VERSION "PrivateInfoCAN"

NS_ :

BS_ :

BU_ :  AUD ETC IHU PDCM

BO_ 896 AUDInfoCanFr01 : 8 AUD
 SG_ AcoustModSts : 7|2@0+ (1,0) [0|3] "" IHU
 SG_ AcoustModSts_UB : 38|1@0+ (1,0) [0|1] "" IHU
 SG_ AudioMuteSts : 15|1@0+ (1,0) [0|1] "" IHU
 SG_ AudioMuteSts_UB : 63|1@0+ (1,0) [0|1] "" IHU
 SG_ BalLvlSts : 4|5@0+ (1.0,0.0) [0.0|31.0] "Unitless" IHU
 SG_ BalLvlSts_UB : 5|1@0+ (1,0) [0|1] "" IHU
 SG_ FaderLvlSts : 12|5@0+ (1.0,0.0) [0.0|31.0] "Unitless" IHU
 SG_ FaderLvlSts_UB : 13|1@0+ (1,0) [0|1] "" IHU
 SG_ Fgrnd1stForActvtSts : 23|1@0+ (1,0) [0|1] "" IHU
 SG_ Fgrnd1stForActvtSts_UB : 62|1@0+ (1,0) [0|1] "" IHU
 SG_ Fgrnd2ndForActvtSts : 31|1@0+ (1,0) [0|1] "" IHU
 SG_ Fgrnd2ndForActvtSts_UB : 61|1@0+ (1,0) [0|1] "" IHU
 SG_ LvlOfBassSts : 20|5@0+ (1.0,0.0) [0.0|31.0] "Unitless" IHU
 SG_ LvlOfBassSts_UB : 21|1@0+ (1,0) [0|1] "" IHU
 SG_ LvlOfMidSts : 28|5@0+ (1.0,0.0) [0.0|31.0] "Unitless" IHU
 SG_ LvlOfMidSts_UB : 29|1@0+ (1,0) [0|1] "" IHU
 SG_ LvlOfTrebleSts : 36|5@0+ (1.0,0.0) [0.0|31.0] "Unitless" IHU
 SG_ LvlOfTrebleSts_UB : 37|1@0+ (1,0) [0|1] "" IHU
 SG_ RoomModeSts : 47|4@0+ (1,0) [0|15] "" IHU
 SG_ RoomModeSts_UB : 39|1@0+ (1,0) [0|1] "" IHU
 SG_ SeatSoundPosnSts : 55|3@0+ (1.0,0.0) [0.0|7.0] "Unitless" IHU
 SG_ SeatSoundPosnSts_UB : 52|1@0+ (1,0) [0|1] "" IHU
 SG_ VehSpdLvlSts : 51|3@0+ (1.0,0.0) [0.0|7.0] "Unitless" IHU
 SG_ VehSpdLvlSts_UB : 48|1@0+ (1,0) [0|1] "" IHU

BO_ 897 AUDInfoCanFr02 : 8 AUD
 SG_ BgrndForAudOutChSts_UB : 57|1@0+ (1,0) [0|1] "" IHU
 SG_ BgrndForAudOutChStsAudOutpCh1 : 32|1@0+ (1,0) [0|1] "" IHU
 SG_ BgrndForAudOutChStsAudOutpCh10 : 36|1@0+ (1,0) [0|1] "" IHU
 SG_ BgrndForAudOutChStsAudOutpCh11 : 34|1@0+ (1,0) [0|1] "" IHU
 SG_ BgrndForAudOutChStsAudOutpCh12 : 33|1@0+ (1,0) [0|1] "" IHU
 SG_ BgrndForAudOutChStsAudOutpCh2 : 39|1@0+ (1,0) [0|1] "" IHU
 SG_ BgrndForAudOutChStsAudOutpCh3 : 46|1@0+ (1,0) [0|1] "" IHU
 SG_ BgrndForAudOutChStsAudOutpCh4 : 38|1@0+ (1,0) [0|1] "" IHU
 SG_ BgrndForAudOutChStsAudOutpCh5 : 44|1@0+ (1,0) [0|1] "" IHU
 SG_ BgrndForAudOutChStsAudOutpCh6 : 45|1@0+ (1,0) [0|1] "" IHU
 SG_ BgrndForAudOutChStsAudOutpCh7 : 47|1@0+ (1,0) [0|1] "" IHU
 SG_ BgrndForAudOutChStsAudOutpCh8 : 37|1@0+ (1,0) [0|1] "" IHU
 SG_ BgrndForAudOutChStsAudOutpCh9 : 35|1@0+ (1,0) [0|1] "" IHU
 SG_ Fgrnd1stForAudOutpChSts_UB : 56|1@0+ (1,0) [0|1] "" IHU
 SG_ Fgrnd1stForAudOutpChStsAudOutpCh1 : 54|1@0+ (1,0) [0|1] "" IHU
 SG_ Fgrnd1stForAudOutpChStsAudOutpCh10 : 49|1@0+ (1,0) [0|1] "" IHU
 SG_ Fgrnd1stForAudOutpChStsAudOutpCh11 : 55|1@0+ (1,0) [0|1] "" IHU
 SG_ Fgrnd1stForAudOutpChStsAudOutpCh12 : 48|1@0+ (1,0) [0|1] "" IHU
 SG_ Fgrnd1stForAudOutpChStsAudOutpCh2 : 42|1@0+ (1,0) [0|1] "" IHU
 SG_ Fgrnd1stForAudOutpChStsAudOutpCh3 : 53|1@0+ (1,0) [0|1] "" IHU
 SG_ Fgrnd1stForAudOutpChStsAudOutpCh4 : 43|1@0+ (1,0) [0|1] "" IHU
 SG_ Fgrnd1stForAudOutpChStsAudOutpCh5 : 52|1@0+ (1,0) [0|1] "" IHU
 SG_ Fgrnd1stForAudOutpChStsAudOutpCh6 : 51|1@0+ (1,0) [0|1] "" IHU
 SG_ Fgrnd1stForAudOutpChStsAudOutpCh7 : 50|1@0+ (1,0) [0|1] "" IHU
 SG_ Fgrnd1stForAudOutpChStsAudOutpCh8 : 41|1@0+ (1,0) [0|1] "" IHU
 SG_ Fgrnd1stForAudOutpChStsAudOutpCh9 : 40|1@0+ (1,0) [0|1] "" IHU
 SG_ Fgrnd1stForVolLvlSts : 7|8@0+ (1.0,0.0) [0.0|255.0] "Unitless" IHU
 SG_ Fgrnd1stForVolLvlSts_UB : 22|1@0+ (1,0) [0|1] "" IHU
 SG_ Fgrnd2ndForAudOutpChSts_UB : 20|1@0+ (1,0) [0|1] "" IHU
 SG_ Fgrnd2ndForAudOutpChStsAudOutpCh1 : 19|1@0+ (1,0) [0|1] "" IHU
 SG_ Fgrnd2ndForAudOutpChStsAudOutpCh10 : 26|1@0+ (1,0) [0|1] "" IHU
 SG_ Fgrnd2ndForAudOutpChStsAudOutpCh11 : 25|1@0+ (1,0) [0|1] "" IHU
 SG_ Fgrnd2ndForAudOutpChStsAudOutpCh12 : 24|1@0+ (1,0) [0|1] "" IHU
 SG_ Fgrnd2ndForAudOutpChStsAudOutpCh2 : 18|1@0+ (1,0) [0|1] "" IHU
 SG_ Fgrnd2ndForAudOutpChStsAudOutpCh3 : 17|1@0+ (1,0) [0|1] "" IHU
 SG_ Fgrnd2ndForAudOutpChStsAudOutpCh4 : 16|1@0+ (1,0) [0|1] "" IHU
 SG_ Fgrnd2ndForAudOutpChStsAudOutpCh5 : 31|1@0+ (1,0) [0|1] "" IHU
 SG_ Fgrnd2ndForAudOutpChStsAudOutpCh6 : 30|1@0+ (1,0) [0|1] "" IHU
 SG_ Fgrnd2ndForAudOutpChStsAudOutpCh7 : 29|1@0+ (1,0) [0|1] "" IHU
 SG_ Fgrnd2ndForAudOutpChStsAudOutpCh8 : 28|1@0+ (1,0) [0|1] "" IHU
 SG_ Fgrnd2ndForAudOutpChStsAudOutpCh9 : 27|1@0+ (1,0) [0|1] "" IHU
 SG_ Fgrnd2ndForVolLvlSts : 15|8@0+ (1.0,0.0) [0.0|255.0] "Unitless" IHU
 SG_ Fgrnd2ndForVolLvlSts_UB : 23|1@0+ (1,0) [0|1] "" IHU

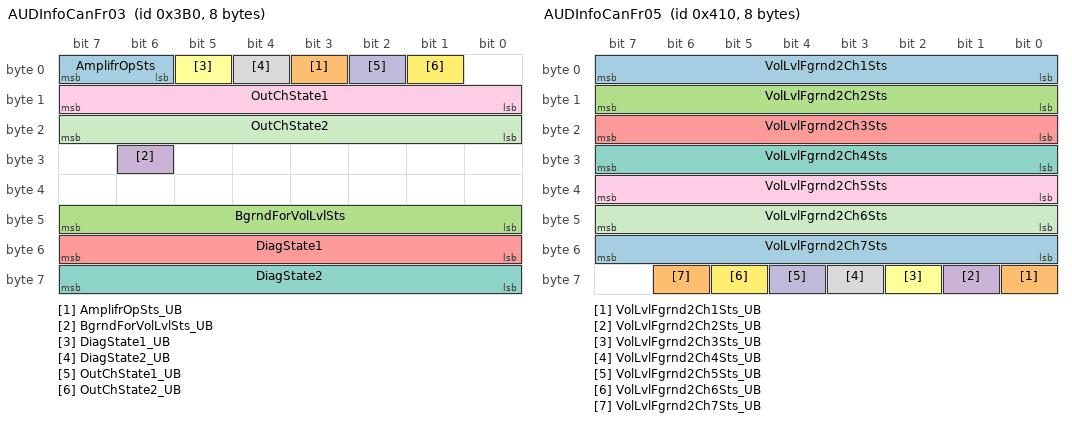
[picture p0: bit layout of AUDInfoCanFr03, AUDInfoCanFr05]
BO_ 944 AUDInfoCanFr03 : 8 AUD
 SG_ AmplifrOpSts : 7|2@0+ (1,0) [0|3] "" IHU
 SG_ AmplifrOpSts_UB : 3|1@0+ (1,0) [0|1] "" IHU
 SG_ BgrndForVolLvlSts : 47|8@0+ (1.0,0.0) [0.0|255.0] "Unitless" IHU
 SG_ BgrndForVolLvlSts_UB : 30|1@0+ (1,0) [0|1] "" IHU
 SG_ DiagState1 : 55|8@0+ (1.0,0.0) [0.0|255.0] "Unitless" IHU
 SG_ DiagState1_UB : 5|1@0+ (1,0) [0|1] "" IHU
 SG_ DiagState2 : 63|8@0+ (1.0,0.0) [0.0|255.0] "Unitless" IHU
 SG_ DiagState2_UB : 4|1@0+ (1,0) [0|1] "" IHU
 SG_ OutChState1 : 15|8@0+ (1.0,0.0) [0.0|255.0] "Unitless" IHU
 SG_ OutChState1_UB : 2|1@0+ (1,0) [0|1] "" IHU
 SG_ OutChState2 : 23|8@0+ (1.0,0.0) [0.0|255.0] "Unitless" IHU
 SG_ OutChState2_UB : 1|1@0+ (1,0) [0|1] "" IHU

BO_ 912 AUDInfoCanFr04 : 8 AUD
 SG_ ArtificialSoundPreviewSts : 53|2@0+ (1,0) [0|3] "" IHU
 SG_ ArtificialSoundPreviewSts_UB : 54|1@0+ (1,0) [0|1] "" IHU
 SG_ Chiming1MuteSts : 35|1@0+ (1,0) [0|1] "" IHU
 SG_ Chiming1MuteSts_UB : 47|1@0+ (1,0) [0|1] "" IHU
 SG_ Chiming2MuteSts : 34|1@0+ (1,0) [0|1] "" IHU
 SG_ Chiming2MuteSts_UB : 46|1@0+ (1,0) [0|1] "" IHU
 SG_ Chiming3MuteSts : 33|1@0+ (1,0) [0|1] "" IHU
 SG_ Chiming3MuteSts_UB : 45|1@0+ (1,0) [0|1] "" IHU
 SG_ Chiming4MuteSts : 32|1@0+ (1,0) [0|1] "" IHU
 SG_ Chiming4MuteSts_UB : 44|1@0+ (1,0) [0|1] "" IHU
 SG_ GearBoxTypToAmplfrSts : 63|8@0+ (1.0,0.0) [0.0|255.0] "Unitless" IHU
 SG_ GearBoxTypToAmplfrSts_UB : 51|1@0+ (1,0) [0|1] "" IHU
 SG_ SeatMtrlToAmplfrSts : 7|8@0+ (1.0,0.0) [0.0|255.0] "Unitless" IHU
 SG_ SeatMtrlToAmplfrSts_UB : 39|1@0+ (1,0) [0|1] "" IHU
 SG_ SeatNrToAmplfrSts : 15|8@0+ (1.0,0.0) [0.0|255.0] "Unitless" IHU
 SG_ SeatNrToAmplfrSts_UB : 38|1@0+ (1,0) [0|1] "" IHU
 SG_ SpkrandAmplifrVariantTypeSts : 23|8@0+ (1.0,0.0) [0.0|255.0] "Unitless" IHU
 SG_ SpkrandAmplifrVariantTypeSts_UB : 37|1@0+ (1,0) [0|1] "" IHU
 SG_ TrdRowSeatMtrlToAmplfrSts : 31|8@0+ (1.0,0.0) [0.0|255.0] "Unitless" IHU
 SG_ TrdRowSeatMtrlToAmplfrSts_UB : 36|1@0+ (1,0) [0|1] "" IHU
 SG_ WarnIntrptLoglDHUSts : 43|4@0+ (1.0,0.0) [0.0|15.0] "Unitless" IHU
 SG_ WarnIntrptLoglDHUSts_UB : 55|1@0+ (1,0) [0|1] "" IHU

BO_ 1040 AUDInfoCanFr05 : 8 AUD
 SG_ VolLvlFgrnd2Ch1Sts : 7|8@0+ (1.0,0.0) [0.0|255.0] "Unitless" IHU
 SG_ VolLvlFgrnd2Ch1Sts_UB : 56|1@0+ (1,0) [0|1] "" IHU
 SG_ VolLvlFgrnd2Ch2Sts : 15|8@0+ (1.0,0.0) [0.0|255.0] "Unitless" IHU
 SG_ VolLvlFgrnd2Ch2Sts_UB : 57|1@0+ (1,0) [0|1] "" IHU
 SG_ VolLvlFgrnd2Ch3Sts : 23|8@0+ (1.0,0.0) [0.0|255.0] "Unitless" IHU
 SG_ VolLvlFgrnd2Ch3Sts_UB : 58|1@0+ (1,0) [0|1] "" IHU
 SG_ VolLvlFgrnd2Ch4Sts : 31|8@0+ (1.0,0.0) [0.0|255.0] "Unitless" IHU
 SG_ VolLvlFgrnd2Ch4Sts_UB : 59|1@0+ (1,0) [0|1] "" IHU
 SG_ VolLvlFgrnd2Ch5Sts : 39|8@0+ (1.0,0.0) [0.0|255.0] "Unitless" IHU
 SG_ VolLvlFgrnd2Ch5Sts_UB : 60|1@0+ (1,0) [0|1] "" IHU
 SG_ VolLvlFgrnd2Ch6Sts : 47|8@0+ (1.0,0.0) [0.0|255.0] "Unitless" IHU
 SG_ VolLvlFgrnd2Ch6Sts_UB : 61|1@0+ (1,0) [0|1] "" IHU
 SG_ VolLvlFgrnd2Ch7Sts : 55|8@0+ (1.0,0.0) [0.0|255.0] "Unitless" IHU
 SG_ VolLvlFgrnd2Ch7Sts_UB : 62|1@0+ (1,0) [0|1] "" IHU

BO_ 80 AUDInfoCanFr06 : 8 AUD
 SG_ AcoustEfectPrvtCinePsnSts : 55|2@0+ (1,0) [0|3] "" IHU
 SG_ AcoustEfectPrvtCinePsnSts_UB : 53|1@0+ (1,0) [0|1] "" IHU
 SG_ BgrndForActvtSts : 51|1@0+ (1,0) [0|1] "" IHU
 SG_ BgrndForActvtSts_UB : 57|1@0+ (1,0) [0|1] "" IHU
 SG_ CptAdvExtSwtSts : 63|2@0+ (1,0) [0|3] "" IHU
 SG_ CptAdvExtSwtSts_UB : 56|1@0+ (1,0) [0|1] "" IHU
 SG_ Feedback1SelectSts : 47|4@0+ (1,0) [0|15] "" IHU
 SG_ Feedback1SelectSts_UB : 58|1@0+ (1,0) [0|1] "" IHU
 SG_ Feedback2SelectSts : 43|4@0+ (1,0) [0|15] "" IHU
 SG_ Feedback2SelectSts_UB : 59|1@0+ (1,0) [0|1] "" IHU
 SG_ VolLvlFgrnd2Ch10Sts : 7|8@0+ (1.0,0.0) [0.0|255.0] "Unitless" IHU
 SG_ VolLvlFgrnd2Ch10Sts_UB : 48|1@0+ (1,0) [0|1] "" IHU
 SG_ VolLvlFgrnd2Ch11Sts : 15|8@0+ (1.0,0.0) [0.0|255.0] "Unitless" IHU
 SG_ VolLvlFgrnd2Ch11Sts_UB : 49|1@0+ (1,0) [0|1] "" IHU
 SG_ VolLvlFgrnd2Ch12Sts : 23|8@0+ (1.0,0.0) [0.0|255.0] "Unitless" IHU
 SG_ VolLvlFgrnd2Ch12Sts_UB : 50|1@0+ (1,0) [0|1] "" IHU
 SG_ VolLvlFgrnd2Ch8Sts : 31|8@0+ (1.0,0.0) [0.0|255.0] "Unitless" IHU
 SG_ VolLvlFgrnd2Ch8Sts_UB : 60|1@0+ (1,0) [0|1] "" IHU
 SG_ VolLvlFgrnd2Ch9Sts : 39|8@0+ (1.0,0.0) [0.0|255.0] "Unitless" IHU
 SG_ VolLvlFgrnd2Ch9Sts_UB : 61|1@0+ (1,0) [0|1] "" IHU

BO_ 33 AUDInfoCanFr07 : 8 AUD
 SG_ AllmuteSts : 54|1@0+ (1,0) [0|1] "" IHU
 SG_ AllmuteSts_UB : 53|1@0+ (1,0) [0|1] "" IHU
 SG_ AmplifrErrSts : 19|4@0+ (1.0,0.0) [0.0|15.0] "Unitless" IHU
 SG_ AmplifrErrSts_UB : 48|1@0+ (1,0) [0|1] "" IHU
 SG_ ArtificialSoundOpenReqSts : 20|1@0+ (1,0) [0|1] "" IHU
 SG_ ArtificialSoundOpenReqSts_UB : 58|1@0+ (1,0) [0|1] "" IHU
 SG_ ArtificialSoundSelectReqSts : 23|3@0+ (1,0) [0|7] "" IHU
 SG_ ArtificialSoundSelectReqSts_UB : 57|1@0+ (1,0) [0|1] "" IHU
 SG_ BdyTypToAmplfrSts : 39|8@0+ (1.0,0.0) [0.0|255.0] "Unitless" IHU
 SG_ BdyTypToAmplfrSts_UB : 56|1@0+ (1,0) [0|1] "" IHU
 SG_ EngTypToAmplfrSts : 47|8@0+ (1.0,0.0) [0.0|255.0] "Unitless" IHU
 SG_ EngTypToAmplfrSts_UB : 55|1@0+ (1,0) [0|1] "" IHU
 SG_ NaviMuteSts : 52|1@0+ (1,0) [0|1] "" IHU
 SG_ NaviMuteSts_UB : 51|1@0+ (1,0) [0|1] "" IHU
 SG_ PrpsnTypToAmplfrSts : 31|4@0+ (1.0,0.0) [0.0|15.0] "Unitless" IHU
 SG_ PrpsnTypToAmplfrSts_UB : 11|1@0+ (1,0) [0|1] "" IHU
 SG_ SteerWhlPosnToAmplfrSts : 7|8@0+ (1.0,0.0) [0.0|255.0] "Unitless" IHU
 SG_ SteerWhlPosnToAmplfrSts_UB : 60|1@0+ (1,0) [0|1] "" IHU
 SG_ TeleMuteSts : 50|1@0+ (1,0) [0|1] "" IHU
 SG_ TeleMuteSts_UB : 49|1@0+ (1,0) [0|1] "" IHU

BO_ 949 AUDInfoCanFr08 : 8 AUD
 SG_ OutChState3 : 7|8@0+ (1.0,0.0) [0.0|255.0] "Unitless" IHU
 SG_ OutChState3_UB : 23|1@0+ (1,0) [0|1] "" IHU
 SG_ OutChState4 : 15|8@0+ (1.0,0.0) [0.0|255.0] "Unitless" IHU
 SG_ OutChState4_UB : 22|1@0+ (1,0) [0|1] "" IHU
 SG_ VolLvlFgrnd0Sts : 31|8@0+ (1.0,0.0) [0.0|255.0] "Unitless" IHU
 SG_ VolLvlFgrnd0Sts_UB : 21|1@0+ (1,0) [0|1] "" IHU

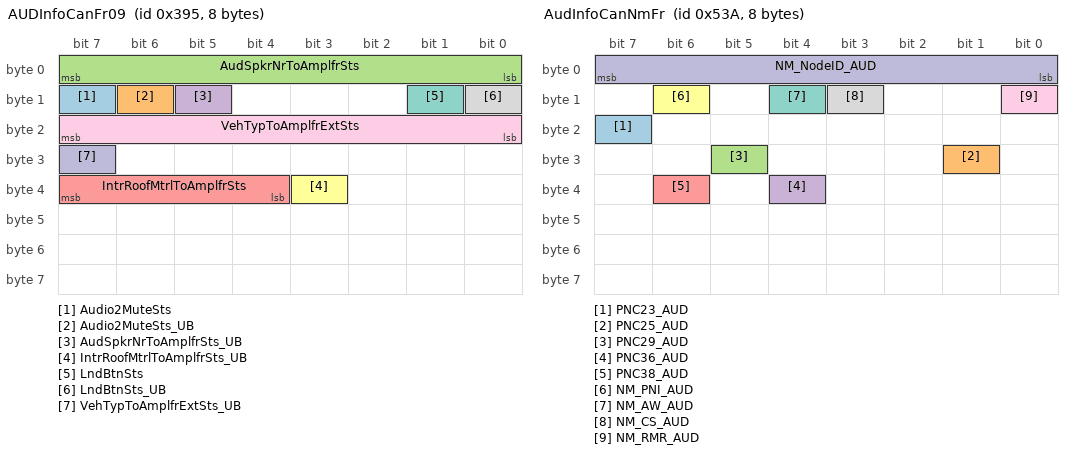
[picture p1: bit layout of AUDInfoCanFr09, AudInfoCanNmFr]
BO_ 917 AUDInfoCanFr09 : 8 AUD
 SG_ Audio2MuteSts : 15|1@0+ (1,0) [0|1] "" IHU
 SG_ Audio2MuteSts_UB : 14|1@0+ (1,0) [0|1] "" IHU
 SG_ AudSpkrNrToAmplfrSts : 7|8@0+ (1.0,0.0) [0.0|255.0] "Unitless" IHU
 SG_ AudSpkrNrToAmplfrSts_UB : 13|1@0+ (1,0) [0|1] "" IHU
 SG_ IntrRoofMtrlToAmplfrSts : 39|4@0+ (1.0,0.0) [0.0|15.0] "Unitless" IHU
 SG_ IntrRoofMtrlToAmplfrSts_UB : 35|1@0+ (1,0) [0|1] "" IHU
 SG_ LndBtnSts : 9|1@0+ (1,0) [0|1] "" IHU
 SG_ LndBtnSts_UB : 8|1@0+ (1,0) [0|1] "" IHU
 SG_ VehTypToAmplfrExtSts : 23|8@0+ (1.0,0.0) [0.0|255.0] "Unitless" IHU
 SG_ VehTypToAmplfrExtSts_UB : 31|1@0+ (1,0) [0|1] "" IHU

BO_ 293 AUDInfoCanFr11 : 8 AUD
 SG_ VolLvlA7Sts : 7|8@0+ (1.0,0.0) [0.0|255.0] "Unitless" IHU
 SG_ VolLvlA7Sts_UB : 23|1@0+ (1,0) [0|1] "" IHU
 SG_ VolLvlA8Sts : 15|8@0+ (1.0,0.0) [0.0|255.0] "Unitless" IHU
 SG_ VolLvlA8Sts_UB : 22|1@0+ (1,0) [0|1] "" IHU

BO_ 1338 AudInfoCanNmFr : 8 AUD
 SG_ PNC23_AUD : 23|1@0+ (1,0) [0|0] "" Vector__XXX
 SG_ PNC25_AUD : 25|1@0+ (1,0) [0|0] "" Vector__XXX
 SG_ PNC29_AUD : 29|1@0+ (1,0) [0|0] "" Vector__XXX
 SG_ PNC36_AUD : 36|1@0+ (1,0) [0|0] "" Vector__XXX
 SG_ PNC38_AUD : 38|1@0+ (1,0) [0|0] "" Vector__XXX
 SG_ NM_PNI_AUD : 14|1@0+ (1,0) [0|0] "" Vector__XXX
 SG_ NM_AW_AUD : 12|1@0+ (1,0) [0|0] "" Vector__XXX
 SG_ NM_CS_AUD : 11|1@0+ (1,0) [0|0] "" Vector__XXX
 SG_ NM_RMR_AUD : 8|1@0+ (1,0) [0|0] "" Vector__XXX
 SG_ NM_NodeID_AUD : 7|8@0+ (1,0) [0|0] "" Vector__XXX

BO_ 1554 AudToDhuInfoCanDiagResFrame : 8 AUD

BO_ 820 CemBodyFr93 : 8 IHU
 SG_ ExtrLtgSts_UB : 4|1@0+ (1,0) [0|1] "" Vector__XXX
 SG_ ExtrLtgStsAFS : 23|2@0+ (1,0) [0|3] "" Vector__XXX
 SG_ ExtrLtgStsAHBC : 21|2@0+ (1,0) [0|3] "" Vector__XXX
 SG_ ExtrLtgStsAHL : 19|2@0+ (1,0) [0|3] "" Vector__XXX
 SG_ ExtrLtgStsAllWL : 17|2@0+ (1,0) [0|3] "" Vector__XXX
 SG_ ExtrLtgStsApproach : 31|2@0+ (1,0) [0|3] "" Vector__XXX
 SG_ ExtrLtgStsChks : 15|8@0+ (1.0,0.0) [0.0|255.0] "Unitless" Vector__XXX
 SG_ ExtrLtgStsCntr : 3|4@0+ (1.0,0.0) [0.0|15.0] "Unitless" Vector__XXX
 SG_ ExtrLtgStsCornrgLi : 29|2@0+ (1,0) [0|3] "" Vector__XXX
 SG_ ExtrLtgStsDBL : 27|2@0+ (1,0) [0|3] "" Vector__XXX
 SG_ ExtrLtgStsDRL : 25|2@0+ (1,0) [0|3] "" Vector__XXX
 SG_ ExtrLtgStsFlash : 39|2@0+ (1,0) [0|3] "" Vector__XXX
 SG_ ExtrLtgStsFrntFog : 37|2@0+ (1,0) [0|3] "" Vector__XXX
 SG_ ExtrLtgStsGoodbye : 35|2@0+ (1,0) [0|3] "" Vector__XXX
 SG_ ExtrLtgStsHiBeam : 33|2@0+ (1,0) [0|3] "" Vector__XXX
 SG_ ExtrLtgStsHomeSafe : 47|2@0+ (1,0) [0|3] "" Vector__XXX
 SG_ ExtrLtgStsHWL : 45|2@0+ (1,0) [0|3] "" Vector__XXX
 SG_ ExtrLtgStsLoBeam : 43|2@0+ (1,0) [0|3] "" Vector__XXX
 SG_ ExtrLtgStsLtgShow : 41|2@0+ (1,0) [0|3] "" Vector__XXX
 SG_ ExtrLtgStsPosLiFrnt : 55|2@0+ (1,0) [0|3] "" Vector__XXX
 SG_ ExtrLtgStsPosLiRe : 53|2@0+ (1,0) [0|3] "" Vector__XXX
 SG_ ExtrLtgStsReFog : 51|2@0+ (1,0) [0|3] "" Vector__XXX
 SG_ ExtrLtgStsReverseLi : 49|2@0+ (1,0) [0|3] "" Vector__XXX
 SG_ ExtrLtgStsStopLi : 63|2@0+ (1,0) [0|3] "" Vector__XXX
 SG_ ExtrLtgStsTurnIndrLe : 61|2@0+ (1,0) [0|3] "" Vector__XXX
 SG_ ExtrLtgStsTurnIndrRi : 59|2@0+ (1,0) [0|3] "" Vector__XXX
 SG_ ExtrLtgStsWelcome : 57|2@0+ (1,0) [0|3] "" Vector__XXX

BO_ 398 DhuInfoCanFr05 : 8 IHU
 SG_ BrkPedlrRat_UB : 45|1@0+ (1,0) [0|1] "" AUD
 SG_ BrkPedlrRatPerc : 30|15@0+ (0.00390625,0.0) [0.0|100.0] "%" AUD
 SG_ BrkPedlrRatQf : 47|2@0+ (1,0) [0|3] "" AUD

BO_ 368 DhuInfoCanFr06 : 8 IHU
 SG_ CptAdvExtSwt : 32|1@0+ (1,0) [0|1] "" AUD
 SG_ CptAdvExtSwt_UB : 33|1@0+ (1,0) [0|1] "" AUD

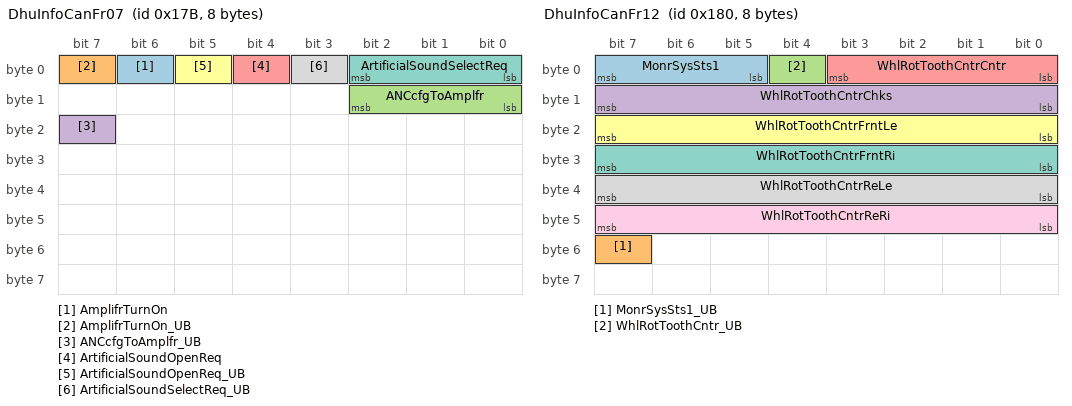
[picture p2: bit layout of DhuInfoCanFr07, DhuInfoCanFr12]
BO_ 379 DhuInfoCanFr07 : 8 IHU
 SG_ AmplifrTurnOn : 6|1@0+ (1,0) [0|1] "" AUD
 SG_ AmplifrTurnOn_UB : 7|1@0+ (1,0) [0|1] "" AUD
 SG_ ANCcfgToAmplfr : 10|3@0+ (1,0) [0|7] "" AUD
 SG_ ANCcfgToAmplfr_UB : 23|1@0+ (1,0) [0|1] "" AUD
 SG_ ArtificialSoundOpenReq : 4|1@0+ (1,0) [0|1] "" AUD
 SG_ ArtificialSoundOpenReq_UB : 5|1@0+ (1,0) [0|1] "" AUD
 SG_ ArtificialSoundSelectReq : 2|3@0+ (1,0) [0|7] "" AUD
 SG_ ArtificialSoundSelectReq_UB : 3|1@0+ (1,0) [0|1] "" AUD

BO_ 399 DhuInfoCanFr08 : 8 IHU
 SG_ Allmute : 47|1@0+ (1,0) [0|1] "" AUD
 SG_ Allmute_UB : 46|1@0+ (1,0) [0|1] "" AUD
 SG_ Chiming1Mute : 45|1@0+ (1,0) [0|1] "" AUD
 SG_ Chiming1Mute_UB : 44|1@0+ (1,0) [0|1] "" AUD
 SG_ Chiming2Mute : 33|1@0+ (1,0) [0|1] "" AUD
 SG_ Chiming2Mute_UB : 32|1@0+ (1,0) [0|1] "" AUD
 SG_ Chiming3Mute : 35|1@0+ (1,0) [0|1] "" AUD
 SG_ Chiming3Mute_UB : 34|1@0+ (1,0) [0|1] "" AUD
 SG_ Chiming4Mute : 37|1@0+ (1,0) [0|1] "" AUD
 SG_ Chiming4Mute_UB : 36|1@0+ (1,0) [0|1] "" AUD
 SG_ NaviMute : 39|1@0+ (1,0) [0|1] "" AUD
 SG_ NaviMute_UB : 38|1@0+ (1,0) [0|1] "" AUD
 SG_ TeleMute : 28|1@0+ (1,0) [0|1] "" AUD
 SG_ TeleMute_UB : 29|1@0+ (1,0) [0|1] "" AUD
 SG_ VolLvlFgrnd0 : 23|8@0+ (1.0,0.0) [0.0|255.0] "Unitless" AUD
 SG_ VolLvlFgrnd0_UB : 30|1@0+ (1,0) [0|1] "" AUD
 SG_ WarnIntrptLoglDHU : 27|4@0+ (1.0,0.0) [0.0|15.0] "Unitless" AUD
 SG_ WarnIntrptLoglDHU_UB : 31|1@0+ (1,0) [0|1] "" AUD

BO_ 384 DhuInfoCanFr12 : 8 IHU
 SG_ MonrSysSts1 : 7|3@0+ (1,0) [0|7] "" PDCM
 SG_ MonrSysSts1_UB : 55|1@0+ (1,0) [0|1] "" PDCM
 SG_ WhlRotToothCntr_UB : 4|1@0+ (1,0) [0|1] "" PDCM
 SG_ WhlRotToothCntrChks : 15|8@0+ (1.0,0.0) [0.0|255.0] "Unitless" PDCM
 SG_ WhlRotToothCntrCntr : 3|4@0+ (1.0,0.0) [0.0|15.0] "Unitless" PDCM
 SG_ WhlRotToothCntrFrntLe : 23|8@0+ (1.0,0.0) [0.0|255.0] "Unitless" PDCM
 SG_ WhlRotToothCntrFrntRi : 31|8@0+ (1.0,0.0) [0.0|255.0] "Unitless" PDCM
 SG_ WhlRotToothCntrReLe : 39|8@0+ (1.0,0.0) [0.0|255.0] "Unitless" PDCM
 SG_ WhlRotToothCntrReRi : 47|8@0+ (1.0,0.0) [0.0|255.0] "Unitless" PDCM

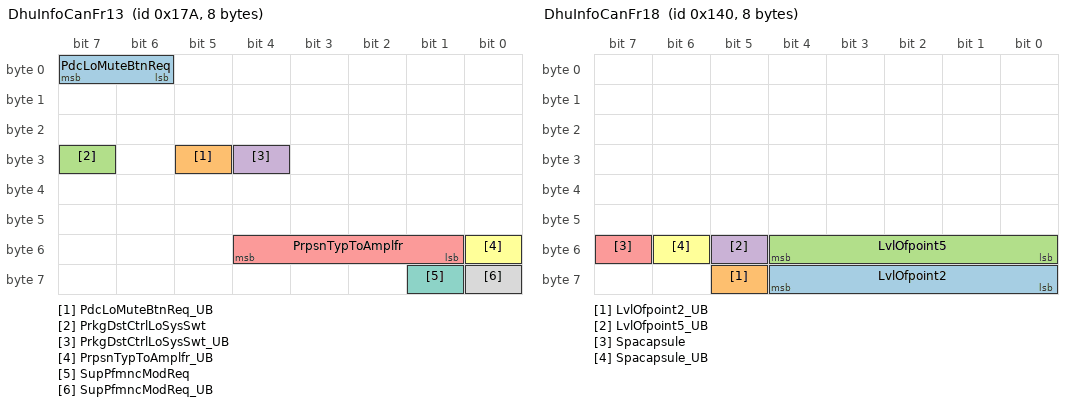
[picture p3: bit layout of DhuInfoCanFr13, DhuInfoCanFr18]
BO_ 378 DhuInfoCanFr13 : 8 IHU
 SG_ PdcLoMuteBtnReq : 7|2@0+ (1,0) [0|3] "" PDCM
 SG_ PdcLoMuteBtnReq_UB : 29|1@0+ (1,0) [0|1] "" PDCM
 SG_ PrkgDstCtrlLoSysSwt : 31|1@0+ (1,0) [0|1] "" PDCM
 SG_ PrkgDstCtrlLoSysSwt_UB : 28|1@0+ (1,0) [0|1] "" PDCM
 SG_ PrpsnTypToAmplfr : 52|4@0+ (1.0,0.0) [0.0|15.0] "Unitless" AUD
 SG_ PrpsnTypToAmplfr_UB : 48|1@0+ (1,0) [0|1] "" AUD
 SG_ SupPfmncModReq : 57|1@0+ (1,0) [0|1] "" AUD
 SG_ SupPfmncModReq_UB : 56|1@0+ (1,0) [0|1] "" AUD

BO_ 517 DhuInfoCanFr14 : 8 IHU
 SG_ PrkgAssiReSts : 7|3@0+ (1,0) [0|7] "" PDCM
 SG_ PrkgAssiReSts_UB : 4|1@0+ (1,0) [0|1] "" PDCM

BO_ 320 DhuInfoCanFr18 : 8 IHU
 SG_ LvlOfpoint2 : 60|5@0+ (1.0,0.0) [0.0|31.0] "Unitless" AUD
 SG_ LvlOfpoint2_UB : 61|1@0+ (1,0) [0|1] "" AUD
 SG_ LvlOfpoint5 : 52|5@0+ (1.0,0.0) [0.0|31.0] "Unitless" AUD
 SG_ LvlOfpoint5_UB : 53|1@0+ (1,0) [0|1] "" AUD
 SG_ Spacapsule : 55|1@0+ (1,0) [0|1] "" AUD
 SG_ Spacapsule_UB : 54|1@0+ (1,0) [0|1] "" AUD

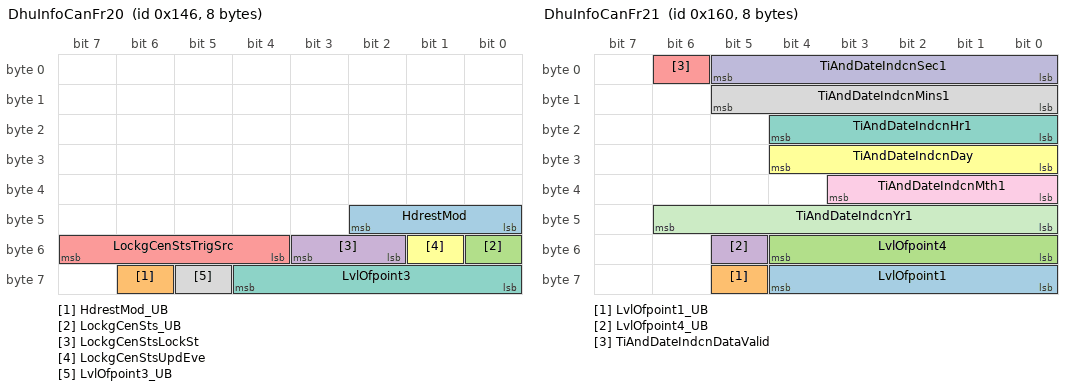
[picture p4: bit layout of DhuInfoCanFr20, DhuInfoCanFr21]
BO_ 326 DhuInfoCanFr20 : 8 IHU
 SG_ HdrestMod : 42|3@0+ (1.0,0.0) [0.0|7.0] "Unitless" AUD
 SG_ HdrestMod_UB : 62|1@0+ (1,0) [0|1] "" AUD
 SG_ LockgCenSts_UB : 48|1@0+ (1,0) [0|1] "" Vector__XXX
 SG_ LockgCenStsLockSt : 51|2@0+ (1,0) [0|3] "" Vector__XXX
 SG_ LockgCenStsTrigSrc : 55|4@0+ (1,0) [0|15] "" Vector__XXX
 SG_ LockgCenStsUpdEve : 49|1@0+ (1,0) [0|1] "" Vector__XXX
 SG_ LvlOfpoint3 : 60|5@0+ (1.0,0.0) [0.0|31.0] "Unitless" AUD
 SG_ LvlOfpoint3_UB : 61|1@0+ (1,0) [0|1] "" AUD

BO_ 352 DhuInfoCanFr21 : 8 IHU
 SG_ LvlOfpoint1 : 60|5@0+ (1.0,0.0) [0.0|31.0] "Unitless" AUD
 SG_ LvlOfpoint1_UB : 61|1@0+ (1,0) [0|1] "" AUD
 SG_ LvlOfpoint4 : 52|5@0+ (1.0,0.0) [0.0|31.0] "Unitless" AUD
 SG_ LvlOfpoint4_UB : 53|1@0+ (1,0) [0|1] "" AUD
 SG_ TiAndDateIndcnDataValid : 6|1@0+ (1,0) [0|1] "" AUD
 SG_ TiAndDateIndcnDay : 28|5@0+ (1.0,0.0) [1.0|31.0] "Days" AUD
 SG_ TiAndDateIndcnHr1 : 20|5@0+ (1.0,0.0) [0.0|23.0] "hours" AUD
 SG_ TiAndDateIndcnMins1 : 13|6@0+ (1.0,0.0) [0.0|59.0] "Mins" AUD
 SG_ TiAndDateIndcnMth1 : 35|4@0+ (1.0,0.0) [1.0|12.0] "Month" AUD
 SG_ TiAndDateIndcnSec1 : 5|6@0+ (1.0,0.0) [0.0|59.0] "s" AUD
 SG_ TiAndDateIndcnYr1 : 46|7@0+ (1.0,0.0) [0.0|99.0] "Year" AUD

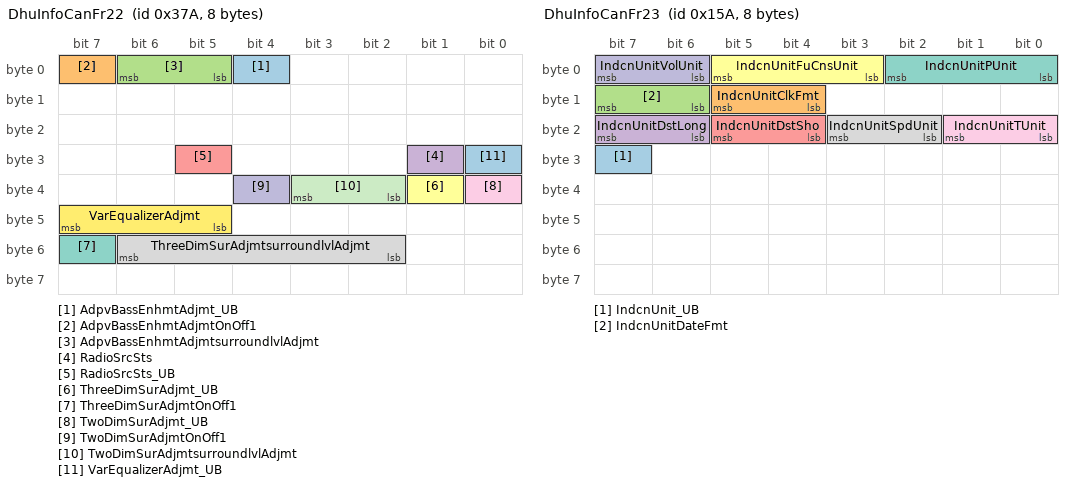
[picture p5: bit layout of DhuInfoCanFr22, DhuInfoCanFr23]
BO_ 890 DhuInfoCanFr22 : 8 IHU
 SG_ AdpvBassEnhmtAdjmt_UB : 4|1@0+ (1,0) [0|1] "" AUD
 SG_ AdpvBassEnhmtAdjmtOnOff1 : 7|1@0+ (1,0) [0|1] "" AUD
 SG_ AdpvBassEnhmtAdjmtsurroundlvlAdjmt : 6|2@0+ (1,0) [0|3] "" AUD
 SG_ RadioSrcSts : 25|1@0+ (1,0) [0|1] "" AUD
 SG_ RadioSrcSts_UB : 29|1@0+ (1,0) [0|1] "" AUD
 SG_ ThreeDimSurAdjmt_UB : 33|1@0+ (1,0) [0|1] "" AUD
 SG_ ThreeDimSurAdjmtOnOff1 : 55|1@0+ (1,0) [0|1] "" AUD
 SG_ ThreeDimSurAdjmtsurroundlvlAdjmt : 54|5@0+ (1,0) [0|31] "" AUD
 SG_ TwoDimSurAdjmt_UB : 32|1@0+ (1,0) [0|1] "" AUD
 SG_ TwoDimSurAdjmtOnOff1 : 36|1@0+ (1,0) [0|1] "" AUD
 SG_ TwoDimSurAdjmtsurroundlvlAdjmt : 35|2@0+ (1,0) [0|3] "" AUD
 SG_ VarEqualizerAdjmt : 47|3@0+ (1,0) [0|7] "" AUD
 SG_ VarEqualizerAdjmt_UB : 24|1@0+ (1,0) [0|1] "" AUD

BO_ 346 DhuInfoCanFr23 : 8 IHU
 SG_ IndcnUnit_UB : 31|1@0+ (1,0) [0|1] "" PDCM
 SG_ IndcnUnitClkFmt : 13|2@0+ (1,0) [0|3] "" PDCM
 SG_ IndcnUnitDateFmt : 15|2@0+ (1,0) [0|3] "" PDCM
 SG_ IndcnUnitDstLong : 23|2@0+ (1,0) [0|3] "" PDCM
 SG_ IndcnUnitDstSho : 21|2@0+ (1,0) [0|3] "" PDCM
 SG_ IndcnUnitFuCnsUnit : 5|3@0+ (1,0) [0|7] "" PDCM
 SG_ IndcnUnitPUnit : 2|3@0+ (1,0) [0|7] "" PDCM
 SG_ IndcnUnitSpdUnit : 19|2@0+ (1,0) [0|3] "" PDCM
 SG_ IndcnUnitTUnit : 17|2@0+ (1,0) [0|3] "" PDCM
 SG_ IndcnUnitVolUnit : 7|2@0+ (1,0) [0|3] "" PDCM

BO_ 353 DhuInfoCanFr35 : 8 IHU
 SG_ MediaSouce : 1|2@0+ (1,0) [0|3] "" AUD
 SG_ MediaSouce_UB : 2|1@0+ (1,0) [0|1] "" AUD
 SG_ PassHdrestSwt : 4|2@0+ (1,0) [0|3] "" AUD
 SG_ PassHdrestSwt_UB : 5|1@0+ (1,0) [0|1] "" AUD
 SG_ PSDConnectBTHeadSetSts : 6|1@0+ (1,0) [0|1] "" AUD
 SG_ PSDConnectBTHeadSetSts_UB : 7|1@0+ (1,0) [0|1] "" AUD
 SG_ PtDrvrSetg : 47|4@0+ (1,0) [0|15] "" AUD
 SG_ PtDrvrSetg_UB : 43|1@0+ (1,0) [0|1] "" AUD
 SG_ RSDLConnectBTHeadSetSts : 8|1@0+ (1,0) [0|1] "" AUD
 SG_ RSDLConnectBTHeadSetSts_UB : 9|1@0+ (1,0) [0|1] "" AUD
 SG_ RSDRConnectBTHeadSetSts : 10|1@0+ (1,0) [0|1] "" AUD
 SG_ RSDRConnectBTHeadSetSts_UB : 11|1@0+ (1,0) [0|1] "" AUD
 SG_ SRDLConnectBTHeadSetSts : 12|1@0+ (1,0) [0|1] "" AUD
 SG_ SRDLConnectBTHeadSetSts_UB : 13|1@0+ (1,0) [0|1] "" AUD
 SG_ SRDRConnectBTHeadSetSts : 14|1@0+ (1,0) [0|1] "" AUD
 SG_ SRDRConnectBTHeadSetSts_UB : 15|1@0+ (1,0) [0|1] "" AUD
 SG_ VirtVenue_UB : 35|1@0+ (1,0) [0|1] "" AUD
 SG_ VirtVenueMod : 39|3@0+ (1,0) [0|7] "" AUD
 SG_ VirtVenueOnOff1 : 36|1@0+ (1,0) [0|1] "" AUD

BO_ 2047 DhuToAllFuncInfoCanDiagReqFrame : 8 IHU

BO_ 1810 DhuToAudInfoCanDiagReqFrame : 8 IHU

BO_ 1813 DhuToEramInfoCanDiagReqFrame : 8 IHU

BO_ 1814 DhuToIlcmPrivateInfoDiagReqFrame1 : 8 IHU

BO_ 1812 DhuToPdcmInfoCanDiagReqFrame : 8 IHU

BO_ 1530 EtcToIlcmXcpFr01 : 8 ETC

BO_ 272 IhuDhuInfoCanFr01 : 8 IHU
 SG_ ActvtFgrnd2 : 7|1@0+ (1,0) [0|1] "" AUD
 SG_ ActvtFgrnd2_UB : 6|1@0+ (1,0) [0|1] "" AUD
 SG_ Audiomode : 43|3@0+ (1,0) [0|7] "" AUD
 SG_ Audiomode_UB : 40|1@0+ (1,0) [0|1] "" AUD
 SG_ Fgrnd2ForAudOutpCh_UB : 27|1@0+ (1,0) [0|1] "" AUD
 SG_ Fgrnd2ForAudOutpChAudOutpCh1 : 22|1@0+ (1,0) [0|1] "" AUD
 SG_ Fgrnd2ForAudOutpChAudOutpCh10 : 30|1@0+ (1,0) [0|1] "" AUD
 SG_ Fgrnd2ForAudOutpChAudOutpCh11 : 31|1@0+ (1,0) [0|1] "" AUD
 SG_ Fgrnd2ForAudOutpChAudOutpCh12 : 28|1@0+ (1,0) [0|1] "" AUD
 SG_ Fgrnd2ForAudOutpChAudOutpCh2 : 17|1@0+ (1,0) [0|1] "" AUD
 SG_ Fgrnd2ForAudOutpChAudOutpCh3 : 18|1@0+ (1,0) [0|1] "" AUD
 SG_ Fgrnd2ForAudOutpChAudOutpCh4 : 23|1@0+ (1,0) [0|1] "" AUD
 SG_ Fgrnd2ForAudOutpChAudOutpCh5 : 19|1@0+ (1,0) [0|1] "" AUD
 SG_ Fgrnd2ForAudOutpChAudOutpCh6 : 21|1@0+ (1,0) [0|1] "" AUD
 SG_ Fgrnd2ForAudOutpChAudOutpCh7 : 20|1@0+ (1,0) [0|1] "" AUD
 SG_ Fgrnd2ForAudOutpChAudOutpCh8 : 16|1@0+ (1,0) [0|1] "" AUD
 SG_ Fgrnd2ForAudOutpChAudOutpCh9 : 29|1@0+ (1,0) [0|1] "" AUD
 SG_ SeatOccptAtRowThrdMid : 1|2@0+ (1,0) [0|3] "" Vector__XXX
 SG_ SeatOccptAtRowThrdMid_UB : 39|1@0+ (1,0) [0|1] "" Vector__XXX
 SG_ VolLvlA7 : 55|8@0+ (1.0,0.0) [0.0|255.0] "Unitless" AUD
 SG_ VolLvlA7_UB : 44|1@0+ (1,0) [0|1] "" AUD
 SG_ VolLvlA8 : 63|8@0+ (1.0,0.0) [0.0|255.0] "Unitless" AUD
 SG_ VolLvlA8_UB : 45|1@0+ (1,0) [0|1] "" AUD

BO_ 913 IhuDhuInfoCanFr02 : 8 IHU
 SG_ AcoustMod : 55|2@0+ (1,0) [0|3] "" AUD
 SG_ AcoustMod_UB : 59|1@0+ (1,0) [0|1] "" AUD
 SG_ ActvtBgrnd : 47|1@0+ (1,0) [0|1] "" AUD
 SG_ ActvtBgrnd_UB : 58|1@0+ (1,0) [0|1] "" AUD
 SG_ DrvrSeatSnsrSts : 9|2@0+ (1,0) [0|3] "" Vector__XXX
 SG_ DrvrSeatSnsrSts_UB : 11|1@0+ (1,0) [0|1] "" Vector__XXX
 SG_ DrvrSeatSts : 39|2@0+ (1,0) [0|3] "" Vector__XXX
 SG_ DrvrSeatSts_UB : 46|1@0+ (1,0) [0|1] "" Vector__XXX
 SG_ FaderLvl : 28|5@0+ (1.0,0.0) [0.0|31.0] "Unitless" AUD
 SG_ FaderLvl_UB : 29|1@0+ (1,0) [0|1] "" AUD
 SG_ Feedback1Select : 7|4@0+ (1,0) [0|15] "" AUD
 SG_ Feedback1Select_UB : 56|1@0+ (1,0) [0|1] "" AUD
 SG_ Feedback2Select : 3|4@0+ (1,0) [0|15] "" AUD
 SG_ Feedback2Select_UB : 31|1@0+ (1,0) [0|1] "" AUD
 SG_ LvlOfBass : 36|5@0+ (1.0,0.0) [0.0|31.0] "Unitless" AUD
 SG_ LvlOfBass_UB : 37|1@0+ (1,0) [0|1] "" AUD
 SG_ LvlOfMid : 44|5@0+ (1.0,0.0) [0.0|31.0] "Unitless" AUD
 SG_ LvlOfMid_UB : 45|1@0+ (1,0) [0|1] "" AUD
 SG_ LvlOfTreble : 52|5@0+ (1.0,0.0) [0.0|31.0] "Unitless" AUD
 SG_ LvlOfTreble_UB : 53|1@0+ (1,0) [0|1] "" AUD
 SG_ RoomMode : 15|4@0+ (1,0) [0|15] "" AUD
 SG_ RoomMode_UB : 30|1@0+ (1,0) [0|1] "" AUD
 SG_ SeatSoundPosn : 63|3@0+ (1.0,0.0) [0.0|7.0] "Unitless" AUD
 SG_ SeatSoundPosn_UB : 60|1@0+ (1,0) [0|1] "" AUD
 SG_ VolLvlBgrnd : 23|8@0+ (1.0,0.0) [0.0|255.0] "Unitless" AUD
 SG_ VolLvlBgrnd_UB : 10|1@0+ (1,0) [0|1] "" AUD

BO_ 336 IhuDhuInfoCanFr03 : 8 IHU
 SG_ ActvtFgrnd1 : 24|1@0+ (1,0) [0|1] "" AUD
 SG_ ActvtFgrnd1_UB : 25|1@0+ (1,0) [0|1] "" AUD
 SG_ AudioMute : 4|1@0+ (1,0) [0|1] "" AUD
 SG_ AudioMute_UB : 3|1@0+ (1,0) [0|1] "" AUD
 SG_ BalLvl : 52|5@0+ (1.0,0.0) [0.0|31.0] "Unitless" AUD
 SG_ BalLvl_UB : 53|1@0+ (1,0) [0|1] "" AUD
 SG_ BgrndForAudOutpCh_UB : 26|1@0+ (1,0) [0|1] "" AUD
 SG_ BgrndForAudOutpChAudOutpCh1 : 35|1@0+ (1,0) [0|1] "" AUD
 SG_ BgrndForAudOutpChAudOutpCh10 : 41|1@0+ (1,0) [0|1] "" AUD
 SG_ BgrndForAudOutpChAudOutpCh11 : 42|1@0+ (1,0) [0|1] "" AUD
 SG_ BgrndForAudOutpChAudOutpCh12 : 40|1@0+ (1,0) [0|1] "" AUD
 SG_ BgrndForAudOutpChAudOutpCh2 : 47|1@0+ (1,0) [0|1] "" AUD
 SG_ BgrndForAudOutpChAudOutpCh3 : 46|1@0+ (1,0) [0|1] "" AUD
 SG_ BgrndForAudOutpChAudOutpCh4 : 34|1@0+ (1,0) [0|1] "" AUD
 SG_ BgrndForAudOutpChAudOutpCh5 : 32|1@0+ (1,0) [0|1] "" AUD
 SG_ BgrndForAudOutpChAudOutpCh6 : 33|1@0+ (1,0) [0|1] "" AUD
 SG_ BgrndForAudOutpChAudOutpCh7 : 44|1@0+ (1,0) [0|1] "" AUD
 SG_ BgrndForAudOutpChAudOutpCh8 : 45|1@0+ (1,0) [0|1] "" AUD
 SG_ BgrndForAudOutpChAudOutpCh9 : 43|1@0+ (1,0) [0|1] "" AUD
 SG_ SpkrandAmplifrVariantType : 63|8@0+ (1.0,0.0) [0.0|255.0] "Unitless" AUD
 SG_ SpkrandAmplifrVariantType_UB : 54|1@0+ (1,0) [0|1] "" AUD
 SG_ VehSpdLvl : 31|2@0+ (1,0) [0|3] "" AUD
 SG_ VehSpdLvl_UB : 29|1@0+ (1,0) [0|1] "" AUD
 SG_ VolLvlFgrnd1 : 15|8@0+ (1.0,0.0) [0.0|255.0] "Unitless" AUD
 SG_ VolLvlFgrnd1_UB : 27|1@0+ (1,0) [0|1] "" AUD

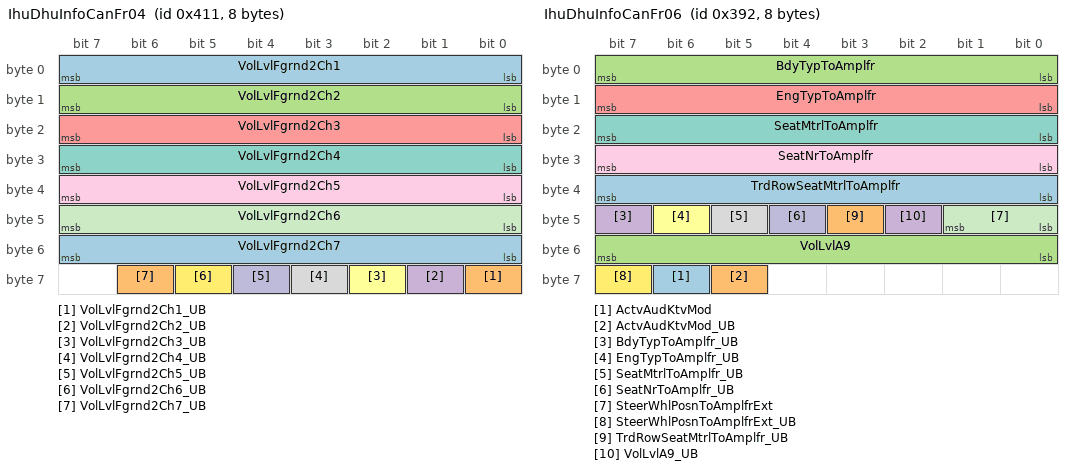
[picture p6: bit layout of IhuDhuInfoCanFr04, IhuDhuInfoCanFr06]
BO_ 1041 IhuDhuInfoCanFr04 : 8 IHU
 SG_ VolLvlFgrnd2Ch1 : 7|8@0+ (1.0,0.0) [0.0|255.0] "Unitless" AUD
 SG_ VolLvlFgrnd2Ch1_UB : 56|1@0+ (1,0) [0|1] "" AUD
 SG_ VolLvlFgrnd2Ch2 : 15|8@0+ (1.0,0.0) [0.0|255.0] "Unitless" AUD
 SG_ VolLvlFgrnd2Ch2_UB : 57|1@0+ (1,0) [0|1] "" AUD
 SG_ VolLvlFgrnd2Ch3 : 23|8@0+ (1.0,0.0) [0.0|255.0] "Unitless" AUD
 SG_ VolLvlFgrnd2Ch3_UB : 58|1@0+ (1,0) [0|1] "" AUD
 SG_ VolLvlFgrnd2Ch4 : 31|8@0+ (1.0,0.0) [0.0|255.0] "Unitless" AUD
 SG_ VolLvlFgrnd2Ch4_UB : 59|1@0+ (1,0) [0|1] "" AUD
 SG_ VolLvlFgrnd2Ch5 : 39|8@0+ (1.0,0.0) [0.0|255.0] "Unitless" AUD
 SG_ VolLvlFgrnd2Ch5_UB : 60|1@0+ (1,0) [0|1] "" AUD
 SG_ VolLvlFgrnd2Ch6 : 47|8@0+ (1.0,0.0) [0.0|255.0] "Unitless" AUD
 SG_ VolLvlFgrnd2Ch6_UB : 61|1@0+ (1,0) [0|1] "" AUD
 SG_ VolLvlFgrnd2Ch7 : 55|8@0+ (1.0,0.0) [0.0|255.0] "Unitless" AUD
 SG_ VolLvlFgrnd2Ch7_UB : 62|1@0+ (1,0) [0|1] "" AUD

BO_ 304 IhuDhuInfoCanFr05 : 8 IHU
 SG_ Fgrnd1ForAudOutpCh_UB : 59|1@0+ (1,0) [0|1] "" AUD
 SG_ Fgrnd1ForAudOutpChAudOutpCh1 : 51|1@0+ (1,0) [0|1] "" AUD
 SG_ Fgrnd1ForAudOutpChAudOutpCh10 : 61|1@0+ (1,0) [0|1] "" AUD
 SG_ Fgrnd1ForAudOutpChAudOutpCh11 : 62|1@0+ (1,0) [0|1] "" AUD
 SG_ Fgrnd1ForAudOutpChAudOutpCh12 : 63|1@0+ (1,0) [0|1] "" AUD
 SG_ Fgrnd1ForAudOutpChAudOutpCh2 : 54|1@0+ (1,0) [0|1] "" AUD
 SG_ Fgrnd1ForAudOutpChAudOutpCh3 : 52|1@0+ (1,0) [0|1] "" AUD
 SG_ Fgrnd1ForAudOutpChAudOutpCh4 : 48|1@0+ (1,0) [0|1] "" AUD
 SG_ Fgrnd1ForAudOutpChAudOutpCh5 : 49|1@0+ (1,0) [0|1] "" AUD
 SG_ Fgrnd1ForAudOutpChAudOutpCh6 : 50|1@0+ (1,0) [0|1] "" AUD
 SG_ Fgrnd1ForAudOutpChAudOutpCh7 : 55|1@0+ (1,0) [0|1] "" AUD
 SG_ Fgrnd1ForAudOutpChAudOutpCh8 : 53|1@0+ (1,0) [0|1] "" AUD
 SG_ Fgrnd1ForAudOutpChAudOutpCh9 : 60|1@0+ (1,0) [0|1] "" AUD
 SG_ NotifForEmgyCall : 58|1@0+ (1,0) [0|1] "" Vector__XXX
 SG_ NotifForEmgyCall_UB : 57|1@0+ (1,0) [0|1] "" Vector__XXX
 SG_ VolLvlFgrnd2Ch10 : 23|8@0+ (1.0,0.0) [0.0|255.0] "Unitless" AUD
 SG_ VolLvlFgrnd2Ch10_UB : 42|1@0+ (1,0) [0|1] "" AUD
 SG_ VolLvlFgrnd2Ch11 : 31|8@0+ (1.0,0.0) [0.0|255.0] "Unitless" AUD
 SG_ VolLvlFgrnd2Ch11_UB : 43|1@0+ (1,0) [0|1] "" AUD
 SG_ VolLvlFgrnd2Ch12 : 39|8@0+ (1.0,0.0) [0.0|255.0] "Unitless" AUD
 SG_ VolLvlFgrnd2Ch12_UB : 44|1@0+ (1,0) [0|1] "" AUD
 SG_ VolLvlFgrnd2Ch8 : 7|8@0+ (1.0,0.0) [0.0|255.0] "Unitless" AUD
 SG_ VolLvlFgrnd2Ch8_UB : 40|1@0+ (1,0) [0|1] "" AUD
 SG_ VolLvlFgrnd2Ch9 : 15|8@0+ (1.0,0.0) [0.0|255.0] "Unitless" AUD
 SG_ VolLvlFgrnd2Ch9_UB : 41|1@0+ (1,0) [0|1] "" AUD

BO_ 914 IhuDhuInfoCanFr06 : 8 IHU
 SG_ ActvAudKtvMod : 62|1@0+ (1,0) [0|1] "" AUD
 SG_ ActvAudKtvMod_UB : 61|1@0+ (1,0) [0|1] "" AUD
 SG_ BdyTypToAmplfr : 7|8@0+ (1.0,0.0) [0.0|255.0] "Unitless" AUD
 SG_ BdyTypToAmplfr_UB : 47|1@0+ (1,0) [0|1] "" AUD
 SG_ EngTypToAmplfr : 15|8@0+ (1.0,0.0) [0.0|255.0] "Unitless" AUD
 SG_ EngTypToAmplfr_UB : 46|1@0+ (1,0) [0|1] "" AUD
 SG_ SeatMtrlToAmplfr : 23|8@0+ (1.0,0.0) [0.0|255.0] "Unitless" AUD
 SG_ SeatMtrlToAmplfr_UB : 45|1@0+ (1,0) [0|1] "" AUD
 SG_ SeatNrToAmplfr : 31|8@0+ (1.0,0.0) [0.0|255.0] "Unitless" AUD
 SG_ SeatNrToAmplfr_UB : 44|1@0+ (1,0) [0|1] "" AUD
 SG_ SteerWhlPosnToAmplfrExt : 41|2@0+ (1.0,0.0) [0.0|3.0] "Unitless" AUD
 SG_ SteerWhlPosnToAmplfrExt_UB : 63|1@0+ (1,0) [0|1] "" AUD
 SG_ TrdRowSeatMtrlToAmplfr : 39|8@0+ (1.0,0.0) [0.0|255.0] "Unitless" AUD
 SG_ TrdRowSeatMtrlToAmplfr_UB : 43|1@0+ (1,0) [0|1] "" AUD
 SG_ VolLvlA9 : 55|8@0+ (1.0,0.0) [0.0|255.0] "Unitless" AUD
 SG_ VolLvlA9_UB : 42|1@0+ (1,0) [0|1] "" AUD

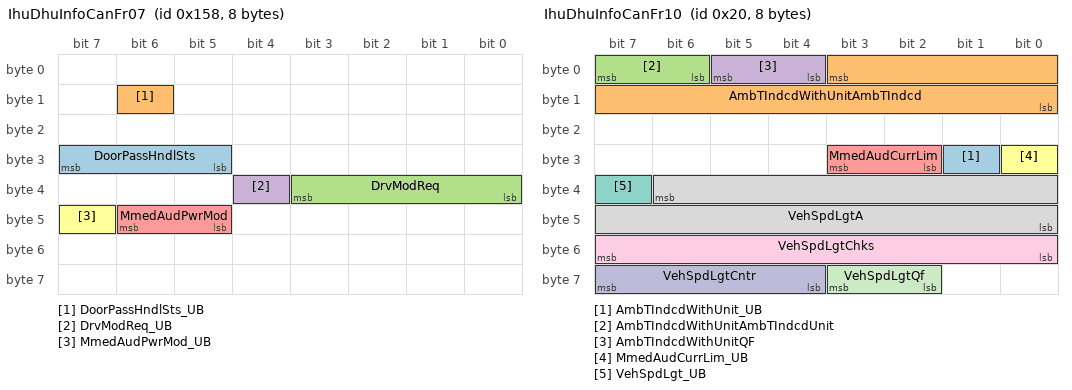
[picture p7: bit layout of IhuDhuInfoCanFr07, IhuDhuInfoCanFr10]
BO_ 344 IhuDhuInfoCanFr07 : 8 IHU
 SG_ DoorPassHndlSts : 31|3@0+ (1,0) [0|7] "" AUD
 SG_ DoorPassHndlSts_UB : 14|1@0+ (1,0) [0|1] "" AUD
 SG_ DrvModReq : 35|4@0+ (1,0) [0|15] "" AUD
 SG_ DrvModReq_UB : 36|1@0+ (1,0) [0|1] "" AUD
 SG_ MmedAudPwrMod : 46|2@0+ (1,0) [0|3] "" AUD
 SG_ MmedAudPwrMod_UB : 47|1@0+ (1,0) [0|1] "" AUD

BO_ 849 IhuDhuInfoCanFr08 : 8 IHU
 SG_ EngSt1WdSts_UB : 63|1@0+ (1,0) [0|1] "" AUD
 SG_ EngSt1WdStsChks : 47|8@0+ (1.0,0.0) [0.0|255.0] "Unitless" AUD
 SG_ EngSt1WdStsCntr : 55|4@0+ (1.0,0.0) [0.0|15.0] "Unitless" AUD
 SG_ EngSt1WdStsEngSt1WdSts : 51|4@0+ (1,0) [0|15] "" AUD
 SG_ LvlOfpoint6 : 60|5@0+ (1.0,0.0) [0.0|31.0] "Unitless" AUD
 SG_ LvlOfpoint6_UB : 61|1@0+ (1,0) [0|1] "" AUD
 SG_ VehModMngtGlbSafe1_UB : 32|1@0+ (1,0) [0|1] "" AUD,PDCM
 SG_ VehModMngtGlbSafe1CarModSts1 : 39|3@0+ (1,0) [0|7] "" AUD,PDCM
 SG_ VehModMngtGlbSafe1CarModSubtypWdCarModSubtyp : 36|3@0+ (1.0,0.0) [0.0|7.0] "Unitless" AUD,PDCM
 SG_ VehModMngtGlbSafe1Chks : 7|8@0+ (1.0,0.0) [0.0|255.0] "Unitless" AUD,PDCM
 SG_ VehModMngtGlbSafe1Cntr : 15|4@0+ (1.0,0.0) [0.0|15.0] "Unitless" AUD,PDCM
 SG_ VehModMngtGlbSafe1EgyLvlElecMai : 11|4@0+ (1.0,0.0) [0.0|15.0] "Unitless" AUD,PDCM
 SG_ VehModMngtGlbSafe1EgyLvlElecSubtyp : 23|4@0+ (1.0,0.0) [0.0|15.0] "Unitless" AUD,PDCM
 SG_ VehModMngtGlbSafe1FltEgyCnsWdSts : 33|1@0+ (1,0) [0|1] "" AUD,PDCM
 SG_ VehModMngtGlbSafe1PwrLvlElecMai : 19|4@0+ (1.0,0.0) [0.0|15.0] "Unitless" AUD,PDCM
 SG_ VehModMngtGlbSafe1PwrLvlElecSubtyp : 31|4@0+ (1.0,0.0) [0.0|15.0] "Unitless" AUD,PDCM
 SG_ VehModMngtGlbSafe1UsgModSts : 27|4@0+ (1,0) [0|15] "" AUD,PDCM

BO_ 1104 IhuDhuInfoCanFr09 : 8 IHU
 SG_ BkpOfDstTrvld : 36|21@0+ (1.0,0.0) [0.0|2000000.0] "km" AUD,ETC
 SG_ BkpOfDstTrvld_UB : 38|1@0+ (1,0) [0|1] "" AUD,ETC
 SG_ CarTiGlb : 7|32@0+ (0.1,0.0) [0.0|429496729.5] "s" AUD
 SG_ CarTiGlb_UB : 39|1@0+ (1,0) [0|1] "" AUD

BO_ 32 IhuDhuInfoCanFr10 : 8 IHU
 SG_ AmbTIndcdWithUnit_UB : 25|1@0+ (1,0) [0|1] "" AUD
 SG_ AmbTIndcdWithUnitAmbTIndcd : 3|12@0+ (0.1,-100.0) [-100.0|309.5] "Unitless" AUD
 SG_ AmbTIndcdWithUnitAmbTIndcdUnit : 7|2@0+ (1,0) [0|3] "" AUD
 SG_ AmbTIndcdWithUnitQF : 5|2@0+ (1,0) [0|3] "" AUD
 SG_ MmedAudCurrLim : 27|2@0+ (1,0) [0|3] "" AUD
 SG_ MmedAudCurrLim_UB : 24|1@0+ (1,0) [0|1] "" AUD
 SG_ VehSpdLgt_UB : 39|1@0+ (1,0) [0|1] "" AUD,PDCM
 SG_ VehSpdLgtA : 38|15@0+ (0.00391,0.0) [0.0|125.0027] "m/s" AUD,PDCM
 SG_ VehSpdLgtChks : 55|8@0+ (1.0,0.0) [0.0|255.0] "Unitless" AUD,PDCM
 SG_ VehSpdLgtCntr : 63|4@0+ (1.0,0.0) [0.0|15.0] "Unitless" AUD,PDCM
 SG_ VehSpdLgtQf : 59|2@0+ (1,0) [0|3] "" AUD,PDCM

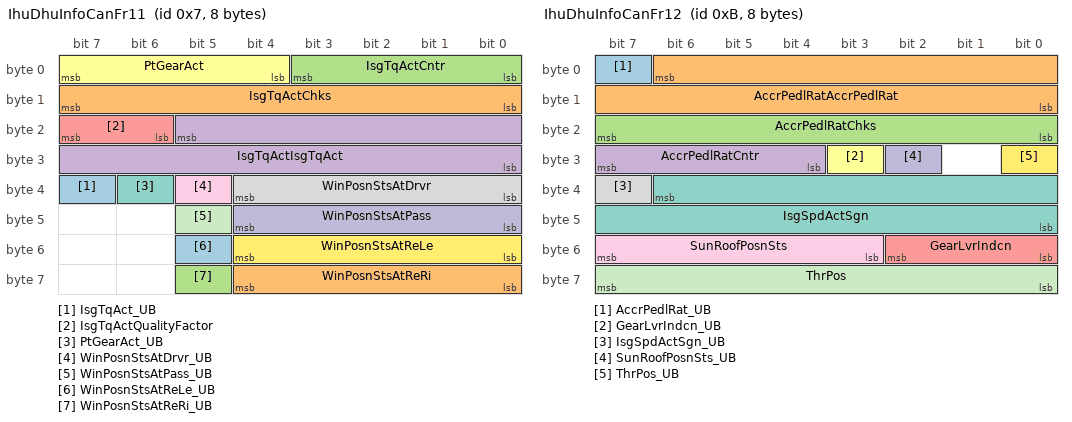
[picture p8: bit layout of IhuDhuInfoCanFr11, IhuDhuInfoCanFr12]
BO_ 7 IhuDhuInfoCanFr11 : 8 IHU
 SG_ IsgTqAct_UB : 39|1@0+ (1,0) [0|1] "" AUD
 SG_ IsgTqActChks : 15|8@0+ (1.0,0.0) [0.0|255.0] "Unitless" AUD
 SG_ IsgTqActCntr : 3|4@0+ (1.0,0.0) [0.0|15.0] "Unitless" AUD
 SG_ IsgTqActIsgTqAct : 21|14@0+ (1.0,-8188.0) [-8188.0|8192.0] "NewtonMeter" AUD
 SG_ IsgTqActQualityFactor : 23|2@0+ (1,0) [0|3] "" AUD
 SG_ PtGearAct : 7|4@0+ (1,0) [0|15] "" AUD
 SG_ PtGearAct_UB : 38|1@0+ (1,0) [0|1] "" AUD
 SG_ WinPosnStsAtDrvr : 36|5@0+ (1,0) [0|31] "" AUD
 SG_ WinPosnStsAtDrvr_UB : 37|1@0+ (1,0) [0|1] "" AUD
 SG_ WinPosnStsAtPass : 44|5@0+ (1,0) [0|31] "" AUD
 SG_ WinPosnStsAtPass_UB : 45|1@0+ (1,0) [0|1] "" AUD
 SG_ WinPosnStsAtReLe : 52|5@0+ (1,0) [0|31] "" AUD
 SG_ WinPosnStsAtReLe_UB : 53|1@0+ (1,0) [0|1] "" AUD
 SG_ WinPosnStsAtReRi : 60|5@0+ (1,0) [0|31] "" AUD
 SG_ WinPosnStsAtReRi_UB : 61|1@0+ (1,0) [0|1] "" AUD

BO_ 11 IhuDhuInfoCanFr12 : 8 IHU
 SG_ AccrPedlRat_UB : 7|1@0+ (1,0) [0|1] "" AUD
 SG_ AccrPedlRatAccrPedlRat : 6|15@0+ (0.00390625,0.0) [0.0|100.0] "%" AUD
 SG_ AccrPedlRatChks : 23|8@0+ (1.0,0.0) [0.0|255.0] "Unitless" AUD
 SG_ AccrPedlRatCntr : 31|4@0+ (1.0,0.0) [0.0|15.0] "Unitless" AUD
 SG_ GearLvrIndcn : 50|3@0+ (1,0) [0|7] "" AUD,PDCM
 SG_ GearLvrIndcn_UB : 27|1@0+ (1,0) [0|1] "" AUD,PDCM
 SG_ IsgSpdActSgn : 38|15@0- (1.0,0.0) [-16384.0|16383.0] "rpm" AUD
 SG_ IsgSpdActSgn_UB : 39|1@0+ (1,0) [0|1] "" AUD
 SG_ SunRoofPosnSts : 55|5@0+ (1,0) [0|31] "" AUD
 SG_ SunRoofPosnSts_UB : 26|1@0+ (1,0) [0|1] "" AUD
 SG_ ThrPos : 63|8@0+ (0.5,0.0) [0.0|100.0] "%" AUD
 SG_ ThrPos_UB : 24|1@0+ (1,0) [0|1] "" AUD

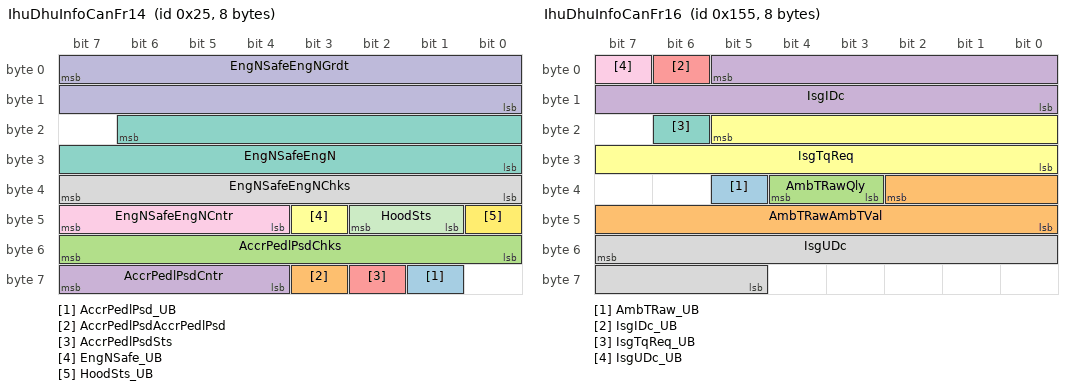
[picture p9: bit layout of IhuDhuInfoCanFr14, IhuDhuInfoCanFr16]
BO_ 37 IhuDhuInfoCanFr14 : 8 IHU
 SG_ AccrPedlPsd_UB : 57|1@0+ (1,0) [0|1] "" AUD,PDCM
 SG_ AccrPedlPsdAccrPedlPsd : 59|1@0+ (1,0) [0|1] "" AUD,PDCM
 SG_ AccrPedlPsdChks : 55|8@0+ (1.0,0.0) [0.0|255.0] "Unitless" AUD,PDCM
 SG_ AccrPedlPsdCntr : 63|4@0+ (1.0,0.0) [0.0|15.0] "Unitless" AUD,PDCM
 SG_ AccrPedlPsdSts : 58|1@0+ (1,0) [0|1] "" AUD,PDCM
 SG_ EngNSafe_UB : 43|1@0+ (1,0) [0|1] "" AUD
 SG_ EngNSafeEngN : 22|15@0+ (0.5,0.0) [0.0|16383.5] "rpm" AUD
 SG_ EngNSafeEngNChks : 39|8@0+ (1.0,0.0) [0.0|255.0] "Unitless" AUD
 SG_ EngNSafeEngNCntr : 47|4@0+ (1.0,0.0) [0.0|15.0] "Unitless" AUD
 SG_ EngNSafeEngNGrdt : 7|16@0- (1.0,0.0) [-30000.0|32767.0] "RpmPerSec" AUD
 SG_ HoodSts : 42|2@0+ (1,0) [0|3] "" AUD
 SG_ HoodSts_UB : 40|1@0+ (1,0) [0|1] "" AUD

BO_ 41 IhuDhuInfoCanFr15 : 8 IHU
 SG_ DoorDrvrSts : 1|2@0+ (1,0) [0|3] "" AUD
 SG_ DoorDrvrSts_UB : 2|1@0+ (1,0) [0|1] "" AUD
 SG_ DoorLeReSts : 4|2@0+ (1,0) [0|3] "" AUD
 SG_ DoorLeReSts_UB : 5|1@0+ (1,0) [0|1] "" AUD
 SG_ DoorPassSts : 7|2@0+ (1,0) [0|3] "" AUD
 SG_ DoorPassSts_UB : 15|1@0+ (1,0) [0|1] "" AUD
 SG_ DoorRiReSts : 14|2@0+ (1,0) [0|3] "" AUD
 SG_ DoorRiReSts_UB : 12|1@0+ (1,0) [0|1] "" AUD
 SG_ OverBoostSts : 8|1@0+ (1,0) [0|1] "" AUD
 SG_ OverBoostSts_UB : 23|1@0+ (1,0) [0|1] "" AUD
 SG_ TrSts : 11|2@0+ (1,0) [0|3] "" AUD
 SG_ TrSts_UB : 9|1@0+ (1,0) [0|1] "" AUD
 SG_ WhlSpdCircumlRe_UB : 56|1@0+ (1,0) [0|1] "" AUD
 SG_ WhlSpdCircumlReChks : 39|8@0+ (1.0,0.0) [0.0|255.0] "Unitless" AUD
 SG_ WhlSpdCircumlReCntr : 47|4@0+ (1.0,0.0) [0.0|15.0] "Unitless" AUD
 SG_ WhlSpdCircumlReLe : 22|15@0+ (0.00391,0.0) [0.0|125.0027] "m/s" AUD
 SG_ WhlSpdCircumlReLeQf : 43|2@0+ (1,0) [0|3] "" AUD
 SG_ WhlSpdCircumlReRi : 55|15@0+ (0.00391,0.0) [0.0|125.0027] "m/s" AUD
 SG_ WhlSpdCircumlReRiQf : 41|2@0+ (1,0) [0|3] "" AUD

BO_ 341 IhuDhuInfoCanFr16 : 8 IHU
 SG_ AmbTRaw_UB : 37|1@0+ (1,0) [0|1] "" AUD,PDCM
 SG_ AmbTRawAmbTVal : 34|11@0+ (0.1,-70.0) [-70.0|134.70000000000002] "degC" AUD,PDCM
 SG_ AmbTRawQly : 36|2@0+ (1,0) [0|3] "" AUD,PDCM
 SG_ IsgIDc : 5|14@0+ (0.1,-818.8) [-818.8|819.2] "A" AUD
 SG_ IsgIDc_UB : 6|1@0+ (1,0) [0|1] "" AUD
 SG_ IsgTqReq : 21|14@0+ (1.0,-8188.0) [-8188.0|8192.0] "NewtonMeter" AUD
 SG_ IsgTqReq_UB : 22|1@0+ (1,0) [0|1] "" AUD
 SG_ IsgUDc : 55|11@0+ (0.25,0.0) [0.0|511.0] "Volt" AUD
 SG_ IsgUDc_UB : 7|1@0+ (1,0) [0|1] "" AUD

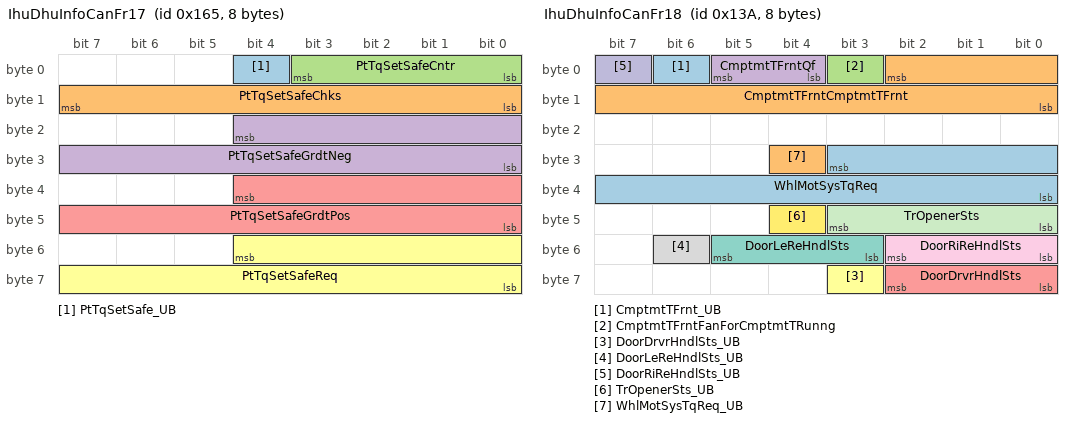
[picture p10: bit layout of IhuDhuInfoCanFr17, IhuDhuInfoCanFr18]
BO_ 357 IhuDhuInfoCanFr17 : 8 IHU
 SG_ PtTqSetSafe_UB : 4|1@0+ (1,0) [0|1] "" AUD
 SG_ PtTqSetSafeChks : 15|8@0+ (1.0,0.0) [0.0|255.0] "Unitless" AUD
 SG_ PtTqSetSafeCntr : 3|4@0+ (1.0,0.0) [0.0|15.0] "Unitless" AUD
 SG_ PtTqSetSafeGrdtNeg : 20|13@0+ (4.0,0.0) [0.0|32764.0] "Nm/s" AUD
 SG_ PtTqSetSafeGrdtPos : 36|13@0+ (4.0,0.0) [0.0|32764.0] "Nm/s" AUD
 SG_ PtTqSetSafeReq : 52|13@0- (4.0,0.0) [-16384.0|16380.0] "NewtonMeter" AUD

BO_ 314 IhuDhuInfoCanFr18 : 8 IHU
 SG_ CmptmtTFrnt_UB : 6|1@0+ (1,0) [0|1] "" AUD
 SG_ CmptmtTFrntCmptmtTFrnt : 2|11@0+ (0.1,-60.0) [-60.0|125.0] "degC" AUD
 SG_ CmptmtTFrntFanForCmptmtTRunng : 3|1@0+ (1,0) [0|1] "" AUD
 SG_ CmptmtTFrntQf : 5|2@0+ (1,0) [0|3] "" AUD
 SG_ DoorDrvrHndlSts : 58|3@0+ (1,0) [0|7] "" AUD
 SG_ DoorDrvrHndlSts_UB : 59|1@0+ (1,0) [0|1] "" AUD
 SG_ DoorLeReHndlSts : 53|3@0+ (1,0) [0|7] "" AUD
 SG_ DoorLeReHndlSts_UB : 54|1@0+ (1,0) [0|1] "" AUD
 SG_ DoorRiReHndlSts : 50|3@0+ (1,0) [0|7] "" AUD
 SG_ DoorRiReHndlSts_UB : 7|1@0+ (1,0) [0|1] "" AUD
 SG_ TrOpenerSts : 43|4@0+ (1,0) [0|15] "" AUD
 SG_ TrOpenerSts_UB : 44|1@0+ (1,0) [0|1] "" AUD
 SG_ WhlMotSysTqReq : 27|12@0+ (4.0,-8188.0) [-8188.0|8192.0] "NewtonMeter" AUD
 SG_ WhlMotSysTqReq_UB : 28|1@0+ (1,0) [0|1] "" AUD

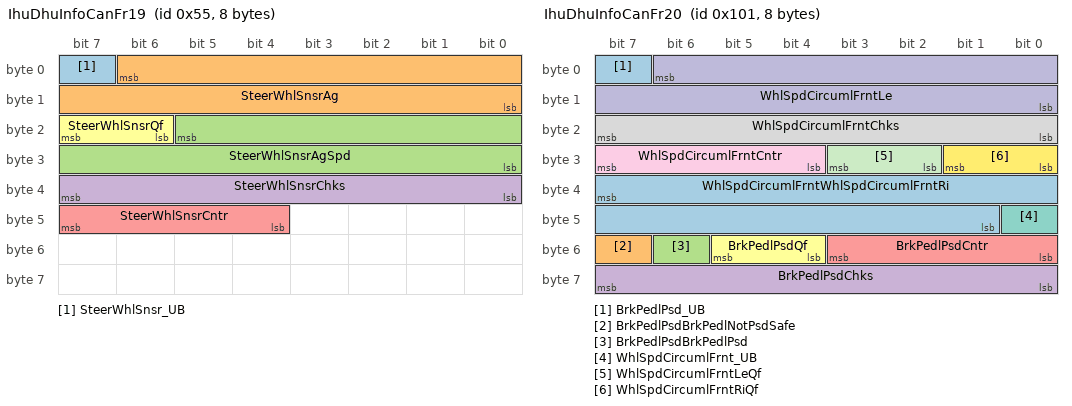
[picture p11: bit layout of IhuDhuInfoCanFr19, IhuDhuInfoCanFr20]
BO_ 85 IhuDhuInfoCanFr19 : 8 IHU
 SG_ SteerWhlSnsr_UB : 7|1@0+ (1,0) [0|1] "" AUD
 SG_ SteerWhlSnsrAg : 6|15@0- (0.0009765625,0.0) [-14.5|14.5] "rad" AUD
 SG_ SteerWhlSnsrAgSpd : 21|14@0- (0.0078125,0.0) [-50.0|50.0] "rad/s" AUD
 SG_ SteerWhlSnsrChks : 39|8@0+ (1.0,0.0) [0.0|255.0] "Unitless" AUD
 SG_ SteerWhlSnsrCntr : 47|4@0+ (1.0,0.0) [0.0|15.0] "Unitless" AUD
 SG_ SteerWhlSnsrQf : 23|2@0+ (1,0) [0|3] "" AUD

BO_ 257 IhuDhuInfoCanFr20 : 8 IHU
 SG_ BrkPedlPsd_UB : 7|1@0+ (1,0) [0|1] "" AUD
 SG_ BrkPedlPsdBrkPedlNotPsdSafe : 55|1@0+ (1,0) [0|1] "" AUD
 SG_ BrkPedlPsdBrkPedlPsd : 54|1@0+ (1,0) [0|1] "" AUD
 SG_ BrkPedlPsdChks : 63|8@0+ (1.0,0.0) [0.0|255.0] "Unitless" AUD
 SG_ BrkPedlPsdCntr : 51|4@0+ (1.0,0.0) [0.0|15.0] "Unitless" AUD
 SG_ BrkPedlPsdQf : 53|2@0+ (1,0) [0|3] "" AUD
 SG_ WhlSpdCircumlFrnt_UB : 40|1@0+ (1,0) [0|1] "" AUD
 SG_ WhlSpdCircumlFrntChks : 23|8@0+ (1.0,0.0) [0.0|255.0] "Unitless" AUD
 SG_ WhlSpdCircumlFrntCntr : 31|4@0+ (1.0,0.0) [0.0|15.0] "Unitless" AUD
 SG_ WhlSpdCircumlFrntLe : 6|15@0+ (0.00391,0.0) [0.0|125.0027] "m/s" AUD
 SG_ WhlSpdCircumlFrntLeQf : 27|2@0+ (1,0) [0|3] "" AUD
 SG_ WhlSpdCircumlFrntRiQf : 25|2@0+ (1,0) [0|3] "" AUD
 SG_ WhlSpdCircumlFrntWhlSpdCircumlFrntRi : 39|15@0+ (0.00391,0.0) [0.0|125.0027] "m/s" AUD

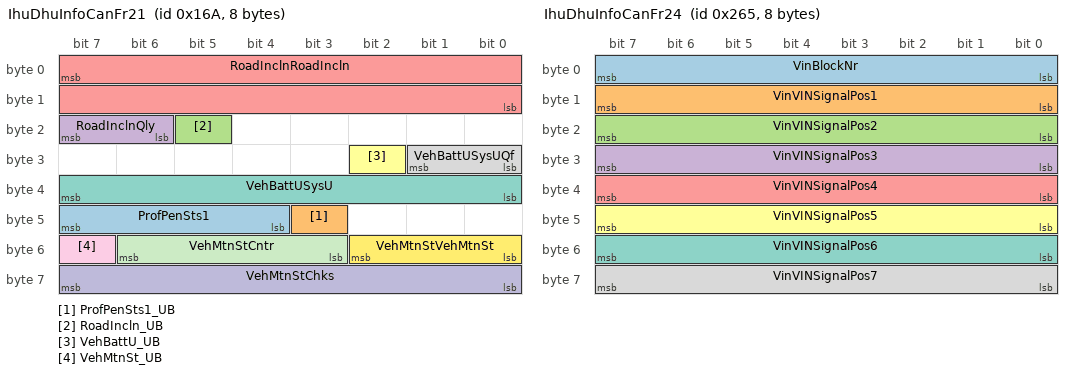
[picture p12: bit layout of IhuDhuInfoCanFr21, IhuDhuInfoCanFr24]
BO_ 362 IhuDhuInfoCanFr21 : 8 IHU
 SG_ ProfPenSts1 : 47|4@0+ (1,0) [0|15] "" AUD
 SG_ ProfPenSts1_UB : 43|1@0+ (1,0) [0|1] "" AUD
 SG_ RoadIncln_UB : 21|1@0+ (1,0) [0|1] "" AUD
 SG_ RoadInclnQly : 23|2@0+ (1,0) [0|3] "" AUD
 SG_ RoadInclnRoadIncln : 7|16@0- (0.000030518,0.0) [-0.9999833060000001|0.9999833060000001] "rad" AUD
 SG_ VehBattU_UB : 26|1@0+ (1,0) [0|1] "" AUD
 SG_ VehBattUSysU : 39|8@0+ (0.1,0.0) [0.0|25.0] "Volt" AUD
 SG_ VehBattUSysUQf : 25|2@0+ (1,0) [0|3] "" AUD
 SG_ VehMtnSt_UB : 55|1@0+ (1,0) [0|1] "" AUD,PDCM
 SG_ VehMtnStChks : 63|8@0+ (1.0,0.0) [0.0|255.0] "Unitless" AUD,PDCM
 SG_ VehMtnStCntr : 54|4@0+ (1.0,0.0) [0.0|15.0] "Unitless" AUD,PDCM
 SG_ VehMtnStVehMtnSt : 50|3@0+ (1,0) [0|7] "" AUD,PDCM

BO_ 848 IhuDhuInfoCanFr23 : 8 IHU
 SG_ AcoustEfectPrvtCinePsn : 59|2@0+ (1,0) [0|3] "" AUD
 SG_ AcoustEfectPrvtCinePsn_UB : 57|1@0+ (1,0) [0|1] "" AUD
 SG_ Audio2Mute : 63|1@0+ (1,0) [0|1] "" AUD
 SG_ Audio2Mute_UB : 62|1@0+ (1,0) [0|1] "" AUD
 SG_ CrashStsSafe_UB : 45|1@0+ (1,0) [0|1] "" Vector__XXX
 SG_ CrashStsSafeChks : 55|8@0+ (1.0,0.0) [0.0|255.0] "Unitless" Vector__XXX
 SG_ CrashStsSafeCntr : 43|4@0+ (1.0,0.0) [0.0|15.0] "Unitless" Vector__XXX
 SG_ CrashStsSafeSts : 44|1@0+ (1,0) [0|1] "" Vector__XXX
 SG_ RecOfImpct_UB : 33|1@0+ (1,0) [0|1] "" Vector__XXX
 SG_ RecOfImpctCrashFrnt : 16|1@0+ (1,0) [0|1] "" Vector__XXX
 SG_ RecOfImpctCrashOffroadA : 34|1@0+ (1,0) [0|1] "" Vector__XXX
 SG_ RecOfImpctCrashOffroadD : 35|1@0+ (1,0) [0|1] "" Vector__XXX
 SG_ RecOfImpctCrashOffroadRT : 36|1@0+ (1,0) [0|1] "" Vector__XXX
 SG_ RecOfImpctCrashOffroadRTsevere : 37|1@0+ (1,0) [0|1] "" Vector__XXX
 SG_ RecOfImpctCrashPed : 38|1@0+ (1,0) [0|1] "" Vector__XXX
 SG_ RecOfImpctCrashRe : 39|1@0+ (1,0) [0|1] "" Vector__XXX
 SG_ RecOfImpctCrashRollovr : 24|1@0+ (1,0) [0|1] "" Vector__XXX
 SG_ RecOfImpctCrashSideLe : 25|1@0+ (1,0) [0|1] "" Vector__XXX
 SG_ RecOfImpctCrashSideRi : 26|1@0+ (1,0) [0|1] "" Vector__XXX
 SG_ RecOfImpctCrashState : 28|2@0+ (1,0) [0|3] "" Vector__XXX
 SG_ RecOfImpctImpctDvx : 7|8@0+ (1.0,0.0) [0.0|255.0] "Km/h" Vector__XXX
 SG_ RecOfImpctImpctDvy : 15|8@0+ (1.0,0.0) [0.0|255.0] "Km/h" Vector__XXX
 SG_ RecOfImpctImpctRollAg : 23|7@0+ (15.0,0.0) [0.0|1905.0] "Deg" Vector__XXX
 SG_ RecOfImpctVehOri : 31|3@0+ (1,0) [0|7] "" Vector__XXX

BO_ 613 IhuDhuInfoCanFr24 : 8 IHU
 SG_ VinBlockNr : 7|8@0+ (1.0,0.0) [0.0|255.0] "Unitless" Vector__XXX
 SG_ VinVINSignalPos1 : 15|8@0+ (1.0,0.0) [0.0|255.0] "Unitless" Vector__XXX
 SG_ VinVINSignalPos2 : 23|8@0+ (1.0,0.0) [0.0|255.0] "Unitless" Vector__XXX
 SG_ VinVINSignalPos3 : 31|8@0+ (1.0,0.0) [0.0|255.0] "Unitless" Vector__XXX
 SG_ VinVINSignalPos4 : 39|8@0+ (1.0,0.0) [0.0|255.0] "Unitless" Vector__XXX
 SG_ VinVINSignalPos5 : 47|8@0+ (1.0,0.0) [0.0|255.0] "Unitless" Vector__XXX
 SG_ VinVINSignalPos6 : 55|8@0+ (1.0,0.0) [0.0|255.0] "Unitless" Vector__XXX
 SG_ VinVINSignalPos7 : 63|8@0+ (1.0,0.0) [0.0|255.0] "Unitless" Vector__XXX

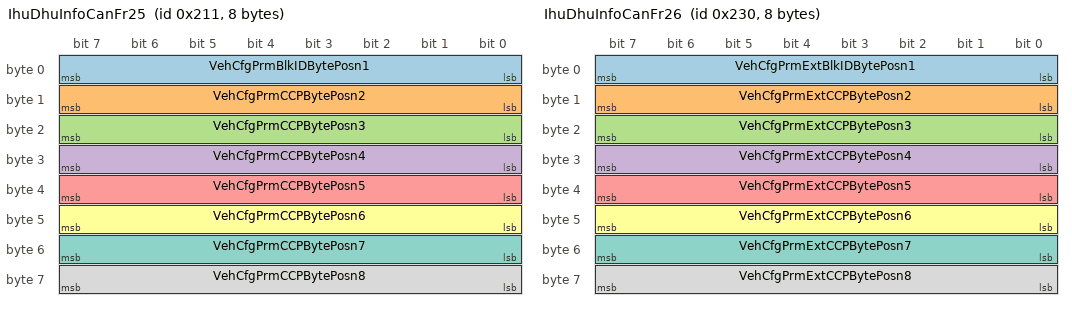
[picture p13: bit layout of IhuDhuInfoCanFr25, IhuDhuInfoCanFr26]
BO_ 529 IhuDhuInfoCanFr25 : 8 IHU
 SG_ VehCfgPrmBlkIDBytePosn1 : 7|8@0+ (1.0,0.0) [0.0|255.0] "Unitless" PDCM
 SG_ VehCfgPrmCCPBytePosn2 : 15|8@0+ (1.0,0.0) [0.0|255.0] "Unitless" PDCM
 SG_ VehCfgPrmCCPBytePosn3 : 23|8@0+ (1.0,0.0) [0.0|255.0] "Unitless" PDCM
 SG_ VehCfgPrmCCPBytePosn4 : 31|8@0+ (1.0,0.0) [0.0|255.0] "Unitless" PDCM
 SG_ VehCfgPrmCCPBytePosn5 : 39|8@0+ (1.0,0.0) [0.0|255.0] "Unitless" PDCM
 SG_ VehCfgPrmCCPBytePosn6 : 47|8@0+ (1.0,0.0) [0.0|255.0] "Unitless" PDCM
 SG_ VehCfgPrmCCPBytePosn7 : 55|8@0+ (1.0,0.0) [0.0|255.0] "Unitless" PDCM
 SG_ VehCfgPrmCCPBytePosn8 : 63|8@0+ (1.0,0.0) [0.0|255.0] "Unitless" PDCM

BO_ 560 IhuDhuInfoCanFr26 : 8 IHU
 SG_ VehCfgPrmExtBlkIDBytePosn1 : 7|8@0+ (1.0,0.0) [0.0|255.0] "Unitless" PDCM
 SG_ VehCfgPrmExtCCPBytePosn2 : 15|8@0+ (1.0,0.0) [0.0|255.0] "Unitless" PDCM
 SG_ VehCfgPrmExtCCPBytePosn3 : 23|8@0+ (1.0,0.0) [0.0|255.0] "Unitless" PDCM
 SG_ VehCfgPrmExtCCPBytePosn4 : 31|8@0+ (1.0,0.0) [0.0|255.0] "Unitless" PDCM
 SG_ VehCfgPrmExtCCPBytePosn5 : 39|8@0+ (1.0,0.0) [0.0|255.0] "Unitless" PDCM
 SG_ VehCfgPrmExtCCPBytePosn6 : 47|8@0+ (1.0,0.0) [0.0|255.0] "Unitless" PDCM
 SG_ VehCfgPrmExtCCPBytePosn7 : 55|8@0+ (1.0,0.0) [0.0|255.0] "Unitless" PDCM
 SG_ VehCfgPrmExtCCPBytePosn8 : 63|8@0+ (1.0,0.0) [0.0|255.0] "Unitless" PDCM

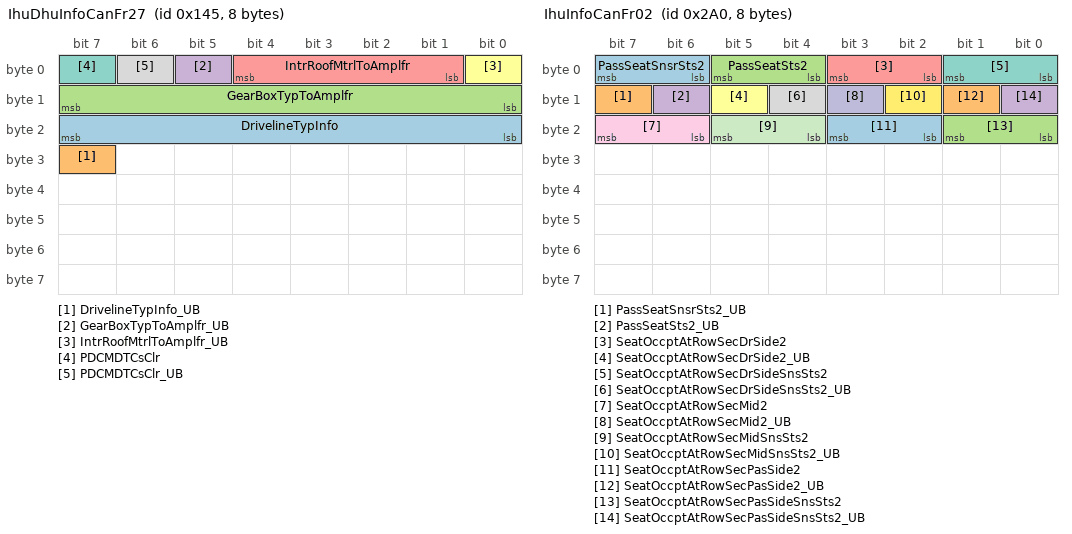
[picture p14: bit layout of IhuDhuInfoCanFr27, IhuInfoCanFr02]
BO_ 325 IhuDhuInfoCanFr27 : 8 IHU
 SG_ DrivelineTypInfo : 23|8@0+ (1.0,0.0) [0.0|255.0] "Unitless" AUD
 SG_ DrivelineTypInfo_UB : 31|1@0+ (1,0) [0|1] "" AUD
 SG_ GearBoxTypToAmplfr : 15|8@0+ (1.0,0.0) [0.0|255.0] "Unitless" AUD
 SG_ GearBoxTypToAmplfr_UB : 5|1@0+ (1,0) [0|1] "" AUD
 SG_ IntrRoofMtrlToAmplfr : 4|4@0+ (1.0,0.0) [0.0|15.0] "Unitless" AUD
 SG_ IntrRoofMtrlToAmplfr_UB : 0|1@0+ (1,0) [0|1] "" AUD
 SG_ PDCMDTCsClr : 7|1@0+ (1,0) [0|1] "" PDCM
 SG_ PDCMDTCsClr_UB : 6|1@0+ (1,0) [0|1] "" PDCM

BO_ 316 IhuInfoCanFr01 : 8 IHU
 SG_ AudSpkrNrToAmplfr : 15|8@0+ (1.0,0.0) [0.0|255.0] "Unitless" AUD
 SG_ AudSpkrNrToAmplfr_UB : 4|1@0+ (1,0) [0|1] "" AUD
 SG_ VehTypToAmplfrExt : 23|8@0+ (1.0,0.0) [0.0|255.0] "Unitless" AUD
 SG_ VehTypToAmplfrExt_UB : 31|1@0+ (1,0) [0|1] "" AUD

BO_ 672 IhuInfoCanFr02 : 8 IHU
 SG_ PassSeatSnsrSts2 : 7|2@0+ (1,0) [0|3] "" Vector__XXX
 SG_ PassSeatSnsrSts2_UB : 15|1@0+ (1,0) [0|1] "" Vector__XXX
 SG_ PassSeatSts2 : 5|2@0+ (1,0) [0|3] "" Vector__XXX
 SG_ PassSeatSts2_UB : 14|1@0+ (1,0) [0|1] "" Vector__XXX
 SG_ SeatOccptAtRowSecDrSide2 : 3|2@0+ (1,0) [0|3] "" Vector__XXX
 SG_ SeatOccptAtRowSecDrSide2_UB : 13|1@0+ (1,0) [0|1] "" Vector__XXX
 SG_ SeatOccptAtRowSecDrSideSnsSts2 : 1|2@0+ (1,0) [0|3] "" Vector__XXX
 SG_ SeatOccptAtRowSecDrSideSnsSts2_UB : 12|1@0+ (1,0) [0|1] "" Vector__XXX
 SG_ SeatOccptAtRowSecMid2 : 23|2@0+ (1,0) [0|3] "" Vector__XXX
 SG_ SeatOccptAtRowSecMid2_UB : 11|1@0+ (1,0) [0|1] "" Vector__XXX
 SG_ SeatOccptAtRowSecMidSnsSts2 : 21|2@0+ (1,0) [0|3] "" Vector__XXX
 SG_ SeatOccptAtRowSecMidSnsSts2_UB : 10|1@0+ (1,0) [0|1] "" Vector__XXX
 SG_ SeatOccptAtRowSecPasSide2 : 19|2@0+ (1,0) [0|3] "" Vector__XXX
 SG_ SeatOccptAtRowSecPasSide2_UB : 9|1@0+ (1,0) [0|1] "" Vector__XXX
 SG_ SeatOccptAtRowSecPasSideSnsSts2 : 17|2@0+ (1,0) [0|3] "" Vector__XXX
 SG_ SeatOccptAtRowSecPasSideSnsSts2_UB : 8|1@0+ (1,0) [0|1] "" Vector__XXX

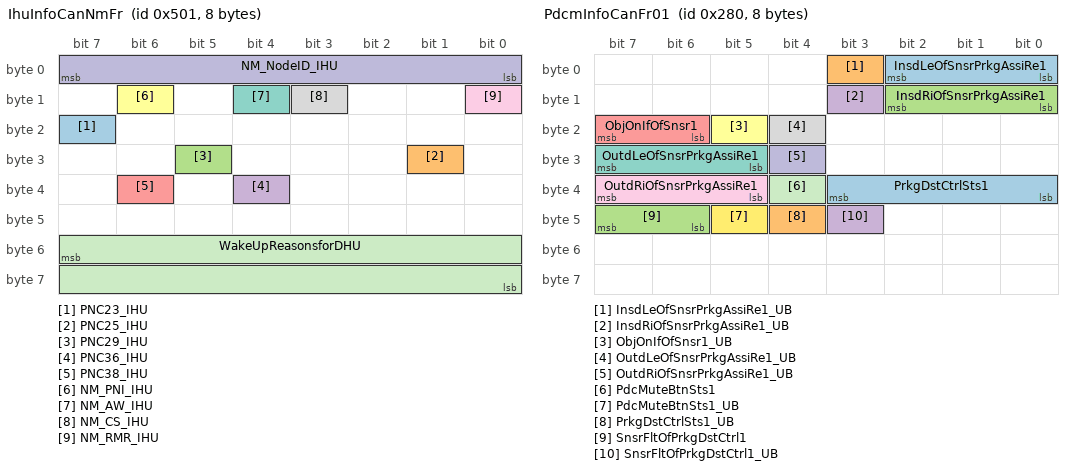
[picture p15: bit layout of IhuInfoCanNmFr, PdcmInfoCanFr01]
BO_ 1281 IhuInfoCanNmFr : 8 IHU
 SG_ PNC23_IHU : 23|1@0+ (1,0) [0|0] "" Vector__XXX
 SG_ PNC25_IHU : 25|1@0+ (1,0) [0|0] "" Vector__XXX
 SG_ PNC29_IHU : 29|1@0+ (1,0) [0|0] "" Vector__XXX
 SG_ PNC36_IHU : 36|1@0+ (1,0) [0|0] "" Vector__XXX
 SG_ PNC38_IHU : 38|1@0+ (1,0) [0|0] "" Vector__XXX
 SG_ NM_PNI_IHU : 14|1@0+ (1,0) [0|0] "" Vector__XXX
 SG_ NM_AW_IHU : 12|1@0+ (1,0) [0|0] "" Vector__XXX
 SG_ NM_CS_IHU : 11|1@0+ (1,0) [0|0] "" Vector__XXX
 SG_ NM_RMR_IHU : 8|1@0+ (1,0) [0|0] "" Vector__XXX
 SG_ NM_NodeID_IHU : 7|8@0+ (1,0) [0|0] "" Vector__XXX

 SG_ WakeUpReasonsforDHU : 55|16@0+ (1,0) [0|65535] "" Vector__XXX

BO_ 1409 IhuToEtcXCPFr01 : 8 IHU

BO_ 640 PdcmInfoCanFr01 : 8 PDCM
 SG_ InsdLeOfSnsrPrkgAssiRe1 : 2|3@0+ (1,0) [0|7] "" IHU
 SG_ InsdLeOfSnsrPrkgAssiRe1_UB : 3|1@0+ (1,0) [0|1] "" IHU
 SG_ InsdRiOfSnsrPrkgAssiRe1 : 10|3@0+ (1,0) [0|7] "" IHU
 SG_ InsdRiOfSnsrPrkgAssiRe1_UB : 11|1@0+ (1,0) [0|1] "" IHU
 SG_ ObjOnIfOfSnsr1 : 23|2@0+ (1,0) [0|3] "" IHU
 SG_ ObjOnIfOfSnsr1_UB : 21|1@0+ (1,0) [0|1] "" IHU
 SG_ OutdLeOfSnsrPrkgAssiRe1 : 31|3@0+ (1,0) [0|7] "" IHU
 SG_ OutdLeOfSnsrPrkgAssiRe1_UB : 20|1@0+ (1,0) [0|1] "" IHU
 SG_ OutdRiOfSnsrPrkgAssiRe1 : 39|3@0+ (1,0) [0|7] "" IHU
 SG_ OutdRiOfSnsrPrkgAssiRe1_UB : 28|1@0+ (1,0) [0|1] "" IHU
 SG_ PdcMuteBtnSts1 : 36|1@0+ (1,0) [0|1] "" IHU
 SG_ PdcMuteBtnSts1_UB : 45|1@0+ (1,0) [0|1] "" IHU
 SG_ PrkgDstCtrlSts1 : 35|4@0+ (1,0) [0|15] "" IHU
 SG_ PrkgDstCtrlSts1_UB : 44|1@0+ (1,0) [0|1] "" IHU
 SG_ SnsrFltOfPrkgDstCtrl1 : 47|2@0+ (1,0) [0|3] "" IHU
 SG_ SnsrFltOfPrkgDstCtrl1_UB : 43|1@0+ (1,0) [0|1] "" IHU

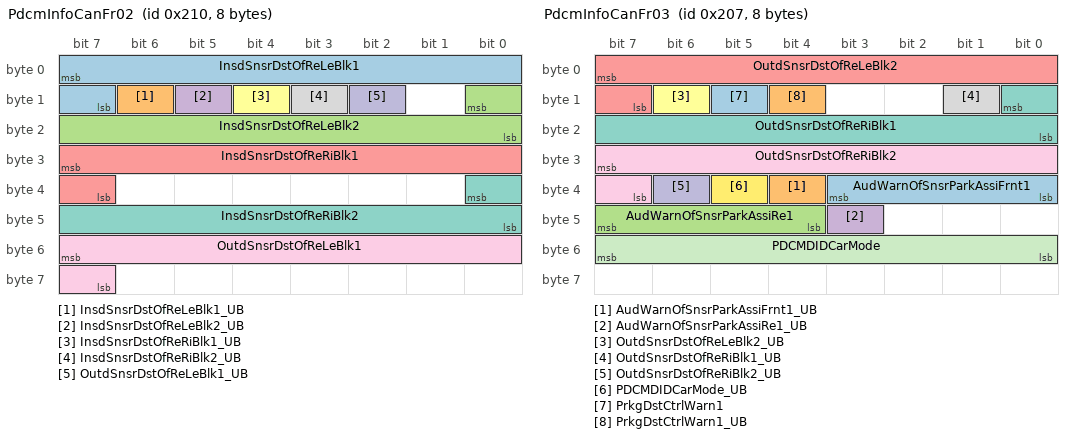
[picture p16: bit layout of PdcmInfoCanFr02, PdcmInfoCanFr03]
BO_ 528 PdcmInfoCanFr02 : 8 PDCM
 SG_ InsdSnsrDstOfReLeBlk1 : 7|9@0+ (1.0,0.0) [0.0|511.0] "cm" IHU
 SG_ InsdSnsrDstOfReLeBlk1_UB : 14|1@0+ (1,0) [0|1] "" IHU
 SG_ InsdSnsrDstOfReLeBlk2 : 8|9@0+ (1.0,0.0) [0.0|511.0] "cm" IHU
 SG_ InsdSnsrDstOfReLeBlk2_UB : 13|1@0+ (1,0) [0|1] "" IHU
 SG_ InsdSnsrDstOfReRiBlk1 : 31|9@0+ (1.0,0.0) [0.0|511.0] "cm" IHU
 SG_ InsdSnsrDstOfReRiBlk1_UB : 12|1@0+ (1,0) [0|1] "" IHU
 SG_ InsdSnsrDstOfReRiBlk2 : 32|9@0+ (1.0,0.0) [0.0|511.0] "cm" IHU
 SG_ InsdSnsrDstOfReRiBlk2_UB : 11|1@0+ (1,0) [0|1] "" IHU
 SG_ OutdSnsrDstOfReLeBlk1 : 55|9@0+ (1.0,0.0) [0.0|511.0] "cm" IHU
 SG_ OutdSnsrDstOfReLeBlk1_UB : 10|1@0+ (1,0) [0|1] "" IHU

BO_ 519 PdcmInfoCanFr03 : 8 PDCM
 SG_ AudWarnOfSnsrParkAssiFrnt1 : 35|4@0+ (1,0) [0|15] "" IHU
 SG_ AudWarnOfSnsrParkAssiFrnt1_UB : 36|1@0+ (1,0) [0|1] "" IHU
 SG_ AudWarnOfSnsrParkAssiRe1 : 47|4@0+ (1,0) [0|15] "" IHU
 SG_ AudWarnOfSnsrParkAssiRe1_UB : 43|1@0+ (1,0) [0|1] "" IHU
 SG_ OutdSnsrDstOfReLeBlk2 : 7|9@0+ (1.0,0.0) [0.0|511.0] "cm" IHU
 SG_ OutdSnsrDstOfReLeBlk2_UB : 14|1@0+ (1,0) [0|1] "" IHU
 SG_ OutdSnsrDstOfReRiBlk1 : 8|9@0+ (1.0,0.0) [0.0|511.0] "cm" IHU
 SG_ OutdSnsrDstOfReRiBlk1_UB : 9|1@0+ (1,0) [0|1] "" IHU
 SG_ OutdSnsrDstOfReRiBlk2 : 31|9@0+ (1.0,0.0) [0.0|511.0] "cm" IHU
 SG_ OutdSnsrDstOfReRiBlk2_UB : 38|1@0+ (1,0) [0|1] "" IHU
 SG_ PDCMDIDCarMode : 55|8@0+ (1.0,0.0) [0.0|255.0] "Unitless" IHU
 SG_ PDCMDIDCarMode_UB : 37|1@0+ (1,0) [0|1] "" IHU
 SG_ PrkgDstCtrlWarn1 : 13|1@0+ (1,0) [0|1] "" IHU
 SG_ PrkgDstCtrlWarn1_UB : 12|1@0+ (1,0) [0|1] "" IHU

BO_ 592 PdcmInfoCanFr04 : 8 PDCM
 SG_ PDCMDiag1 : 7|32@0+ (1.0,0.0) [0.0|4294967295.0] "Unitless" IHU

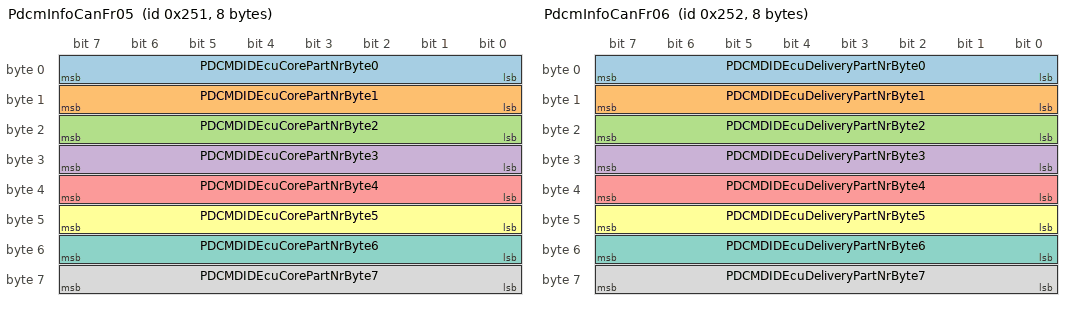
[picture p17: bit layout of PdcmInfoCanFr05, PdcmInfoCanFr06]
BO_ 593 PdcmInfoCanFr05 : 8 PDCM
 SG_ PDCMDIDEcuCorePartNrByte0 : 7|8@0+ (1.0,0.0) [0.0|255.0] "Unitless" IHU
 SG_ PDCMDIDEcuCorePartNrByte1 : 15|8@0+ (1.0,0.0) [0.0|255.0] "Unitless" IHU
 SG_ PDCMDIDEcuCorePartNrByte2 : 23|8@0+ (1.0,0.0) [0.0|255.0] "Unitless" IHU
 SG_ PDCMDIDEcuCorePartNrByte3 : 31|8@0+ (1.0,0.0) [0.0|255.0] "Unitless" IHU
 SG_ PDCMDIDEcuCorePartNrByte4 : 39|8@0+ (1.0,0.0) [0.0|255.0] "Unitless" IHU
 SG_ PDCMDIDEcuCorePartNrByte5 : 47|8@0+ (1.0,0.0) [0.0|255.0] "Unitless" IHU
 SG_ PDCMDIDEcuCorePartNrByte6 : 55|8@0+ (1.0,0.0) [0.0|255.0] "Unitless" IHU
 SG_ PDCMDIDEcuCorePartNrByte7 : 63|8@0+ (1.0,0.0) [0.0|255.0] "Unitless" IHU

BO_ 594 PdcmInfoCanFr06 : 8 PDCM
 SG_ PDCMDIDEcuDeliveryPartNrByte0 : 7|8@0+ (1.0,0.0) [0.0|255.0] "Unitless" IHU
 SG_ PDCMDIDEcuDeliveryPartNrByte1 : 15|8@0+ (1.0,0.0) [0.0|255.0] "Unitless" IHU
 SG_ PDCMDIDEcuDeliveryPartNrByte2 : 23|8@0+ (1.0,0.0) [0.0|255.0] "Unitless" IHU
 SG_ PDCMDIDEcuDeliveryPartNrByte3 : 31|8@0+ (1.0,0.0) [0.0|255.0] "Unitless" IHU
 SG_ PDCMDIDEcuDeliveryPartNrByte4 : 39|8@0+ (1.0,0.0) [0.0|255.0] "Unitless" IHU
 SG_ PDCMDIDEcuDeliveryPartNrByte5 : 47|8@0+ (1.0,0.0) [0.0|255.0] "Unitless" IHU
 SG_ PDCMDIDEcuDeliveryPartNrByte6 : 55|8@0+ (1.0,0.0) [0.0|255.0] "Unitless" IHU
 SG_ PDCMDIDEcuDeliveryPartNrByte7 : 63|8@0+ (1.0,0.0) [0.0|255.0] "Unitless" IHU

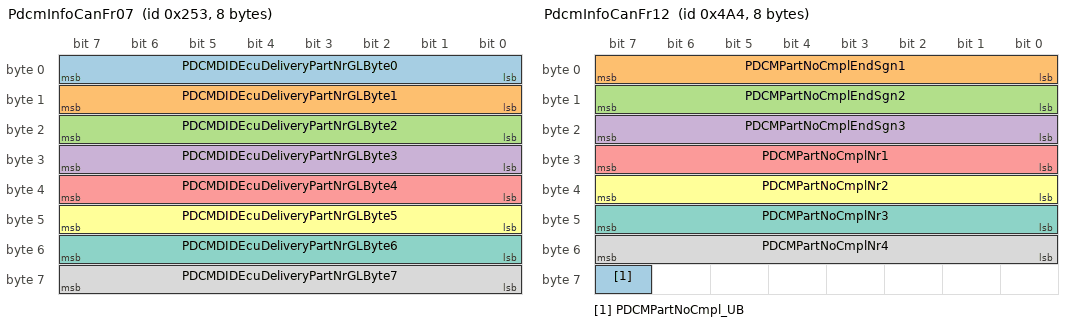
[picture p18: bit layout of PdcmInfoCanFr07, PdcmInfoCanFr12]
BO_ 595 PdcmInfoCanFr07 : 8 PDCM
 SG_ PDCMDIDEcuDeliveryPartNrGLByte0 : 7|8@0+ (1.0,0.0) [0.0|255.0] "Unitless" IHU
 SG_ PDCMDIDEcuDeliveryPartNrGLByte1 : 15|8@0+ (1.0,0.0) [0.0|255.0] "Unitless" IHU
 SG_ PDCMDIDEcuDeliveryPartNrGLByte2 : 23|8@0+ (1.0,0.0) [0.0|255.0] "Unitless" IHU
 SG_ PDCMDIDEcuDeliveryPartNrGLByte3 : 31|8@0+ (1.0,0.0) [0.0|255.0] "Unitless" IHU
 SG_ PDCMDIDEcuDeliveryPartNrGLByte4 : 39|8@0+ (1.0,0.0) [0.0|255.0] "Unitless" IHU
 SG_ PDCMDIDEcuDeliveryPartNrGLByte5 : 47|8@0+ (1.0,0.0) [0.0|255.0] "Unitless" IHU
 SG_ PDCMDIDEcuDeliveryPartNrGLByte6 : 55|8@0+ (1.0,0.0) [0.0|255.0] "Unitless" IHU
 SG_ PDCMDIDEcuDeliveryPartNrGLByte7 : 63|8@0+ (1.0,0.0) [0.0|255.0] "Unitless" IHU

BO_ 596 PdcmInfoCanFr08 : 8 PDCM
 SG_ PDCMDIDEcuCorePartNrGLByte0 : 7|8@0+ (1.0,0.0) [0.0|255.0] "Unitless" IHU
 SG_ PDCMDIDEcuCorePartNrGLByte1 : 15|8@0+ (1.0,0.0) [0.0|255.0] "Unitless" IHU
 SG_ PDCMDIDEcuCorePartNrGLByte2 : 23|8@0+ (1.0,0.0) [0.0|255.0] "Unitless" IHU
 SG_ PDCMDIDEcuCorePartNrGLByte3 : 31|8@0+ (1.0,0.0) [0.0|255.0] "Unitless" IHU
 SG_ PDCMDIDEcuCorePartNrGLByte4 : 39|8@0+ (1.0,0.0) [0.0|255.0] "Unitless" IHU
 SG_ PDCMDIDEcuCorePartNrGLByte5 : 47|8@0+ (1.0,0.0) [0.0|255.0] "Unitless" IHU
 SG_ PDCMDIDEcuCorePartNrGLByte6 : 55|8@0+ (1.0,0.0) [0.0|255.0] "Unitless" IHU
 SG_ PDCMDIDEcuCorePartNrGLByte7 : 63|8@0+ (1.0,0.0) [0.0|255.0] "Unitless" IHU

BO_ 597 PdcmInfoCanFr09 : 8 PDCM
 SG_ PDCMDIDEcuSoftwarePartNrByte0 : 7|8@0+ (1.0,0.0) [0.0|255.0] "Unitless" IHU
 SG_ PDCMDIDEcuSoftwarePartNrByte1 : 15|8@0+ (1.0,0.0) [0.0|255.0] "Unitless" IHU
 SG_ PDCMDIDEcuSoftwarePartNrByte2 : 23|8@0+ (1.0,0.0) [0.0|255.0] "Unitless" IHU
 SG_ PDCMDIDEcuSoftwarePartNrByte3 : 31|8@0+ (1.0,0.0) [0.0|255.0] "Unitless" IHU
 SG_ PDCMDIDEcuSoftwarePartNrByte4 : 39|8@0+ (1.0,0.0) [0.0|255.0] "Unitless" IHU
 SG_ PDCMDIDEcuSoftwarePartNrByte5 : 47|8@0+ (1.0,0.0) [0.0|255.0] "Unitless" IHU
 SG_ PDCMDIDEcuSoftwarePartNrByte6 : 55|8@0+ (1.0,0.0) [0.0|255.0] "Unitless" IHU
 SG_ PDCMDIDEcuSoftwarePartNrByte7 : 63|8@0+ (1.0,0.0) [0.0|255.0] "Unitless" IHU

BO_ 598 PdcmInfoCanFr10 : 8 PDCM
 SG_ PDCMDIDEcuSoftwarePartNrGL2Byte0 : 7|8@0+ (1.0,0.0) [0.0|255.0] "Unitless" IHU
 SG_ PDCMDIDEcuSoftwarePartNrGL2Byte1 : 15|8@0+ (1.0,0.0) [0.0|255.0] "Unitless" IHU
 SG_ PDCMDIDEcuSoftwarePartNrGL2Byte2 : 23|8@0+ (1.0,0.0) [0.0|255.0] "Unitless" IHU
 SG_ PDCMDIDEcuSoftwarePartNrGL2Byte3 : 31|8@0+ (1.0,0.0) [0.0|255.0] "Unitless" IHU
 SG_ PDCMDIDEcuSoftwarePartNrGL2Byte4 : 39|8@0+ (1.0,0.0) [0.0|255.0] "Unitless" IHU
 SG_ PDCMDIDEcuSoftwarePartNrGL2Byte5 : 47|8@0+ (1.0,0.0) [0.0|255.0] "Unitless" IHU
 SG_ PDCMDIDEcuSoftwarePartNrGL2Byte6 : 55|8@0+ (1.0,0.0) [0.0|255.0] "Unitless" IHU
 SG_ PDCMDIDEcuSoftwarePartNrGL2Byte7 : 63|8@0+ (1.0,0.0) [0.0|255.0] "Unitless" IHU

BO_ 1187 PdcmInfoCanFr11 : 8 PDCM
 SG_ PDCMPartNo10CmplEndSgn1 : 7|8@0+ (1.0,0.0) [0.0|255.0] "Unitless" IHU
 SG_ PDCMPartNo10CmplEndSgn2 : 15|8@0+ (1.0,0.0) [0.0|255.0] "Unitless" IHU
 SG_ PDCMPartNo10CmplEndSgn3 : 23|8@0+ (1.0,0.0) [0.0|255.0] "Unitless" IHU
 SG_ PDCMPartNo10CmplNr1 : 31|8@0+ (1.0,0.0) [0.0|255.0] "Unitless" IHU
 SG_ PDCMPartNo10CmplNr2 : 39|8@0+ (1.0,0.0) [0.0|255.0] "Unitless" IHU
 SG_ PDCMPartNo10CmplNr3 : 47|8@0+ (1.0,0.0) [0.0|255.0] "Unitless" IHU
 SG_ PDCMPartNo10CmplNr4 : 55|8@0+ (1.0,0.0) [0.0|255.0] "Unitless" IHU
 SG_ PDCMPartNo10CmplNr5 : 63|8@0+ (1.0,0.0) [0.0|255.0] "Unitless" IHU

BO_ 1188 PdcmInfoCanFr12 : 8 PDCM
 SG_ PDCMPartNoCmpl_UB : 63|1@0+ (1,0) [0|1] "" IHU
 SG_ PDCMPartNoCmplEndSgn1 : 7|8@0+ (1.0,0.0) [0.0|255.0] "Unitless" IHU
 SG_ PDCMPartNoCmplEndSgn2 : 15|8@0+ (1.0,0.0) [0.0|255.0] "Unitless" IHU
 SG_ PDCMPartNoCmplEndSgn3 : 23|8@0+ (1.0,0.0) [0.0|255.0] "Unitless" IHU
 SG_ PDCMPartNoCmplNr1 : 31|8@0+ (1.0,0.0) [0.0|255.0] "Unitless" IHU
 SG_ PDCMPartNoCmplNr2 : 39|8@0+ (1.0,0.0) [0.0|255.0] "Unitless" IHU
 SG_ PDCMPartNoCmplNr3 : 47|8@0+ (1.0,0.0) [0.0|255.0] "Unitless" IHU
 SG_ PDCMPartNoCmplNr4 : 55|8@0+ (1.0,0.0) [0.0|255.0] "Unitless" IHU

BO_ 1189 PdcmInfoCanFr15 : 8 PDCM
 SG_ PDCMSerNo_UB : 39|1@0+ (1,0) [0|1] "" IHU
 SG_ PDCMSerNoNr1 : 7|8@0+ (1.0,0.0) [0.0|255.0] "Unitless" IHU
 SG_ PDCMSerNoNr2 : 15|8@0+ (1.0,0.0) [0.0|255.0] "Unitless" IHU
 SG_ PDCMSerNoNr3 : 23|8@0+ (1.0,0.0) [0.0|255.0] "Unitless" IHU
 SG_ PDCMSerNoNr4 : 31|8@0+ (1.0,0.0) [0.0|255.0] "Unitless" IHU

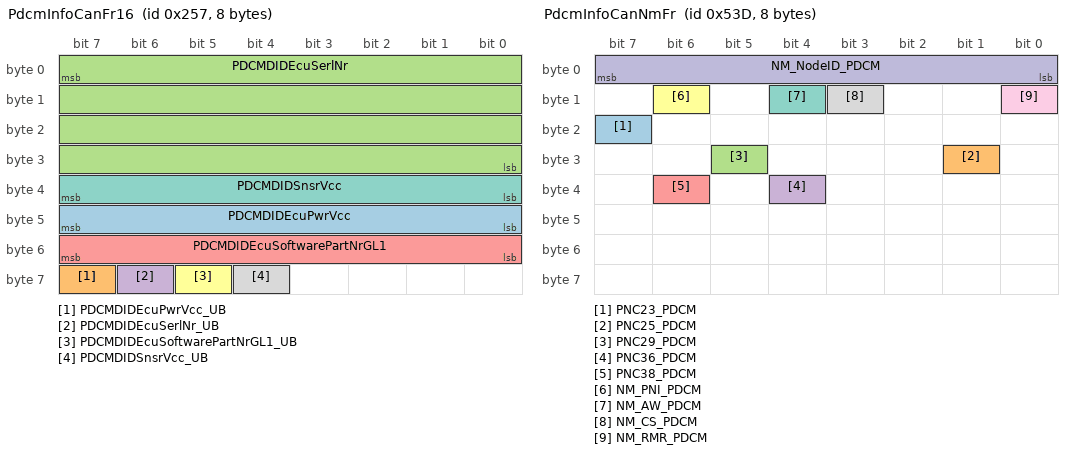
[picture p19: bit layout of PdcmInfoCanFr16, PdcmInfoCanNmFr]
BO_ 599 PdcmInfoCanFr16 : 8 PDCM
 SG_ PDCMDIDEcuPwrVcc : 47|8@0+ (1.0,0.0) [0.0|255.0] "Unitless" IHU
 SG_ PDCMDIDEcuPwrVcc_UB : 63|1@0+ (1,0) [0|1] "" IHU
 SG_ PDCMDIDEcuSerlNr : 7|32@0+ (1.0,0.0) [0.0|4294967295.0] "Unitless" IHU
 SG_ PDCMDIDEcuSerlNr_UB : 62|1@0+ (1,0) [0|1] "" IHU
 SG_ PDCMDIDEcuSoftwarePartNrGL1 : 55|8@0+ (1.0,0.0) [0.0|255.0] "Unitless" IHU
 SG_ PDCMDIDEcuSoftwarePartNrGL1_UB : 61|1@0+ (1,0) [0|1] "" IHU
 SG_ PDCMDIDSnsrVcc : 39|8@0+ (1.0,0.0) [0.0|255.0] "Unitless" IHU
 SG_ PDCMDIDSnsrVcc_UB : 60|1@0+ (1,0) [0|1] "" IHU

BO_ 406 PdcmInfoCanFr17 : 8 PDCM
 SG_ ObstacleMinimumDistanceRe1_UB : 23|1@0+ (1,0) [0|1] "" IHU
 SG_ ObstacleMinimumDistanceRe1MinDst : 22|9@0+ (1.0,0.0) [0.0|511.0] "Unitless" IHU
 SG_ ObstacleMinimumDistanceRe1MinDstPosn : 29|3@0+ (1,0) [0|7] "" IHU
 SG_ ObstacleMinimumDistanceRe1StopDispReq : 26|1@0+ (1,0) [0|1] "" IHU

BO_ 1341 PdcmInfoCanNmFr : 8 PDCM
 SG_ PNC23_PDCM : 23|1@0+ (1,0) [0|0] "" Vector__XXX
 SG_ PNC25_PDCM : 25|1@0+ (1,0) [0|0] "" Vector__XXX
 SG_ PNC29_PDCM : 29|1@0+ (1,0) [0|0] "" Vector__XXX
 SG_ PNC36_PDCM : 36|1@0+ (1,0) [0|0] "" Vector__XXX
 SG_ PNC38_PDCM : 38|1@0+ (1,0) [0|0] "" Vector__XXX
 SG_ NM_PNI_PDCM : 14|1@0+ (1,0) [0|0] "" Vector__XXX
 SG_ NM_AW_PDCM : 12|1@0+ (1,0) [0|0] "" Vector__XXX
 SG_ NM_CS_PDCM : 11|1@0+ (1,0) [0|0] "" Vector__XXX
 SG_ NM_RMR_PDCM : 8|1@0+ (1,0) [0|0] "" Vector__XXX
 SG_ NM_NodeID_PDCM : 7|8@0+ (1,0) [0|0] "" Vector__XXX

BO_ 1556 PdcmToDhuInfoCanDiagResFrame : 8 PDCM

CM_ BU_ AUD "Audio Module";
CM_ BU_ ETC "External Tester Connector";

CM_ SG_ 896 AcoustModSts "Feedback for acoustic mode";
CM_ SG_ 896 AudioMuteSts "AudioMuteSts";
CM_ SG_ 896 BalLvlSts "BalLvlSts";
CM_ SG_ 896 FaderLvlSts "faderlvlsts";
CM_ SG_ 896 Fgrnd1stForActvtSts "Fgrnd1stForActvtSts";
CM_ SG_ 896 Fgrnd2ndForActvtSts "Fgrnd2stForactvtSts";
CM_ SG_ 896 LvlOfBassSts "Uint5";
CM_ SG_ 896 LvlOfMidSts "LvlOfMidSts";
CM_ SG_ 896 LvlOfTrebleSts "LvlOfTrebleSts";
CM_ SG_ 896 RoomModeSts "RoomModeSts";
CM_ SG_ 896 SeatSoundPosnSts "SeatSoundPosnSts";
CM_ SG_ 896 VehSpdLvlSts "VehSpdLvlSts";
CM_ SG_ 897 BgrndForAudOutChStsAudOutpCh1 "AudioOutput Channel 1 Status";
CM_ SG_ 897 BgrndForAudOutChStsAudOutpCh10 "AudioOutput Channel 10 Status";
CM_ SG_ 897 BgrndForAudOutChStsAudOutpCh11 "AudioOutput Channel 11 Status";
CM_ SG_ 897 BgrndForAudOutChStsAudOutpCh12 "AudioOutput Channel 12 Status";
CM_ SG_ 897 BgrndForAudOutChStsAudOutpCh2 "AudioOutput Channel 2 Status";
CM_ SG_ 897 BgrndForAudOutChStsAudOutpCh3 "AudioOutput Channel 3 Status";
CM_ SG_ 897 BgrndForAudOutChStsAudOutpCh4 "AudioOutput Channel 4 Status";
CM_ SG_ 897 BgrndForAudOutChStsAudOutpCh5 "AudioOutput Channel 5 Status";
CM_ SG_ 897 BgrndForAudOutChStsAudOutpCh6 "AudioOutput Channel 6 Status";
CM_ SG_ 897 BgrndForAudOutChStsAudOutpCh7 "AudioOutput Channel 7 Status";
CM_ SG_ 897 BgrndForAudOutChStsAudOutpCh8 "AudioOutput Channel 8 Status";
CM_ SG_ 897 BgrndForAudOutChStsAudOutpCh9 "AudioOutput Channel 9 Status";
CM_ SG_ 897 Fgrnd1stForAudOutpChStsAudOutpCh1 "AudioOutput Channel 1 Status";
CM_ SG_ 897 Fgrnd1stForAudOutpChStsAudOutpCh10 "AudioOutput Channel 10 Status";
CM_ SG_ 897 Fgrnd1stForAudOutpChStsAudOutpCh11 "AudioOutput Channel 11 Status";
CM_ SG_ 897 Fgrnd1stForAudOutpChStsAudOutpCh12 "AudioOutput Channel 12 Status";
CM_ SG_ 897 Fgrnd1stForAudOutpChStsAudOutpCh2 "AudioOutput Channel 2 Status";
CM_ SG_ 897 Fgrnd1stForAudOutpChStsAudOutpCh3 "AudioOutput Channel 3 Status";
CM_ SG_ 897 Fgrnd1stForAudOutpChStsAudOutpCh4 "AudioOutput Channel 4 Status";
CM_ SG_ 897 Fgrnd1stForAudOutpChStsAudOutpCh5 "AudioOutput Channel 5 Status";
CM_ SG_ 897 Fgrnd1stForAudOutpChStsAudOutpCh6 "AudioOutput Channel 6 Status";
CM_ SG_ 897 Fgrnd1stForAudOutpChStsAudOutpCh7 "AudioOutput Channel 7 Status";
CM_ SG_ 897 Fgrnd1stForAudOutpChStsAudOutpCh8 "AudioOutput Channel 8 Status";
CM_ SG_ 897 Fgrnd1stForAudOutpChStsAudOutpCh9 "AudioOutput Channel 9 Status";
CM_ SG_ 897 Fgrnd1stForVolLvlSts "Fgrnd1stForVolLvlSts";
CM_ SG_ 897 Fgrnd2ndForAudOutpChStsAudOutpCh1 "AudioOutput Channel 1 Status";
CM_ SG_ 897 Fgrnd2ndForAudOutpChStsAudOutpCh10 "AudioOutput Channel 10 Status";
CM_ SG_ 897 Fgrnd2ndForAudOutpChStsAudOutpCh11 "AudioOutput Channel 11 Status";
CM_ SG_ 897 Fgrnd2ndForAudOutpChStsAudOutpCh12 "AudioOutput Channel 12 Status";
CM_ SG_ 897 Fgrnd2ndForAudOutpChStsAudOutpCh2 "AudioOutput Channel 2 Status";
CM_ SG_ 897 Fgrnd2ndForAudOutpChStsAudOutpCh3 "AudioOutput Channel 3 Status";
CM_ SG_ 897 Fgrnd2ndForAudOutpChStsAudOutpCh4 "AudioOutput Channel 4 Status";
CM_ SG_ 897 Fgrnd2ndForAudOutpChStsAudOutpCh5 "AudioOutput Channel 5 Status";
CM_ SG_ 897 Fgrnd2ndForAudOutpChStsAudOutpCh6 "AudioOutput Channel 6 Status";
CM_ SG_ 897 Fgrnd2ndForAudOutpChStsAudOutpCh7 "AudioOutput Channel 7 Status";
CM_ SG_ 897 Fgrnd2ndForAudOutpChStsAudOutpCh8 "AudioOutput Channel 8 Status";
CM_ SG_ 897 Fgrnd2ndForAudOutpChStsAudOutpCh9 "AudioOutput Channel 9 Status";
CM_ SG_ 897 Fgrnd2ndForVolLvlSts "Fgrnd2stForVolLvlSts";
CM_ SG_ 944 AmplifrOpSts "A2B Audio Power Mode";
CM_ SG_ 944 BgrndForVolLvlSts "BgrndForVolLvlSts";
CM_ SG_ 944 DiagState1 "diag signal 1";
CM_ SG_ 944 DiagState2 "diag signal 1";
CM_ SG_ 944 OutChState1 "signal to show channel 1 state";
CM_ SG_ 944 OutChState2 "signal to show channel 2 state";
CM_ SG_ 912 ArtificialSoundPreviewSts "the signal used to feedback preview of existed artificial sound";
CM_ SG_ 912 Chiming1MuteSts "feedback siganl used to mute channel 1";
CM_ SG_ 912 Chiming2MuteSts "feedback signal used to mute channel 2";
CM_ SG_ 912 Chiming3MuteSts "feedback signal used to mute channel 3";
CM_ SG_ 912 Chiming4MuteSts "feedback signal used to mute chennel 4";
CM_ SG_ 912 GearBoxTypToAmplfrSts "Gear box Type signal, feedback carconfig info to IVI";
CM_ SG_ 912 SeatMtrlToAmplfrSts "feedback for seat number";
CM_ SG_ 912 SeatNrToAmplfrSts "feedback for seat material";
CM_ SG_ 912 SpkrandAmplifrVariantTypeSts "feedbakc for speaker/channel number";
CM_ SG_ 912 TrdRowSeatMtrlToAmplfrSts "feedback for third row seat material";
CM_ SG_ 912 WarnIntrptLoglDHUSts "feedback signal used to audio warning";
CM_ SG_ 1040 VolLvlFgrnd2Ch1Sts "VolLvlFgrnd2Ch1Sts";
CM_ SG_ 1040 VolLvlFgrnd2Ch2Sts "VolLvlFgrnd2Ch2Sts";
CM_ SG_ 1040 VolLvlFgrnd2Ch3Sts "VolLvlFgrnd2Ch3Sts";
CM_ SG_ 1040 VolLvlFgrnd2Ch4Sts "VolLvlFgrnd2Ch4Sts";
CM_ SG_ 1040 VolLvlFgrnd2Ch5Sts "VolLvlFgrnd2Ch5Sts";
CM_ SG_ 1040 VolLvlFgrnd2Ch6Sts "VolLvlFgrnd2Ch6Sts";
CM_ SG_ 1040 VolLvlFgrnd2Ch7Sts "VolLvlFgrnd2Ch7Sts";
CM_ SG_ 80 AcoustEfectPrvtCinePsnSts "When user select Private Cinema mode, feedback the front/middle/rear position status.";
CM_ SG_ 80 BgrndForActvtSts "BG active/inactive status";
CM_ SG_ 80 CptAdvExtSwtSts " AUD feedback IHU the open or close status of sound compensating extending function.";
CM_ SG_ 80 Feedback1SelectSts "Feedback1SelectSts";
CM_ SG_ 80 Feedback2SelectSts "Feedback2SelectSts";
CM_ SG_ 80 VolLvlFgrnd2Ch10Sts "VolLvlFgrnd2Ch10Sts";
CM_ SG_ 80 VolLvlFgrnd2Ch11Sts "VolLvlFgrnd2Ch11Sts";
CM_ SG_ 80 VolLvlFgrnd2Ch12Sts "VolLvlFgrnd2Ch12Sts";
CM_ SG_ 80 VolLvlFgrnd2Ch8Sts "VolLvlFgrnd2Ch8Sts";
CM_ SG_ 80 VolLvlFgrnd2Ch9Sts "VolLvlFgrnd2Ch8Sts";
CM_ SG_ 33 AllmuteSts "feedback signal used to mute all sounds";
CM_ SG_ 33 AmplifrErrSts "AmplifrErrSts";
CM_ SG_ 33 ArtificialSoundOpenReqSts "feedback signal for artificial sound open";
CM_ SG_ 33 ArtificialSoundSelectReqSts "Feedback signal for artificial sound selection";
CM_ SG_ 33 BdyTypToAmplfrSts "feedback for body type";
CM_ SG_ 33 EngTypToAmplfrSts "feedback for engine type";
CM_ SG_ 33 NaviMuteSts "feedback signal used to mute navigation";
CM_ SG_ 33 PrpsnTypToAmplfrSts "Propulsion Type signal, feedback carconfig info to IVI";
CM_ SG_ 33 SteerWhlPosnToAmplfrSts "SteerWhlPosnToAmplfrSts";
CM_ SG_ 33 TeleMuteSts "feedback signal used to mute Telephone";
CM_ SG_ 949 OutChState3 "signal to show channel 3 state";
CM_ SG_ 949 OutChState4 "signal to show channel 4 state";
CM_ SG_ 949 VolLvlFgrnd0Sts "DHU2 A2B A3/A4 channel volumn status feedback signal";
CM_ SG_ 917 Audio2MuteSts "The signal indicates the status (or state) of the  Mute/Unmute A3/A4 channelfor AUD sounds";
CM_ SG_ 917 AudSpkrNrToAmplfrSts "feedback Port for CC audio speaker number info to IVI";
CM_ SG_ 917 IntrRoofMtrlToAmplfrSts "Feedback for Interior roof material info ";
CM_ SG_ 917 LndBtnSts "Feedback loudness button open or close status.";
CM_ SG_ 917 VehTypToAmplfrExtSts "VehTypToAmplfrExtSts";
CM_ SG_ 293 VolLvlA7Sts "staus of A7 volume";
CM_ SG_ 293 VolLvlA8Sts "staus of A8 volume";
CM_ SG_ 820 ExtrLtgStsAFS "AFS status";
CM_ SG_ 820 ExtrLtgStsAHBC "AHBC Status";
CM_ SG_ 820 ExtrLtgStsAHL "AHL Status";
CM_ SG_ 820 ExtrLtgStsAllWL "All Weather Light Status";
CM_ SG_ 820 ExtrLtgStsApproach "Approach Light Status";
CM_ SG_ 820 ExtrLtgStsChks "Checksum";
CM_ SG_ 820 ExtrLtgStsCntr "Counter";
CM_ SG_ 820 ExtrLtgStsCornrgLi "Cornering Light Status";
CM_ SG_ 820 ExtrLtgStsDBL "DBL Stataus";
CM_ SG_ 820 ExtrLtgStsDRL "DRL Status";
CM_ SG_ 820 ExtrLtgStsFlash "Flash Light Status";
CM_ SG_ 820 ExtrLtgStsFrntFog "Front Fog Light Status";
CM_ SG_ 820 ExtrLtgStsGoodbye "Good Bye Light Status";
CM_ SG_ 820 ExtrLtgStsHiBeam "Hi Beam Status";
CM_ SG_ 820 ExtrLtgStsHomeSafe "Home Safe Light Status";
CM_ SG_ 820 ExtrLtgStsHWL "HWL Status";
CM_ SG_ 820 ExtrLtgStsLoBeam "Low Beam Status";
CM_ SG_ 820 ExtrLtgStsLtgShow "Light Show Status";
CM_ SG_ 820 ExtrLtgStsPosLiFrnt "Position Light Front Status";
CM_ SG_ 820 ExtrLtgStsPosLiRe "Position Light Rear Status";
CM_ SG_ 820 ExtrLtgStsReFog "Rear Fog Light Status";
CM_ SG_ 820 ExtrLtgStsReverseLi "Reverse Light Status";
CM_ SG_ 820 ExtrLtgStsStopLi "Stop Light Status";
CM_ SG_ 820 ExtrLtgStsTurnIndrLe "Turn Indicator Left Status";
CM_ SG_ 820 ExtrLtgStsTurnIndrRi "Turn Indicator Right Status
";
CM_ SG_ 820 ExtrLtgStsWelcome "Welcome Light Status";
CM_ SG_ 398 BrkPedlrRatPerc "Brake pedal Ratio in percentage value";
CM_ SG_ 398 BrkPedlrRatQf "quality factor";
CM_ SG_ 368 CptAdvExtSwt "Signial send by IHU to open and close the function of AUD sound compensating extending.";
CM_ SG_ 379 AmplifrTurnOn "Turn On/OFF Audio Power";
CM_ SG_ 379 ANCcfgToAmplfr "ANC configuration signal";
CM_ SG_ 379 ArtificialSoundOpenReq "Artificial sound open or close";
CM_ SG_ 379 ArtificialSoundSelectReq "Select artificial sound type";
CM_ SG_ 399 Allmute "signal used to mute all sounds";
CM_ SG_ 399 Chiming1Mute "siganl used to mute channel 1";
CM_ SG_ 399 Chiming2Mute "signal used to mute channel 2";
CM_ SG_ 399 Chiming3Mute "signal used to mute channel 3";
CM_ SG_ 399 Chiming4Mute "signal used to mute chennel 4";
CM_ SG_ 399 NaviMute "signal used to mute navigation";
CM_ SG_ 399 TeleMute "signal used to mute Telephone";
CM_ SG_ 399 VolLvlFgrnd0 "signal used to adjust volume";
CM_ SG_ 399 WarnIntrptLoglDHU "signal used to audio warning";
CM_ SG_ 384 MonrSysSts1 "Indicate AVM working status.";
CM_ SG_ 384 WhlRotToothCntrChks "check sum";
CM_ SG_ 384 WhlRotToothCntrCntr "counter";
CM_ SG_ 384 WhlRotToothCntrFrntLe "Wheel rotation ticks for each individual wheel. Wheel rotation impuls counter front left. For one complete wheel revolution the counter will increase by 96 (with 48 magnetic pole-pairs).";
CM_ SG_ 384 WhlRotToothCntrFrntRi "Wheel rotation ticks for each individual wheel. Wheel rotation impuls counter front right. For one complete wheel revolution the counter will increase by 96 (with 48 magnetic pole-pairs).";
CM_ SG_ 384 WhlRotToothCntrReLe "Wheel rotation ticks for each individual wheel. Wheel rotation impuls counter rear left. For one complete wheel revolution the counter will increase by 96 (with 48 magnetic pole-pairs).";
CM_ SG_ 384 WhlRotToothCntrReRi "Wheel rotation ticks for each individual wheel. Wheel rotation impuls counter rear right. For one complete wheel revolution the counter will increase by 96 (with 48 magnetic pole-pairs).";
CM_ SG_ 378 PdcLoMuteBtnReq "PDC (4 or 8 radar) mute button";
CM_ SG_ 378 PrkgDstCtrlLoSysSwt "PDC (4 or 8 radar) switch.";
CM_ SG_ 378 PrpsnTypToAmplfr "Propulsion Type signal, transfer carconfig Infomation to AUD.";
CM_ SG_ 378 SupPfmncModReq "Super performance mode request";
CM_ SG_ 517 PrkgAssiReSts "Indicate PAC working status.";
CM_ SG_ 320 LvlOfpoint2 "level of 80Hz";
CM_ SG_ 320 LvlOfpoint5 "level of 5kHz";
CM_ SG_ 320 Spacapsule "space capsule on/off";
CM_ SG_ 326 HdrestMod "headrest";
CM_ SG_ 326 LockgCenStsLockSt "Signal LockgCenSts provides central locking status to other subsystems.
Signal is a record with three items
- LockSt (Lock State)
- TrigSrc (Trig Source)
- UpdEve (Will be set to TRUE during one second at each new central locking or unlocking event)";
CM_ SG_ 326 LockgCenStsTrigSrc "Signal LockgCenSts provides central locking status to other subsystems.
Signal is a record with three items
- LockSt (Lock State)
- TrigSrc (Trig Source)
- UpdEve (Will be set to TRUE during one second at each new central locking or unlocking event)";
CM_ SG_ 326 LockgCenStsUpdEve "Signal LockgCenSts provides central locking status to other subsystems.
Signal is a record with three items
- LockSt (Lock State)
- TrigSrc (Trig Source)
- UpdEve (Will be set to TRUE during one second at each new central locking or unlocking event)";
CM_ SG_ 326 LvlOfpoint3 "level of 500Hz";
CM_ SG_ 352 LvlOfpoint1 "level of 40Hz";
CM_ SG_ 352 LvlOfpoint4 "level of 1kHz";
CM_ SG_ 352 TiAndDateIndcnDataValid "Current time (Hr, Min and Sec) and date (Year, Months and days) data for indication. See requirement for more information about the signals. Signal qualifier, No means values should be ignored.";
CM_ SG_ 352 TiAndDateIndcnDay "Current time (Hr, Min and Sec) and date (Year, Months and days) data for indication. See requirement for more information about the signals. Day";
CM_ SG_ 352 TiAndDateIndcnHr1 "Current time (Hr, Min and Sec) and date (Year, Months and days) data for indication. See requirement for more information about the signals. Hour";
CM_ SG_ 352 TiAndDateIndcnMins1 "Current time (Hr, Min and Sec) and date (Year, Months and days) data for indication. See requirement for more information about the signals. Minutes";
CM_ SG_ 352 TiAndDateIndcnMth1 "Current time (Hr, Min and Sec) and date (Year, Months and days) data for indication. See requirement for more information about the signals. Month, 1-12";
CM_ SG_ 352 TiAndDateIndcnSec1 "Current time (Hr, Min and Sec) and date (Year, Months and days) data for indication. See requirement for more information about the signals. Seconds";
CM_ SG_ 352 TiAndDateIndcnYr1 "Current time (Hr, Min and Sec) and date (Year, Months and days) data for indication. See requirement for more information about the signals. Year, 0-99";
CM_ SG_ 890 AdpvBassEnhmtAdjmtOnOff1 "to switch on/off the function";
CM_ SG_ 890 AdpvBassEnhmtAdjmtsurroundlvlAdjmt "to change the level of the function";
CM_ SG_ 890 RadioSrcSts "Used for defining if current media source is radio or not.";
CM_ SG_ 890 ThreeDimSurAdjmtOnOff1 "on/off";
CM_ SG_ 890 ThreeDimSurAdjmtsurroundlvlAdjmt "Surround level";
CM_ SG_ 890 TwoDimSurAdjmtOnOff1 "to switch on/off the function";
CM_ SG_ 890 TwoDimSurAdjmtsurroundlvlAdjmt "to change the level of the function";
CM_ SG_ 890 VarEqualizerAdjmt "to change the audio function between different user scenario  ";
CM_ SG_ 346 IndcnUnitClkFmt "Clock Format";
CM_ SG_ 346 IndcnUnitDateFmt "DateFormat";
CM_ SG_ 346 IndcnUnitDstLong "Long Distance Units";
CM_ SG_ 346 IndcnUnitDstSho "Short Distance Units";
CM_ SG_ 346 IndcnUnitFuCnsUnit "Fuel Consumption Units";
CM_ SG_ 346 IndcnUnitPUnit "Pressure Unit";
CM_ SG_ 346 IndcnUnitSpdUnit "Speed Units";
CM_ SG_ 346 IndcnUnitTUnit "Temperature Unit";
CM_ SG_ 346 IndcnUnitVolUnit "Volume Units";
CM_ SG_ 353 MediaSouce "media souce from PSD/CSD";
CM_ SG_ 353 PassHdrestSwt "Passenger Headrest Switch";
CM_ SG_ 353 PSDConnectBTHeadSetSts "PSD Connect BTHeadSet Status";
CM_ SG_ 353 PtDrvrSetg "PtDrvrSetg";
CM_ SG_ 353 RSDLConnectBTHeadSetSts "RSDL Connect BTHeadSet Status";
CM_ SG_ 353 RSDRConnectBTHeadSetSts "RSDR Connect BTHeadSet Status";
CM_ SG_ 353 SRDLConnectBTHeadSetSts "SRDL Connect BTHeadSet Status";
CM_ SG_ 353 SRDRConnectBTHeadSetSts "SRDR Connect BTHeadSet Status";
CM_ SG_ 353 VirtVenueMod "Virtual Venue mode";
CM_ SG_ 353 VirtVenueOnOff1 "on/off";
CM_ SG_ 272 ActvtFgrnd2 "ActvtFgrnd2";
CM_ SG_ 272 Audiomode "audio mode";
CM_ SG_ 272 Fgrnd2ForAudOutpChAudOutpCh1 "AudOutpCh1";
CM_ SG_ 272 Fgrnd2ForAudOutpChAudOutpCh10 "AudOutpCh10";
CM_ SG_ 272 Fgrnd2ForAudOutpChAudOutpCh11 "AudOutpCh11";
CM_ SG_ 272 Fgrnd2ForAudOutpChAudOutpCh12 "AudOutpCh12";
CM_ SG_ 272 Fgrnd2ForAudOutpChAudOutpCh2 "AudOutpCh2";
CM_ SG_ 272 Fgrnd2ForAudOutpChAudOutpCh3 "AudOutpCh3";
CM_ SG_ 272 Fgrnd2ForAudOutpChAudOutpCh4 "AudOutpCh4";
CM_ SG_ 272 Fgrnd2ForAudOutpChAudOutpCh5 "AudOutpCh5";
CM_ SG_ 272 Fgrnd2ForAudOutpChAudOutpCh6 "AudOutpCh6";
CM_ SG_ 272 Fgrnd2ForAudOutpChAudOutpCh7 "AudOutpCh7";
CM_ SG_ 272 Fgrnd2ForAudOutpChAudOutpCh8 "AudOutpCh8";
CM_ SG_ 272 Fgrnd2ForAudOutpChAudOutpCh9 "AudOutpCh9";
CM_ SG_ 272 SeatOccptAtRowThrdMid "Occupant presence status at 3rd row ,  right position.";
CM_ SG_ 272 VolLvlA7 "A7 volume";
CM_ SG_ 272 VolLvlA8 "A8 volume";
CM_ SG_ 913 AcoustMod "AcoustMod";
CM_ SG_ 913 ActvtBgrnd "ActvtBgrnd";
CM_ SG_ 913 DrvrSeatSnsrSts "Informs if there is a fault on the driver seat sensor is detected through electrical measurements, or plausibility judgement. NotOk means sensor is judged as faulty. Di means that the sensor is not configured.";
CM_ SG_ 913 DrvrSeatSts "Describes if an occupant is detected in the driver seat.";
CM_ SG_ 913 FaderLvl "FaderLvl";
CM_ SG_ 913 Feedback1Select "Feedback1Select";
CM_ SG_ 913 Feedback2Select "Feedback2Select";
CM_ SG_ 913 LvlOfBass "LvlOfBass";
CM_ SG_ 913 LvlOfMid "LvlOfMid";
CM_ SG_ 913 LvlOfTreble "LvlOfTreble";
CM_ SG_ 913 RoomMode "RoomMode";
CM_ SG_ 913 SeatSoundPosn "Seat Sound Position for BG sounds";
CM_ SG_ 913 VolLvlBgrnd "VolLvlBgrnd";
CM_ SG_ 336 ActvtFgrnd1 "ActvtFgrnd1";
CM_ SG_ 336 AudioMute "AudioMute";
CM_ SG_ 336 BalLvl "BalLvl";
CM_ SG_ 336 BgrndForAudOutpChAudOutpCh1 "AudOutpCh1";
CM_ SG_ 336 BgrndForAudOutpChAudOutpCh10 "AudOutpCh10";
CM_ SG_ 336 BgrndForAudOutpChAudOutpCh11 "AudOutpCh11";
CM_ SG_ 336 BgrndForAudOutpChAudOutpCh12 "AudOutpCh12";
CM_ SG_ 336 BgrndForAudOutpChAudOutpCh2 "AudOutpCh2";
CM_ SG_ 336 BgrndForAudOutpChAudOutpCh3 "AudOutpCh3";
CM_ SG_ 336 BgrndForAudOutpChAudOutpCh4 "AudOutpCh4";
CM_ SG_ 336 BgrndForAudOutpChAudOutpCh5 "AudOutpCh5";
CM_ SG_ 336 BgrndForAudOutpChAudOutpCh6 "AudOutpCh6";
CM_ SG_ 336 BgrndForAudOutpChAudOutpCh7 "AudOutpCh7";
CM_ SG_ 336 BgrndForAudOutpChAudOutpCh8 "AudOutpCh8";
CM_ SG_ 336 BgrndForAudOutpChAudOutpCh9 "AudOutpCh9";
CM_ SG_ 336 SpkrandAmplifrVariantType "Speaker Number";
CM_ SG_ 336 VehSpdLvl "Vehicle Speed Compensation for all of sounds";
CM_ SG_ 336 VolLvlFgrnd1 "VolLvlFgrnd1";
CM_ SG_ 1041 VolLvlFgrnd2Ch1 "Volume for FG2 Channel 1";
CM_ SG_ 1041 VolLvlFgrnd2Ch2 "Volume for FG2 Channel 2";
CM_ SG_ 1041 VolLvlFgrnd2Ch3 "Volume for FG2 Channel 3";
CM_ SG_ 1041 VolLvlFgrnd2Ch4 "Volume for FG2 Channel 4";
CM_ SG_ 1041 VolLvlFgrnd2Ch5 "Volume for FG2 Channel 5";
CM_ SG_ 1041 VolLvlFgrnd2Ch6 "Volume for FG2 Channel 6";
CM_ SG_ 1041 VolLvlFgrnd2Ch7 "Volume for FG2 Channel 7";
CM_ SG_ 304 Fgrnd1ForAudOutpChAudOutpCh1 "AudOutpCh1";
CM_ SG_ 304 Fgrnd1ForAudOutpChAudOutpCh10 "AudOutpCh10";
CM_ SG_ 304 Fgrnd1ForAudOutpChAudOutpCh11 "AudOutpCh11";
CM_ SG_ 304 Fgrnd1ForAudOutpChAudOutpCh12 "AudOutpCh12";
CM_ SG_ 304 Fgrnd1ForAudOutpChAudOutpCh2 "AudOutpCh2";
CM_ SG_ 304 Fgrnd1ForAudOutpChAudOutpCh3 "AudOutpCh3";
CM_ SG_ 304 Fgrnd1ForAudOutpChAudOutpCh4 "AudOutpCh4";
CM_ SG_ 304 Fgrnd1ForAudOutpChAudOutpCh5 "AudOutpCh5";
CM_ SG_ 304 Fgrnd1ForAudOutpChAudOutpCh6 "AudOutpCh6";
CM_ SG_ 304 Fgrnd1ForAudOutpChAudOutpCh7 "AudOutpCh7";
CM_ SG_ 304 Fgrnd1ForAudOutpChAudOutpCh8 "AudOutpCh8";
CM_ SG_ 304 Fgrnd1ForAudOutpChAudOutpCh9 "AudOutpCh9";
CM_ SG_ 304 NotifForEmgyCall "Information if there is a need for the vehicle to perform an emergency call.";
CM_ SG_ 304 VolLvlFgrnd2Ch10 "Volume for FG2 Channel 10";
CM_ SG_ 304 VolLvlFgrnd2Ch11 "Volume for FG2 Channel 11";
CM_ SG_ 304 VolLvlFgrnd2Ch12 "Volume for FG2 Channel 12";
CM_ SG_ 304 VolLvlFgrnd2Ch8 "Volume for FG2 Channel 9";
CM_ SG_ 304 VolLvlFgrnd2Ch9 "Volume for FG2 Channel 9";
CM_ SG_ 914 ActvAudKtvMod "Request Audio On/Off Ktv Mode";
CM_ SG_ 914 BdyTypToAmplfr "body type";
CM_ SG_ 914 EngTypToAmplfr "engine type";
CM_ SG_ 914 SeatMtrlToAmplfr "seat material";
CM_ SG_ 914 SeatNrToAmplfr "seat number";
CM_ SG_ 914 SteerWhlPosnToAmplfrExt "Steer Wheel Position Information";
CM_ SG_ 914 TrdRowSeatMtrlToAmplfr "third row seat material";
CM_ SG_ 914 VolLvlA9 "volume of A9";
CM_ SG_ 344 DoorPassHndlSts "To inform about passenger door handle status, i.e. unknown, opened, closed according to
DoorPassHndlSts
- Ukwn
- FullRtrctd
- MovgOut
- StopDurgDply
- FullDplyd
- MovgIn
- StopDurgRtrct
- Flt";
CM_ SG_ 344 DrvModReq "drive mode";
CM_ SG_ 344 MmedAudPwrMod "Multimedia Audio Power Mode";
CM_ SG_ 849 EngSt1WdStsChks "checksum";
CM_ SG_ 849 EngSt1WdStsCntr "counter";
CM_ SG_ 849 EngSt1WdStsEngSt1WdSts "Signaling the state of the powerpack";
CM_ SG_ 849 LvlOfpoint6 "level of 16kHz";
CM_ SG_ 849 VehModMngtGlbSafe1CarModSts1 "CarMode Status";
CM_ SG_ 849 VehModMngtGlbSafe1CarModSubtypWdCarModSubtyp "CarMode substate status";
CM_ SG_ 849 VehModMngtGlbSafe1Chks "Checksum";
CM_ SG_ 849 VehModMngtGlbSafe1Cntr "Counter";
CM_ SG_ 849 VehModMngtGlbSafe1EgyLvlElecMai "Main energy level in the vehicle.";
CM_ SG_ 849 VehModMngtGlbSafe1EgyLvlElecSubtyp "Substate of the energy level in the vehicle.";
CM_ SG_ 849 VehModMngtGlbSafe1FltEgyCnsWdSts "High quiescent current detected by CEM via BMS.";
CM_ SG_ 849 VehModMngtGlbSafe1PwrLvlElecMai "Main Power level in the vehicle.";
CM_ SG_ 849 VehModMngtGlbSafe1PwrLvlElecSubtyp "Substate of the power level in the vehicle.";
CM_ SG_ 849 VehModMngtGlbSafe1UsgModSts "UsageMode Status";
CM_ SG_ 1104 BkpOfDstTrvld "total traveled distance.";
CM_ SG_ 1104 CarTiGlb "Presents a tiime value that shall be used by all ECUs to time-stamp diagnsotic trouble codes (DTC) according to the requirements for Global DTC snapshot data.";
CM_ SG_ 32 AmbTIndcdWithUnitAmbTIndcd "Indicated ambient temperature";
CM_ SG_ 32 AmbTIndcdWithUnitAmbTIndcdUnit "Unit of the indicated temperature";
CM_ SG_ 32 AmbTIndcdWithUnitQF "QF";
CM_ SG_ 32 MmedAudCurrLim "Multimedia Aud current Limit
";
CM_ SG_ 32 VehSpdLgtA "Vehicle speed longitudinal based on wheel speed sensors and longitudinal acceleration.";
CM_ SG_ 32 VehSpdLgtChks "Checksum";
CM_ SG_ 32 VehSpdLgtCntr "Counter";
CM_ SG_ 32 VehSpdLgtQf "Quality factor for vehicle speed as measured by wheel speed sensors and longitudinal acceleration.";
CM_ SG_ 7 IsgTqActChks "Checksum";
CM_ SG_ 7 IsgTqActCntr "Counter";
CM_ SG_ 7 IsgTqActIsgTqAct "Actual torque";
CM_ SG_ 7 IsgTqActQualityFactor "Quality factor";
CM_ SG_ 7 PtGearAct "Actual gear.";
CM_ SG_ 7 WinPosnStsAtDrvr "Signal sent to inform the rest of the car of the window position status for the front driver side door. The value of the signal is either an approximated percentage of openness, of the window is moving or if the position is unkown.
";
CM_ SG_ 7 WinPosnStsAtPass "Signal sent to inform the rest of the car of the window position status for the front passenger side door. The value of the signal is either an approximated percentage of openness, of the window is moving or if the position is unkown.
";
CM_ SG_ 7 WinPosnStsAtReLe "Signal sent to inform the rest of the car of the window position status for the rear driver side door. The value of the signal is either an approximated percentage of openness, of the window is moving or if the position is unkown.

";
CM_ SG_ 7 WinPosnStsAtReRi "Signal sent to inform the rest of the car of the window position status for the rear passenger side door. The value of the signal is either an approximated percentage of openness, of the window is moving or if the position is unkown.
";
CM_ SG_ 11 AccrPedlRatAccrPedlRat "Accelerator Pedal Position with adapted 0 point. Value as percentage of fully pressed pedal";
CM_ SG_ 11 AccrPedlRatChks "Accelerator Pedal Position with adapted 0 point. Value as percentage of fully pressed pedal. Checksum";
CM_ SG_ 11 AccrPedlRatCntr "Accelerator Pedal Position with adapted 0 point. Value as percentage of fully pressed pedal. Counter";
CM_ SG_ 11 GearLvrIndcn "Gear lever indication (drivetrain position) to the driver. If drivetrain position is not possible to decide signal is set to undefined. Valid for automatic vehicles.
";
CM_ SG_ 11 IsgSpdActSgn "Actual ISG speed with sign to indicate forward or backward direction";
CM_ SG_ 11 SunRoofPosnSts "Sun roof position status";
CM_ SG_ 11 ThrPos " ECM  throttle position (AbsThrottlePosition) on CAN";
CM_ SG_ 37 AccrPedlPsdAccrPedlPsd "Describes if the accelerator pedal is pressed. Will indicate pressed for a small pedal press. Accompanying status signal will indicate the integrity of the information.";
CM_ SG_ 37 AccrPedlPsdChks "Describes if the accelerator pedal is pressed. Will indicate pressed for a small pedal press.checksum";
CM_ SG_ 37 AccrPedlPsdCntr "Describes if the accelerator pedal is pressed. Will indicate pressed for a small pedal press.couner";
CM_ SG_ 37 AccrPedlPsdSts "Describes if the accelerator pedal is pressed. Will indicate pressed for a small pedal press. Accompanying status signal will indicate the integrity of the information. AccrPedlPsd fulfills ASIL C integrity";
CM_ SG_ 37 EngNSafeEngN "Engine Speed [rpm] and Engine Speed derivative [rpm/s]";
CM_ SG_ 37 EngNSafeEngNChks "Engine Speed [rpm] and Engine Speed derivative [rpm/s]";
CM_ SG_ 37 EngNSafeEngNCntr "Engine Speed [rpm] and Engine Speed derivative [rpm/s]";
CM_ SG_ 37 EngNSafeEngNGrdt "Engine Speed [rpm] and Engine Speed derivative [rpm/s]";
CM_ SG_ 37 HoodSts "HoodSts - Hood Status
Ukwn - Unknown status
Opend - Opened
Clsd - Closed";
CM_ SG_ 41 DoorDrvrSts "DoorDrvrSts - Driver Door Status
Ukwn - Unknown status
Opend - Opened
Clsd - Closed";
CM_ SG_ 41 DoorLeReSts "DoorLeReSts - Left Rear Side Door Status.
Ukwn - Unknown status
Opend - Opened
Clsd - Closed";
CM_ SG_ 41 DoorPassSts "DoorPassSts - Passenger Door Status
Ukwn - Unknown status
Opend - Opened
Clsd - Closed";
CM_ SG_ 41 DoorRiReSts "DoorRiReSts - Right Rear Side Door Status
Ukwn - Unknown status
Opend - Opened
Clsd - Closed";
CM_ SG_ 41 OverBoostSts "0:OverBoost not active 1:OverBoost active";
CM_ SG_ 41 TrSts "TrSts - Tailgate or Bootlid Status
Ukwn - Unknown status
Opend - Opened
Clsd - Closed";
CM_ SG_ 41 WhlSpdCircumlReChks "Individual wheel speed from rear wheel speed sensors. Checksum";
CM_ SG_ 41 WhlSpdCircumlReCntr "Individual wheel speed from rear wheel speed sensors. Counter";
CM_ SG_ 41 WhlSpdCircumlReLe "Individual wheel speed from rear wheel speed sensors. Wheel speed from rear left wheel speed sensor using nominal value of wheel radius.";
CM_ SG_ 41 WhlSpdCircumlReLeQf "Individual wheel speed from rear wheel speed sensors. Qf for wheel speed sensor";
CM_ SG_ 41 WhlSpdCircumlReRi "Individual wheel speed from rear wheel speed sensors. Wheel speed from rear right wheel speed sensor using nominal value of wheel radius.";
CM_ SG_ 41 WhlSpdCircumlReRiQf "Individual wheel speed from rear wheel speed sensors. Qf for wheel speed sensor";
CM_ SG_ 341 AmbTRawAmbTVal "Unfiltered ambient temp raw data in deg C. Ambient temp value";
CM_ SG_ 341 AmbTRawQly "Unfiltered ambient temp raw data in deg C. Quality Factor of the ambient temp";
CM_ SG_ 341 IsgIDc "DC current measured by the front inverter";
CM_ SG_ 341 IsgTqReq "Requested ISG motor torque on the crankshaft. The torque is positive in the forward rotation direction. ";
CM_ SG_ 341 IsgUDc "HVDC voltage";
CM_ SG_ 357 PtTqSetSafeChks "checksum";
CM_ SG_ 357 PtTqSetSafeCntr "counter";
CM_ SG_ 357 PtTqSetSafeGrdtNeg "Negative Gradient limit";
CM_ SG_ 357 PtTqSetSafeGrdtPos "Positive gradient limit";
CM_ SG_ 357 PtTqSetSafeReq "Request";
CM_ SG_ 314 CmptmtTFrntCmptmtTFrnt "Measured temperature in compartment. ";
CM_ SG_ 314 CmptmtTFrntFanForCmptmtTRunng "Fan for component temperature requirement.";
CM_ SG_ 314 CmptmtTFrntQf "Component temperature sensor signal quality.";
CM_ SG_ 314 DoorDrvrHndlSts "To inform about driver door handle status, i.e. unknown, opened, closed according to
DoorDrvrHndlSts
- Ukwn
- FullRtrctd
- MovgOut
- StopDurgDply
- FullDplyd
- MovgIn
- StopDurgRtrct
- Flt";
CM_ SG_ 314 DoorLeReHndlSts "To inform about left rear door handle status, i.e. unknown, opened, closed according to
DoorLeReHndlSts
- Ukwn
- FullRtrctd
- MovgOut
- StopDurgDply
- FullDplyd
- MovgIn
- StopDurgRtrct
- Flt";
CM_ SG_ 314 DoorRiReHndlSts "To inform about right rear door handle status, i.e. unknown, opened, closed according to
DoorRiReHndlSts
- Ukwn
- FullRtrctd
- MovgOut
- StopDurgDply
- FullDplyd
- MovgIn
- StopDurgRtrct
- Flt";
CM_ SG_ 314 TrOpenerSts "To inform about POT status. moving, opened, closed...";
CM_ SG_ 314 WhlMotSysTqReq "Requested electric motor torque referred to the wheel axle. The torque is positive in the forward rotation direction. ";
CM_ SG_ 85 SteerWhlSnsrAg "Actual steering wheel angle from the actual centre position of the steering wheel. ";
CM_ SG_ 85 SteerWhlSnsrAgSpd "Actual steering wheel angle from the actual centre position of the steering wheel. Steering angle speed with steering wheel rotation direction.  ";
CM_ SG_ 85 SteerWhlSnsrChks "Checksum for steering wheel sensor data.";
CM_ SG_ 85 SteerWhlSnsrCntr "Counter value for steering wheel sensor data.";
CM_ SG_ 85 SteerWhlSnsrQf "Qf for steering wheel sensor information";
CM_ SG_ 257 BrkPedlPsdBrkPedlNotPsdSafe "Set to 1 if brake pedal is not pressed, otherwise 0";
CM_ SG_ 257 BrkPedlPsdBrkPedlPsd "Set to 1 if brake pedal is pressed, otherwise 0";
CM_ SG_ 257 BrkPedlPsdChks "Checksum";
CM_ SG_ 257 BrkPedlPsdCntr "Counter";
CM_ SG_ 257 BrkPedlPsdQf "Quality factor";
CM_ SG_ 257 WhlSpdCircumlFrntChks "Individual wheel speed from front wheel speed sensors. Checksum";
CM_ SG_ 257 WhlSpdCircumlFrntCntr "Individual wheel speed from front wheel speed sensors. Counter";
CM_ SG_ 257 WhlSpdCircumlFrntLe "Individual wheel speed from front wheel speed sensors. Wheel speed from front left wheel speed sensor using nominal value of wheel radius.";
CM_ SG_ 257 WhlSpdCircumlFrntLeQf "Individual wheel speed from front wheel speed sensors. Qf for wheel speed sensor";
CM_ SG_ 257 WhlSpdCircumlFrntRiQf "Individual wheel speed from front wheel speed sensors. Qf for wheel speed sensor";
CM_ SG_ 257 WhlSpdCircumlFrntWhlSpdCircumlFrntRi "Individual wheel speed from front wheel speed sensors. Wheel speed from front right wheel speed sensor using nominal value of wheel radius";
CM_ SG_ 362 ProfPenSts1 "Signal communicates which profile that is active in the car
(Personal settings).";
CM_ SG_ 362 RoadInclnQly "Road inclination information. The road inclination is negative when the vehicle is facing uphill and positive when the vehicle is facing downhill. Quality information for road inclination";
CM_ SG_ 362 RoadInclnRoadIncln "Road inclination information. The road inclination is negative when the vehicle is facing uphill and positive when the vehicle is facing downhill.";
CM_ SG_ 362 VehBattUSysU "Vehicle System Voltage At 12V side";
CM_ SG_ 362 VehBattUSysUQf "Present vehicle voltage measured by CEM with QF";
CM_ SG_ 362 VehMtnStChks "Vehicle motion state information based on wheel speed sensors. Provides information about vehicle stand still and vehicle rolling direction. Checksum for vehicle motion state";
CM_ SG_ 362 VehMtnStCntr "Vehicle motion state information based on wheel speed sensors. Provides information about vehicle stand still and vehicle rolling direction. Counter for vehicle motion state";
CM_ SG_ 362 VehMtnStVehMtnSt "Vehicle motion state information based on wheel speed sensors. Provides information about vehicle stand still and vehicle rolling direction. Vehicle motion state";
CM_ SG_ 848 AcoustEfectPrvtCinePsn "When user select Private Cinema mode, there are 3 2nd level selections for user to select the front/middle/rear position to change the sound effect";
CM_ SG_ 848 Audio2Mute "Mute/Unmute A3/A4 channel for AUD sounds";
CM_ SG_ 848 CrashStsSafeChks "Checksum for E2E";
CM_ SG_ 848 CrashStsSafeCntr "Counter for E2E";
CM_ SG_ 848 CrashStsSafeSts "Information if a crash has been detected by SRS.";
CM_ SG_ 848 RecOfImpctCrashFrnt "Crash information, if crash is frontal";
CM_ SG_ 848 RecOfImpctCrashOffroadA "Incident information, if driving off road and becoming airbourne has been detected.";
CM_ SG_ 848 RecOfImpctCrashOffroadD "Inicdent information, if driving into a ditch has been detected";
CM_ SG_ 848 RecOfImpctCrashOffroadRT "Incident information, if driving off the road and into rough terrain has been detected.";
CM_ SG_ 848 RecOfImpctCrashOffroadRTsevere "Incident information, if driving off road and into severe rough terrain has been detected.";
CM_ SG_ 848 RecOfImpctCrashPed "Incident information, if a pedestrian protection triggering has been made";
CM_ SG_ 848 RecOfImpctCrashRe "Crash information, if crash is rear";
CM_ SG_ 848 RecOfImpctCrashRollovr "Crash information, if crash is roll-over";
CM_ SG_ 848 RecOfImpctCrashSideLe "Crash information, if crash is left side";
CM_ SG_ 848 RecOfImpctCrashSideRi "Crash information, if crash is right side";
CM_ SG_ 848 RecOfImpctCrashState "Crash information, State of the crash";
CM_ SG_ 848 RecOfImpctImpctDvx "Crash information, change in velocity in x-direction";
CM_ SG_ 848 RecOfImpctImpctDvy "Crash information, change in velocity in y-direction";
CM_ SG_ 848 RecOfImpctImpctRollAg "Crash information, cumulative roll angle";
CM_ SG_ 848 RecOfImpctVehOri "Crash information, Vehicle orientation once crash subsides";
CM_ SG_ 613 VinBlockNr "VIN number block counter. ";
CM_ SG_ 613 VinVINSignalPos1 "VIN byte 1. Used for character 1, 8 and 15.";
CM_ SG_ 613 VinVINSignalPos2 "VIN byte 2. Used for character 2, 9 and 16.";
CM_ SG_ 613 VinVINSignalPos3 "VIN byte 3. Used for character 3, 10 and 17.";
CM_ SG_ 613 VinVINSignalPos4 "VIN byte 4. Used for character 4 and 11.";
CM_ SG_ 613 VinVINSignalPos5 "VIN byte 5. Used for character 5 and 12.";
CM_ SG_ 613 VinVINSignalPos6 "VIN byte 6. Used for character 6 and 13.";
CM_ SG_ 613 VinVINSignalPos7 "VIN byte 7. Used for character 7 and 14.";
CM_ SG_ 529 VehCfgPrmBlkIDBytePosn1 "signal block counter.";
CM_ SG_ 529 VehCfgPrmCCPBytePosn2 " (BlockID-1)*7 + 1. ";
CM_ SG_ 529 VehCfgPrmCCPBytePosn3 " (BlockID-1)*7 + 2. ";
CM_ SG_ 529 VehCfgPrmCCPBytePosn4 " (BlockID-1)*7 + 3. ";
CM_ SG_ 529 VehCfgPrmCCPBytePosn5 " (BlockID-1)*7 + 4. ";
CM_ SG_ 529 VehCfgPrmCCPBytePosn6 " (BlockID-1)*7 + 5. ";
CM_ SG_ 529 VehCfgPrmCCPBytePosn7 " (BlockID-1)*7 + 6. ";
CM_ SG_ 529 VehCfgPrmCCPBytePosn8 " (BlockID-1)*7 + 7. ";
CM_ SG_ 560 VehCfgPrmExtBlkIDBytePosn1 "CarConfigExtended BlockID";
CM_ SG_ 560 VehCfgPrmExtCCPBytePosn2 "CarConfigExtended BytePos2";
CM_ SG_ 560 VehCfgPrmExtCCPBytePosn3 "CarConfigExtended BytePos3";
CM_ SG_ 560 VehCfgPrmExtCCPBytePosn4 "CarConfigExtended BytePos4";
CM_ SG_ 560 VehCfgPrmExtCCPBytePosn5 "CarConfigExtended BytePos5";
CM_ SG_ 560 VehCfgPrmExtCCPBytePosn6 "CarConfigExtended BytePos6";
CM_ SG_ 560 VehCfgPrmExtCCPBytePosn7 "CarConfigExtended BytePos7";
CM_ SG_ 560 VehCfgPrmExtCCPBytePosn8 "CarConfigExtended BytePos8";
CM_ SG_ 325 DrivelineTypInfo "drivelinetype";
CM_ SG_ 325 GearBoxTypToAmplfr "Gear box Type signal, transfer carconfig info to AUD";
CM_ SG_ 325 IntrRoofMtrlToAmplfr "Interior roof material info";
CM_ SG_ 325 PDCMDTCsClr "Boolean type. This signal is a trigger signal to order PDCM cleaning its past DTCs.";
CM_ SG_ 316 AudSpkrNrToAmplfr "Port used to transfer CC audio speaker number info from IVI to AUD";
CM_ SG_ 316 VehTypToAmplfrExt "Vehicle type information";
CM_ SG_ 672 PassSeatSnsrSts2 "Informs if there is a fault on the Passenger seat sensor is detected through electrical measurements, or plausibility judgement. NotOk means sensor is judged as faulty. Di means that the sensor is not configured.";
CM_ SG_ 672 PassSeatSts2 "Describes if an occupant is detected in the passenger seat.";
CM_ SG_ 672 SeatOccptAtRowSecDrSide2 "Describes if an occupant is detected in the  seat.";
CM_ SG_ 672 SeatOccptAtRowSecDrSideSnsSts2 "Informs if there is a fault on the driver seat sensor is detected through electrical measurements, or plausibility judgement. NotOk means sensor is judged as faulty. Di means that the sensor is not configured.";
CM_ SG_ 672 SeatOccptAtRowSecMid2 "Describes if an occupant is detected in the  seat.";
CM_ SG_ 672 SeatOccptAtRowSecMidSnsSts2 "Informs if there is a fault on the driver seat sensor is detected through electrical measurements, or plausibility judgement. NotOk means sensor is judged as faulty. Di means that the sensor is not configured.";
CM_ SG_ 672 SeatOccptAtRowSecPasSide2 "Describes if an occupant is detected in the  seat.";
CM_ SG_ 672 SeatOccptAtRowSecPasSideSnsSts2 "Informs if there is a fault on the driver seat sensor is detected through electrical measurements, or plausibility judgement. NotOk means sensor is judged as faulty. Di means that the sensor is not configured.";
CM_ SG_ 1281 WakeUpReasonsforDHU "WakeUpReasons";
CM_ SG_ 640 InsdLeOfSnsrPrkgAssiRe1 "This is  the detected  barriers distance range from rear inside left USS";
CM_ SG_ 640 InsdRiOfSnsrPrkgAssiRe1 "This is  the detected  barriers distance range from rear inside right USS";
CM_ SG_ 640 ObjOnIfOfSnsr1 "Whether the USS is covered.";
CM_ SG_ 640 OutdLeOfSnsrPrkgAssiRe1 "This is  the detected  barriers distance range from rear outside left USS";
CM_ SG_ 640 OutdRiOfSnsrPrkgAssiRe1 "This is  the detected  barriers distance range from rear outside right USS";
CM_ SG_ 640 PdcMuteBtnSts1 "PDC Mute button status to HMI.";
CM_ SG_ 640 PrkgDstCtrlSts1 "This is the PDC function operation status ";
CM_ SG_ 640 SnsrFltOfPrkgDstCtrl1 "Whether USS is fault.";
CM_ SG_ 528 InsdSnsrDstOfReLeBlk1 "Inside sensor distance of rear left block1";
CM_ SG_ 528 InsdSnsrDstOfReLeBlk2 "Inside sensor distance of rear left block2";
CM_ SG_ 528 InsdSnsrDstOfReRiBlk1 "Inside sensor distance of rear right block1";
CM_ SG_ 528 InsdSnsrDstOfReRiBlk2 "Inside sensor distance of rear right block2";
CM_ SG_ 528 OutdSnsrDstOfReLeBlk1 "Inside sensor distance of rear left block1";
CM_ SG_ 519 AudWarnOfSnsrParkAssiFrnt1 "Front audio warning Req";
CM_ SG_ 519 AudWarnOfSnsrParkAssiRe1 "Rear audio warning Req";
CM_ SG_ 519 OutdSnsrDstOfReLeBlk2 "Inside sensor distance of rear left block2";
CM_ SG_ 519 OutdSnsrDstOfReRiBlk1 "Inside sensor distance of rear left block1";
CM_ SG_ 519 OutdSnsrDstOfReRiBlk2 "Inside sensor distance of rear left block1";
CM_ SG_ 519 PDCMDIDCarMode "Car Mode";
CM_ SG_ 519 PrkgDstCtrlWarn1 "When USS failure or USS cover or PAS failure or PDC inhibit, release the warning sound. ";
CM_ SG_ 592 PDCMDiag1 "DTCs of PDCM1 or PDCM2. (If it is PDCM2).";
CM_ SG_ 593 PDCMDIDEcuCorePartNrByte0 "BCD";
CM_ SG_ 593 PDCMDIDEcuCorePartNrByte1 "BCD";
CM_ SG_ 593 PDCMDIDEcuCorePartNrByte2 "BCD";
CM_ SG_ 593 PDCMDIDEcuCorePartNrByte3 "BCD";
CM_ SG_ 593 PDCMDIDEcuCorePartNrByte4 "Ascii";
CM_ SG_ 593 PDCMDIDEcuCorePartNrByte5 "Ascii";
CM_ SG_ 593 PDCMDIDEcuCorePartNrByte6 "Ascii";
CM_ SG_ 593 PDCMDIDEcuCorePartNrByte7 "(Reserved)";
CM_ SG_ 594 PDCMDIDEcuDeliveryPartNrByte0 "BCD";
CM_ SG_ 594 PDCMDIDEcuDeliveryPartNrByte1 "BCD";
CM_ SG_ 594 PDCMDIDEcuDeliveryPartNrByte2 "BCD";
CM_ SG_ 594 PDCMDIDEcuDeliveryPartNrByte3 "BCD";
CM_ SG_ 594 PDCMDIDEcuDeliveryPartNrByte4 "Ascii";
CM_ SG_ 594 PDCMDIDEcuDeliveryPartNrByte5 "Ascii";
CM_ SG_ 594 PDCMDIDEcuDeliveryPartNrByte6 "Ascii";
CM_ SG_ 594 PDCMDIDEcuDeliveryPartNrByte7 "(Reserved)";
CM_ SG_ 595 PDCMDIDEcuDeliveryPartNrGLByte0 "BCD";
CM_ SG_ 595 PDCMDIDEcuDeliveryPartNrGLByte1 "BCD";
CM_ SG_ 595 PDCMDIDEcuDeliveryPartNrGLByte2 "BCD";
CM_ SG_ 595 PDCMDIDEcuDeliveryPartNrGLByte3 "BCD";
CM_ SG_ 595 PDCMDIDEcuDeliveryPartNrGLByte4 "BCD";
CM_ SG_ 595 PDCMDIDEcuDeliveryPartNrGLByte5 "Ascii";
CM_ SG_ 595 PDCMDIDEcuDeliveryPartNrGLByte6 "Ascii";
CM_ SG_ 595 PDCMDIDEcuDeliveryPartNrGLByte7 "Ascii";
CM_ SG_ 596 PDCMDIDEcuCorePartNrGLByte0 "BCD";
CM_ SG_ 596 PDCMDIDEcuCorePartNrGLByte1 "BCD";
CM_ SG_ 596 PDCMDIDEcuCorePartNrGLByte2 "BCD";
CM_ SG_ 596 PDCMDIDEcuCorePartNrGLByte3 "BCD";
CM_ SG_ 596 PDCMDIDEcuCorePartNrGLByte4 "BCD";
CM_ SG_ 596 PDCMDIDEcuCorePartNrGLByte5 "Ascii";
CM_ SG_ 596 PDCMDIDEcuCorePartNrGLByte6 "Ascii";
CM_ SG_ 596 PDCMDIDEcuCorePartNrGLByte7 "Ascii";
CM_ SG_ 597 PDCMDIDEcuSoftwarePartNrByte0 "BCD";
CM_ SG_ 597 PDCMDIDEcuSoftwarePartNrByte1 "BCD";
CM_ SG_ 597 PDCMDIDEcuSoftwarePartNrByte2 "BCD";
CM_ SG_ 597 PDCMDIDEcuSoftwarePartNrByte3 "BCD";
CM_ SG_ 597 PDCMDIDEcuSoftwarePartNrByte4 "Ascii";
CM_ SG_ 597 PDCMDIDEcuSoftwarePartNrByte5 "Ascii";
CM_ SG_ 597 PDCMDIDEcuSoftwarePartNrByte6 "Ascii";
CM_ SG_ 597 PDCMDIDEcuSoftwarePartNrByte7 "(Reserved)";
CM_ SG_ 598 PDCMDIDEcuSoftwarePartNrGL2Byte0 "BCD";
CM_ SG_ 598 PDCMDIDEcuSoftwarePartNrGL2Byte1 "BCD";
CM_ SG_ 598 PDCMDIDEcuSoftwarePartNrGL2Byte2 "BCD";
CM_ SG_ 598 PDCMDIDEcuSoftwarePartNrGL2Byte3 "BCD";
CM_ SG_ 598 PDCMDIDEcuSoftwarePartNrGL2Byte4 "BCD";
CM_ SG_ 598 PDCMDIDEcuSoftwarePartNrGL2Byte5 "Ascii";
CM_ SG_ 598 PDCMDIDEcuSoftwarePartNrGL2Byte6 "Ascii";
CM_ SG_ 598 PDCMDIDEcuSoftwarePartNrGL2Byte7 "Ascii";
CM_ SG_ 1187 PDCMPartNo10CmplEndSgn1 " First letter of suffix";
CM_ SG_ 1187 PDCMPartNo10CmplEndSgn2 " Second letter of suffix";
CM_ SG_ 1187 PDCMPartNo10CmplEndSgn3 "Third letter of suffix";
CM_ SG_ 1187 PDCMPartNo10CmplNr1 " First two BCD numbers";
CM_ SG_ 1187 PDCMPartNo10CmplNr2 " Second two BCD numbers";
CM_ SG_ 1187 PDCMPartNo10CmplNr3 " Third two BCD numbers";
CM_ SG_ 1187 PDCMPartNo10CmplNr4 " Fourth pair of BCD numbers";
CM_ SG_ 1187 PDCMPartNo10CmplNr5 " Fifth pair of BCD numbers";
CM_ SG_ 1188 PDCMPartNoCmplEndSgn1 " First letter of suffix";
CM_ SG_ 1188 PDCMPartNoCmplEndSgn2 " Second letter of suffix";
CM_ SG_ 1188 PDCMPartNoCmplEndSgn3 "Third letter of suffix";
CM_ SG_ 1188 PDCMPartNoCmplNr1 " First two BCD numbers";
CM_ SG_ 1188 PDCMPartNoCmplNr2 " Second two BCD numbers";
CM_ SG_ 1188 PDCMPartNoCmplNr3 " Third two BCD numbers";
CM_ SG_ 1188 PDCMPartNoCmplNr4 " Fourth pair of BCD numbers";
CM_ SG_ 1189 PDCMSerNoNr1 "Most significant byte of the serial number.";
CM_ SG_ 1189 PDCMSerNoNr2 "Byte 2 of the serial number";
CM_ SG_ 1189 PDCMSerNoNr3 "Byte 3 of the serial number";
CM_ SG_ 1189 PDCMSerNoNr4 "Least significant byte of the serial number";
CM_ SG_ 599 PDCMDIDEcuPwrVcc "ECU power supply Voltage";
CM_ SG_ 599 PDCMDIDEcuSerlNr "Total number of ECU Serial Number";
CM_ SG_ 599 PDCMDIDEcuSoftwarePartNrGL1 "ECU Software Part Numbers";
CM_ SG_ 599 PDCMDIDSnsrVcc "Sensor Supply Voltage";
CM_ SG_ 406 ObstacleMinimumDistanceRe1MinDst "Output minimum distance value. Initial value: 511";
CM_ SG_ 406 ObstacleMinimumDistanceRe1MinDstPosn "Minimum Distance Position to DHU.";
CM_ SG_ 406 ObstacleMinimumDistanceRe1StopDispReq "Stop Display Request. Initial value: 0x0: NotReq";

BA_DEF_  "Baudrate" INT 1000 1000000;
BA_DEF_  "BusType" STRING;
BA_DEF_  "DBName" STRING;
BA_DEF_  "ProtocolType" STRING;
BA_DEF_ BU_ "NmAsrNode" ENUM "No","Yes";
BA_DEF_ BU_ "NmAsrNodeIdentifier" INT 0 255;
BA_DEF_ BO_ "GenMsgCycleTime" INT 0 65536;
BA_DEF_ BO_ "GenMsgDelayTime" INT 0 65536;
BA_DEF_ BO_ "GenMsgSendType" ENUM "cyclic", "spontaneous", "not-used", "not-used", "not-used", "cyclicAndSpontaneous", "not-used", "cyclicIfActive", "NoMsgSendType";
BA_DEF_ BO_ "GenMsgStartDelayTime" INT 0 65536;
BA_DEF_ SG_ "GenSigSendType" ENUM "Cyclic","OnWrite","OnWriteWithRepetition","OnChange","OnChangeWithRepetition","IfActive","IfActiveWithRepetition","NoSigSendType";
BA_DEF_ SG_ "GenSigStartValue" HEX 0 80000000;
BA_DEF_ BO_ "GenMsgILSupport" ENUM "No","Yes";
BA_DEF_ BO_ "NmAsrMessage" ENUM "No","Yes";
BA_DEF_  "NmAsrBaseAddress" HEX 0 536870911;
BA_DEF_  "NmAsrMessageCount" INT 0 255;
BA_DEF_ BU_ "NodeLayerModules" STRING;
BA_DEF_ BU_ "ILused" ENUM "No","Yes";
BA_DEF_ SG_ "GenSigFuncType" ENUM "NoFunction","n/a","n/a","n/a","n/a","n/a","n/a","n/a","n/a","n/a","n/a","n/a","n/a","n/a","n/a","CHK","CNTR","n/a","n/a","n/a","CNTR_AR_01","CRC_AR_01_BOTH","CRC_AR_01_ALT","CRC_AR_01_LOW","CRC_AR_01_NIBBLE","CNTR_AR_04","CRC_AR_04A","CNTR_AR_05","CRC_AR_05";
BA_DEF_ SG_ "GenSigDataID" STRING;

BA_DEF_DEF_ "BusType" "";
BA_DEF_DEF_ "DBName" "";
BA_DEF_DEF_ "ProtocolType" "";
BA_DEF_DEF_ "NmAsrNode" "No";
BA_DEF_DEF_ "NmAsrNodeIdentifier" 0;
BA_DEF_DEF_ "GenSigStartValue" 0;
BA_DEF_DEF_ "GenSigSendType" "NoSigSendType";
BA_DEF_DEF_ "GenMsgCycleTime" 0;
BA_DEF_DEF_ "GenMsgDelayTime" 0;
BA_DEF_DEF_ "GenMsgStartDelayTime" 0;
BA_DEF_DEF_ "GenMsgSendType" "NoMsgSendType";
BA_DEF_DEF_ "GenMsgILSupport" "Yes";
BA_DEF_DEF_ "NmAsrMessage" "No";
BA_DEF_DEF_ "NmAsrBaseAddress" 1280;
BA_DEF_DEF_ "NmAsrMessageCount" 64;
BA_DEF_DEF_ "NodeLayerModules" "CANoeILNLSPA.dll";
BA_DEF_DEF_ "ILused" "Yes";
BA_DEF_DEF_ "GenSigFuncType" "NoFunction";
BA_DEF_DEF_ "GenSigDataID" "";

BA_ "Baudrate" 500000;
BA_ "BusType" "CAN";
BA_ "DBName" "PrivateInfoCAN";
BA_ "ProtocolType" "CAN";

BA_ "NmAsrNode" BU_ AUD 1;
BA_ "NmAsrNodeIdentifier" BU_ AUD 58;
BA_ "NodeLayerModules" BU_ AUD "CANoeILNLSPA.dll,AsrNM33.dll";

BA_ "ILused" BU_ ETC 0;

BA_ "NmAsrNode" BU_ IHU 1;
BA_ "NmAsrNodeIdentifier" BU_ IHU 1;
BA_ "NodeLayerModules" BU_ IHU "CANoeILNLSPA.dll,AsrNM33.dll";

BA_ "NmAsrNode" BU_ PDCM 1;
BA_ "NmAsrNodeIdentifier" BU_ PDCM 61;
BA_ "NodeLayerModules" BU_ PDCM "CANoeILNLSPA.dll,AsrNM33.dll";

BA_ "GenMsgCycleTime" BO_ 896 180.000;
BA_ "GenMsgSendType" BO_ 896 0;

BA_ "GenMsgCycleTime" BO_ 897 180.000;
BA_ "GenMsgSendType" BO_ 897 0;

BA_ "GenMsgCycleTime" BO_ 944 400.000;
BA_ "GenMsgSendType" BO_ 944 0;

BA_ "GenMsgDelayTime" BO_ 912 5.000;
BA_ "GenMsgSendType" BO_ 912 1;

BA_ "GenMsgCycleTime" BO_ 1040 200.000;
BA_ "GenMsgSendType" BO_ 1040 0;

BA_ "GenMsgCycleTime" BO_ 80 200.000;
BA_ "GenMsgSendType" BO_ 80 0;

BA_ "GenMsgCycleTime" BO_ 33 100.000;
BA_ "GenMsgSendType" BO_ 33 0;

BA_ "GenMsgCycleTime" BO_ 949 400.000;
BA_ "GenMsgSendType" BO_ 949 0;

BA_ "GenMsgDelayTime" BO_ 917 150.000;
BA_ "GenMsgSendType" BO_ 917 1;

BA_ "GenMsgCycleTime" BO_ 293 20.000;
BA_ "GenMsgSendType" BO_ 293 0;

BA_ "GenMsgDelayTime" BO_ 1338 20.000;
BA_ "GenMsgSendType" BO_ 1338 1;

BA_ "GenMsgDelayTime" BO_ 1554 5.000;
BA_ "GenMsgSendType" BO_ 1554 1;

BA_ "GenMsgCycleTime" BO_ 820 200.000;
BA_ "GenMsgSendType" BO_ 820 0;

BA_ "GenMsgCycleTime" BO_ 398 100.000;
BA_ "GenMsgSendType" BO_ 398 0;

BA_ "GenMsgDelayTime" BO_ 368 20.000;
BA_ "GenMsgSendType" BO_ 368 1;

BA_ "GenMsgCycleTime" BO_ 379 100.000;
BA_ "GenMsgDelayTime" BO_ 379 10.000;
BA_ "GenMsgSendType" BO_ 379 5;

BA_ "GenMsgCycleTime" BO_ 399 100.000;
BA_ "GenMsgDelayTime" BO_ 399 20.000;
BA_ "GenMsgSendType" BO_ 399 5;

BA_ "GenMsgCycleTime" BO_ 384 30.000;
BA_ "GenMsgSendType" BO_ 384 0;

BA_ "GenMsgCycleTime" BO_ 378 50.000;
BA_ "GenMsgSendType" BO_ 378 0;

BA_ "GenMsgCycleTime" BO_ 517 55.000;
BA_ "GenMsgSendType" BO_ 517 0;

BA_ "GenMsgCycleTime" BO_ 320 40.000;
BA_ "GenMsgSendType" BO_ 320 0;

BA_ "GenMsgCycleTime" BO_ 326 40.000;
BA_ "GenMsgSendType" BO_ 326 0;

BA_ "GenMsgCycleTime" BO_ 352 40.000;
BA_ "GenMsgSendType" BO_ 352 0;

BA_ "GenMsgCycleTime" BO_ 890 500.000;
BA_ "GenMsgSendType" BO_ 890 0;

BA_ "GenMsgCycleTime" BO_ 346 100.000;
BA_ "GenMsgSendType" BO_ 346 0;

BA_ "GenMsgCycleTime" BO_ 353 40.000;
BA_ "GenMsgSendType" BO_ 353 0;

BA_ "GenMsgDelayTime" BO_ 2047 5.000;
BA_ "GenMsgSendType" BO_ 2047 1;

BA_ "GenMsgDelayTime" BO_ 1810 5.000;
BA_ "GenMsgSendType" BO_ 1810 1;

BA_ "GenMsgDelayTime" BO_ 1813 5.000;
BA_ "GenMsgSendType" BO_ 1813 1;

BA_ "GenMsgDelayTime" BO_ 1814 5.000;
BA_ "GenMsgSendType" BO_ 1814 1;

BA_ "GenMsgDelayTime" BO_ 1812 5.000;
BA_ "GenMsgSendType" BO_ 1812 1;

BA_ "GenMsgDelayTime" BO_ 1530 5.000;
BA_ "GenMsgSendType" BO_ 1530 1;

BA_ "GenMsgCycleTime" BO_ 272 20.000;
BA_ "GenMsgSendType" BO_ 272 0;

BA_ "GenMsgCycleTime" BO_ 913 200.000;
BA_ "GenMsgSendType" BO_ 913 0;

BA_ "GenMsgCycleTime" BO_ 336 200.000;
BA_ "GenMsgDelayTime" BO_ 336 20.000;
BA_ "GenMsgSendType" BO_ 336 5;

BA_ "GenMsgCycleTime" BO_ 1041 20.000;
BA_ "GenMsgSendType" BO_ 1041 0;

BA_ "GenMsgCycleTime" BO_ 304 20.000;
BA_ "GenMsgSendType" BO_ 304 0;

BA_ "GenMsgCycleTime" BO_ 914 200.000;
BA_ "GenMsgDelayTime" BO_ 914 20.000;
BA_ "GenMsgSendType" BO_ 914 5;

BA_ "GenMsgCycleTime" BO_ 344 50.000;
BA_ "GenMsgSendType" BO_ 344 0;

BA_ "GenMsgCycleTime" BO_ 849 30.000;
BA_ "GenMsgSendType" BO_ 849 0;

BA_ "GenMsgCycleTime" BO_ 1104 1000.000;
BA_ "GenMsgSendType" BO_ 1104 0;

BA_ "GenMsgCycleTime" BO_ 32 10.000;
BA_ "GenMsgSendType" BO_ 32 0;

BA_ "GenMsgCycleTime" BO_ 7 10.000;
BA_ "GenMsgSendType" BO_ 7 0;

BA_ "GenMsgCycleTime" BO_ 11 10.000;
BA_ "GenMsgSendType" BO_ 11 0;

BA_ "GenMsgCycleTime" BO_ 37 10.000;
BA_ "GenMsgSendType" BO_ 37 0;

BA_ "GenMsgCycleTime" BO_ 41 20.000;
BA_ "GenMsgSendType" BO_ 41 0;

BA_ "GenMsgCycleTime" BO_ 341 70.000;
BA_ "GenMsgSendType" BO_ 341 0;

BA_ "GenMsgCycleTime" BO_ 357 50.000;
BA_ "GenMsgSendType" BO_ 357 0;

BA_ "GenMsgCycleTime" BO_ 314 40.000;
BA_ "GenMsgSendType" BO_ 314 0;

BA_ "GenMsgCycleTime" BO_ 85 15.000;
BA_ "GenMsgSendType" BO_ 85 0;

BA_ "GenMsgCycleTime" BO_ 257 25.000;
BA_ "GenMsgSendType" BO_ 257 0;

BA_ "GenMsgCycleTime" BO_ 362 50.000;
BA_ "GenMsgSendType" BO_ 362 0;

BA_ "GenMsgCycleTime" BO_ 848 350.000;
BA_ "GenMsgDelayTime" BO_ 848 5.000;
BA_ "GenMsgSendType" BO_ 848 5;

BA_ "GenMsgDelayTime" BO_ 613 120.000;
BA_ "GenMsgSendType" BO_ 613 1;

BA_ "GenMsgDelayTime" BO_ 529 120.000;
BA_ "GenMsgSendType" BO_ 529 1;

BA_ "GenMsgDelayTime" BO_ 560 120.000;
BA_ "GenMsgSendType" BO_ 560 1;

BA_ "GenMsgDelayTime" BO_ 325 10.000;
BA_ "GenMsgSendType" BO_ 325 1;

BA_ "GenMsgCycleTime" BO_ 316 120.000;
BA_ "GenMsgSendType" BO_ 316 0;

BA_ "GenMsgCycleTime" BO_ 672 200.000;
BA_ "GenMsgSendType" BO_ 672 0;

BA_ "GenMsgDelayTime" BO_ 1281 20.000;
BA_ "GenMsgSendType" BO_ 1281 1;

BA_ "GenMsgDelayTime" BO_ 1409 5.000;
BA_ "GenMsgSendType" BO_ 1409 1;

BA_ "GenMsgCycleTime" BO_ 640 145.000;
BA_ "GenMsgSendType" BO_ 640 0;

BA_ "GenMsgCycleTime" BO_ 528 70.000;
BA_ "GenMsgSendType" BO_ 528 0;

BA_ "GenMsgCycleTime" BO_ 519 45.000;
BA_ "GenMsgSendType" BO_ 519 0;

BA_ "GenMsgCycleTime" BO_ 592 100.000;
BA_ "GenMsgSendType" BO_ 592 0;

BA_ "GenMsgCycleTime" BO_ 593 100.000;
BA_ "GenMsgSendType" BO_ 593 0;

BA_ "GenMsgCycleTime" BO_ 594 100.000;
BA_ "GenMsgSendType" BO_ 594 0;

BA_ "GenMsgCycleTime" BO_ 595 100.000;
BA_ "GenMsgSendType" BO_ 595 0;

BA_ "GenMsgCycleTime" BO_ 596 100.000;
BA_ "GenMsgSendType" BO_ 596 0;

BA_ "GenMsgCycleTime" BO_ 597 100.000;
BA_ "GenMsgSendType" BO_ 597 0;

BA_ "GenMsgCycleTime" BO_ 598 100.000;
BA_ "GenMsgSendType" BO_ 598 0;

BA_ "GenMsgCycleTime" BO_ 1187 900.000;
BA_ "GenMsgSendType" BO_ 1187 0;

BA_ "GenMsgCycleTime" BO_ 1188 900.000;
BA_ "GenMsgSendType" BO_ 1188 0;

BA_ "GenMsgCycleTime" BO_ 1189 900.000;
BA_ "GenMsgSendType" BO_ 1189 0;

BA_ "GenMsgCycleTime" BO_ 599 100.000;
BA_ "GenMsgSendType" BO_ 599 0;

BA_ "GenMsgCycleTime" BO_ 406 50.000;
BA_ "GenMsgSendType" BO_ 406 0;

BA_ "GenMsgDelayTime" BO_ 1341 20.000;
BA_ "GenMsgSendType" BO_ 1341 1;

BA_ "GenMsgDelayTime" BO_ 1556 5.000;
BA_ "GenMsgSendType" BO_ 1556 1;
BA_ "GenMsgILSupport" BO_ 1338 0;
BA_ "GenMsgILSupport" BO_ 1281 0;
BA_ "GenMsgILSupport" BO_ 1341 0;
BA_ "NmAsrMessage" BO_ 1338 1;
BA_ "NmAsrMessage" BO_ 1281 1;
BA_ "NmAsrMessage" BO_ 1341 1;
BA_ "GenSigSendType" SG_ 379 ANCcfgToAmplfr 1;
BA_ "GenSigSendType" SG_ 37 AccrPedlPsdAccrPedlPsd 0;
BA_ "GenSigDataID" SG_ 37 AccrPedlPsdChks "0x48";
BA_ "GenSigFuncType" SG_ 37 AccrPedlPsdChks 15;
BA_ "GenSigSendType" SG_ 37 AccrPedlPsdChks 0;
BA_ "GenSigStartValue" SG_ 37 AccrPedlPsdChks 255;
BA_ "GenSigFuncType" SG_ 37 AccrPedlPsdCntr 16;
BA_ "GenSigSendType" SG_ 37 AccrPedlPsdCntr 0;
BA_ "GenSigSendType" SG_ 37 AccrPedlPsdSts 0;
BA_ "GenSigSendType" SG_ 11 AccrPedlRatAccrPedlRat 0;
BA_ "GenSigDataID" SG_ 11 AccrPedlRatChks "0x364";
BA_ "GenSigFuncType" SG_ 11 AccrPedlRatChks 15;
BA_ "GenSigSendType" SG_ 11 AccrPedlRatChks 0;
BA_ "GenSigFuncType" SG_ 11 AccrPedlRatCntr 16;
BA_ "GenSigSendType" SG_ 11 AccrPedlRatCntr 0;
BA_ "GenSigSendType" SG_ 848 AcoustEfectPrvtCinePsn 0;
BA_ "GenSigSendType" SG_ 80 AcoustEfectPrvtCinePsnSts 0;
BA_ "GenSigSendType" SG_ 913 AcoustMod 0;
BA_ "GenSigStartValue" SG_ 913 AcoustMod 1;
BA_ "GenSigSendType" SG_ 896 AcoustModSts 0;
BA_ "GenSigSendType" SG_ 914 ActvAudKtvMod 1;
BA_ "GenSigSendType" SG_ 913 ActvtBgrnd 0;
BA_ "GenSigStartValue" SG_ 913 ActvtBgrnd 1;
BA_ "GenSigSendType" SG_ 336 ActvtFgrnd1 0;
BA_ "GenSigSendType" SG_ 272 ActvtFgrnd2 0;
BA_ "GenSigSendType" SG_ 890 AdpvBassEnhmtAdjmtOnOff1 0;
BA_ "GenSigStartValue" SG_ 890 AdpvBassEnhmtAdjmtOnOff1 1;
BA_ "GenSigSendType" SG_ 890 AdpvBassEnhmtAdjmtsurroundlvlAdjmt 0;
BA_ "GenSigStartValue" SG_ 890 AdpvBassEnhmtAdjmtsurroundlvlAdjmt 1;
BA_ "GenSigSendType" SG_ 399 Allmute 1;
BA_ "GenSigStartValue" SG_ 399 Allmute 1;
BA_ "GenSigSendType" SG_ 33 AllmuteSts 1;
BA_ "GenSigSendType" SG_ 32 AmbTIndcdWithUnitAmbTIndcd 0;
BA_ "GenSigStartValue" SG_ 32 AmbTIndcdWithUnitAmbTIndcd 1000;
BA_ "GenSigSendType" SG_ 32 AmbTIndcdWithUnitAmbTIndcdUnit 0;
BA_ "GenSigSendType" SG_ 32 AmbTIndcdWithUnitQF 0;
BA_ "GenSigSendType" SG_ 341 AmbTRawAmbTVal 0;
BA_ "GenSigStartValue" SG_ 341 AmbTRawAmbTVal 700;
BA_ "GenSigSendType" SG_ 341 AmbTRawQly 0;
BA_ "GenSigSendType" SG_ 33 AmplifrErrSts 0;
BA_ "GenSigSendType" SG_ 944 AmplifrOpSts 0;
BA_ "GenSigSendType" SG_ 379 AmplifrTurnOn 1;
BA_ "GenSigSendType" SG_ 379 ArtificialSoundOpenReq 0;
BA_ "GenSigSendType" SG_ 33 ArtificialSoundOpenReqSts 1;
BA_ "GenSigSendType" SG_ 912 ArtificialSoundPreviewSts 1;
BA_ "GenSigSendType" SG_ 379 ArtificialSoundSelectReq 0;
BA_ "GenSigSendType" SG_ 33 ArtificialSoundSelectReqSts 1;
BA_ "GenSigSendType" SG_ 316 AudSpkrNrToAmplfr 1;
BA_ "GenSigSendType" SG_ 917 AudSpkrNrToAmplfrSts 1;
BA_ "GenSigSendType" SG_ 519 AudWarnOfSnsrParkAssiFrnt1 0;
BA_ "GenSigSendType" SG_ 519 AudWarnOfSnsrParkAssiRe1 0;
BA_ "GenSigSendType" SG_ 848 Audio2Mute 1;
BA_ "GenSigSendType" SG_ 917 Audio2MuteSts 1;
BA_ "GenSigSendType" SG_ 336 AudioMute 0;
BA_ "GenSigSendType" SG_ 896 AudioMuteSts 0;
BA_ "GenSigSendType" SG_ 272 Audiomode 0;
BA_ "GenSigSendType" SG_ 336 BalLvl 0;
BA_ "GenSigStartValue" SG_ 336 BalLvl 10;
BA_ "GenSigSendType" SG_ 896 BalLvlSts 0;
BA_ "GenSigSendType" SG_ 914 BdyTypToAmplfr 1;
BA_ "GenSigSendType" SG_ 33 BdyTypToAmplfrSts 1;
BA_ "GenSigSendType" SG_ 80 BgrndForActvtSts 0;
BA_ "GenSigSendType" SG_ 897 BgrndForAudOutChStsAudOutpCh1 0;
BA_ "GenSigSendType" SG_ 897 BgrndForAudOutChStsAudOutpCh10 0;
BA_ "GenSigSendType" SG_ 897 BgrndForAudOutChStsAudOutpCh11 0;
BA_ "GenSigSendType" SG_ 897 BgrndForAudOutChStsAudOutpCh12 0;
BA_ "GenSigSendType" SG_ 897 BgrndForAudOutChStsAudOutpCh2 0;
BA_ "GenSigSendType" SG_ 897 BgrndForAudOutChStsAudOutpCh3 0;
BA_ "GenSigSendType" SG_ 897 BgrndForAudOutChStsAudOutpCh4 0;
BA_ "GenSigSendType" SG_ 897 BgrndForAudOutChStsAudOutpCh5 0;
BA_ "GenSigSendType" SG_ 897 BgrndForAudOutChStsAudOutpCh6 0;
BA_ "GenSigSendType" SG_ 897 BgrndForAudOutChStsAudOutpCh7 0;
BA_ "GenSigSendType" SG_ 897 BgrndForAudOutChStsAudOutpCh8 0;
BA_ "GenSigSendType" SG_ 897 BgrndForAudOutChStsAudOutpCh9 0;
BA_ "GenSigSendType" SG_ 336 BgrndForAudOutpChAudOutpCh1 0;
BA_ "GenSigStartValue" SG_ 336 BgrndForAudOutpChAudOutpCh1 1;
BA_ "GenSigSendType" SG_ 336 BgrndForAudOutpChAudOutpCh10 0;
BA_ "GenSigStartValue" SG_ 336 BgrndForAudOutpChAudOutpCh10 1;
BA_ "GenSigSendType" SG_ 336 BgrndForAudOutpChAudOutpCh11 0;
BA_ "GenSigStartValue" SG_ 336 BgrndForAudOutpChAudOutpCh11 1;
BA_ "GenSigSendType" SG_ 336 BgrndForAudOutpChAudOutpCh12 0;
BA_ "GenSigStartValue" SG_ 336 BgrndForAudOutpChAudOutpCh12 1;
BA_ "GenSigSendType" SG_ 336 BgrndForAudOutpChAudOutpCh2 0;
BA_ "GenSigStartValue" SG_ 336 BgrndForAudOutpChAudOutpCh2 1;
BA_ "GenSigSendType" SG_ 336 BgrndForAudOutpChAudOutpCh3 0;
BA_ "GenSigStartValue" SG_ 336 BgrndForAudOutpChAudOutpCh3 1;
BA_ "GenSigSendType" SG_ 336 BgrndForAudOutpChAudOutpCh4 0;
BA_ "GenSigStartValue" SG_ 336 BgrndForAudOutpChAudOutpCh4 1;
BA_ "GenSigSendType" SG_ 336 BgrndForAudOutpChAudOutpCh5 0;
BA_ "GenSigStartValue" SG_ 336 BgrndForAudOutpChAudOutpCh5 1;
BA_ "GenSigSendType" SG_ 336 BgrndForAudOutpChAudOutpCh6 0;
BA_ "GenSigStartValue" SG_ 336 BgrndForAudOutpChAudOutpCh6 1;
BA_ "GenSigSendType" SG_ 336 BgrndForAudOutpChAudOutpCh7 0;
BA_ "GenSigStartValue" SG_ 336 BgrndForAudOutpChAudOutpCh7 1;
BA_ "GenSigSendType" SG_ 336 BgrndForAudOutpChAudOutpCh8 0;
BA_ "GenSigStartValue" SG_ 336 BgrndForAudOutpChAudOutpCh8 1;
BA_ "GenSigSendType" SG_ 336 BgrndForAudOutpChAudOutpCh9 0;
BA_ "GenSigStartValue" SG_ 336 BgrndForAudOutpChAudOutpCh9 1;
BA_ "GenSigSendType" SG_ 944 BgrndForVolLvlSts 0;
BA_ "GenSigSendType" SG_ 1104 BkpOfDstTrvld 0;
BA_ "GenSigSendType" SG_ 257 BrkPedlPsdBrkPedlNotPsdSafe 0;
BA_ "GenSigSendType" SG_ 257 BrkPedlPsdBrkPedlPsd 0;
BA_ "GenSigDataID" SG_ 257 BrkPedlPsdChks "0x38";
BA_ "GenSigFuncType" SG_ 257 BrkPedlPsdChks 15;
BA_ "GenSigSendType" SG_ 257 BrkPedlPsdChks 0;
BA_ "GenSigFuncType" SG_ 257 BrkPedlPsdCntr 16;
BA_ "GenSigSendType" SG_ 257 BrkPedlPsdCntr 0;
BA_ "GenSigSendType" SG_ 257 BrkPedlPsdQf 0;
BA_ "GenSigSendType" SG_ 398 BrkPedlrRatPerc 0;
BA_ "GenSigSendType" SG_ 398 BrkPedlrRatQf 0;
BA_ "GenSigSendType" SG_ 1104 CarTiGlb 0;
BA_ "GenSigSendType" SG_ 399 Chiming1Mute 1;
BA_ "GenSigSendType" SG_ 912 Chiming1MuteSts 1;
BA_ "GenSigSendType" SG_ 399 Chiming2Mute 1;
BA_ "GenSigSendType" SG_ 912 Chiming2MuteSts 1;
BA_ "GenSigSendType" SG_ 399 Chiming3Mute 1;
BA_ "GenSigSendType" SG_ 912 Chiming3MuteSts 1;
BA_ "GenSigSendType" SG_ 399 Chiming4Mute 1;
BA_ "GenSigSendType" SG_ 912 Chiming4MuteSts 1;
BA_ "GenSigSendType" SG_ 314 CmptmtTFrntCmptmtTFrnt 0;
BA_ "GenSigStartValue" SG_ 314 CmptmtTFrntCmptmtTFrnt 600;
BA_ "GenSigSendType" SG_ 314 CmptmtTFrntFanForCmptmtTRunng 0;
BA_ "GenSigSendType" SG_ 314 CmptmtTFrntQf 0;
BA_ "GenSigStartValue" SG_ 314 CmptmtTFrntQf 1;
BA_ "GenSigSendType" SG_ 368 CptAdvExtSwt 1;
BA_ "GenSigStartValue" SG_ 368 CptAdvExtSwt 1;
BA_ "GenSigSendType" SG_ 80 CptAdvExtSwtSts 0;
BA_ "GenSigStartValue" SG_ 80 CptAdvExtSwtSts 1;
BA_ "GenSigDataID" SG_ 848 CrashStsSafeChks "0x40B";
BA_ "GenSigFuncType" SG_ 848 CrashStsSafeChks 15;
BA_ "GenSigSendType" SG_ 848 CrashStsSafeChks 1;
BA_ "GenSigStartValue" SG_ 848 CrashStsSafeChks 255;
BA_ "GenSigFuncType" SG_ 848 CrashStsSafeCntr 16;
BA_ "GenSigSendType" SG_ 848 CrashStsSafeCntr 1;
BA_ "GenSigSendType" SG_ 848 CrashStsSafeSts 1;
BA_ "GenSigSendType" SG_ 944 DiagState1 0;
BA_ "GenSigSendType" SG_ 944 DiagState2 0;
BA_ "GenSigSendType" SG_ 314 DoorDrvrHndlSts 0;
BA_ "GenSigSendType" SG_ 41 DoorDrvrSts 0;
BA_ "GenSigSendType" SG_ 314 DoorLeReHndlSts 0;
BA_ "GenSigSendType" SG_ 41 DoorLeReSts 0;
BA_ "GenSigSendType" SG_ 344 DoorPassHndlSts 0;
BA_ "GenSigSendType" SG_ 41 DoorPassSts 0;
BA_ "GenSigSendType" SG_ 314 DoorRiReHndlSts 0;
BA_ "GenSigSendType" SG_ 41 DoorRiReSts 0;
BA_ "GenSigSendType" SG_ 325 DrivelineTypInfo 1;
BA_ "GenSigStartValue" SG_ 325 DrivelineTypInfo 1;
BA_ "GenSigSendType" SG_ 344 DrvModReq 0;
BA_ "GenSigSendType" SG_ 913 DrvrSeatSnsrSts 0;
BA_ "GenSigSendType" SG_ 913 DrvrSeatSts 0;
BA_ "GenSigStartValue" SG_ 913 DrvrSeatSts 1;
BA_ "GenSigDataID" SG_ 849 EngSt1WdStsChks "0x89";
BA_ "GenSigFuncType" SG_ 849 EngSt1WdStsChks 15;
BA_ "GenSigSendType" SG_ 849 EngSt1WdStsChks 0;
BA_ "GenSigFuncType" SG_ 849 EngSt1WdStsCntr 16;
BA_ "GenSigSendType" SG_ 849 EngSt1WdStsCntr 0;
BA_ "GenSigSendType" SG_ 849 EngSt1WdStsEngSt1WdSts 0;
BA_ "GenSigSendType" SG_ 914 EngTypToAmplfr 1;
BA_ "GenSigSendType" SG_ 33 EngTypToAmplfrSts 1;
BA_ "GenSigSendType" SG_ 820 ExtrLtgStsAFS 0;
BA_ "GenSigSendType" SG_ 820 ExtrLtgStsAHBC 0;
BA_ "GenSigSendType" SG_ 820 ExtrLtgStsAHL 0;
BA_ "GenSigSendType" SG_ 820 ExtrLtgStsAllWL 0;
BA_ "GenSigSendType" SG_ 820 ExtrLtgStsApproach 0;
BA_ "GenSigDataID" SG_ 820 ExtrLtgStsChks "0x44C";
BA_ "GenSigFuncType" SG_ 820 ExtrLtgStsChks 15;
BA_ "GenSigSendType" SG_ 820 ExtrLtgStsChks 0;
BA_ "GenSigFuncType" SG_ 820 ExtrLtgStsCntr 16;
BA_ "GenSigSendType" SG_ 820 ExtrLtgStsCntr 0;
BA_ "GenSigSendType" SG_ 820 ExtrLtgStsCornrgLi 0;
BA_ "GenSigSendType" SG_ 820 ExtrLtgStsDBL 0;
BA_ "GenSigSendType" SG_ 820 ExtrLtgStsDRL 0;
BA_ "GenSigSendType" SG_ 820 ExtrLtgStsFlash 0;
BA_ "GenSigSendType" SG_ 820 ExtrLtgStsFrntFog 0;
BA_ "GenSigSendType" SG_ 820 ExtrLtgStsGoodbye 0;
BA_ "GenSigSendType" SG_ 820 ExtrLtgStsHWL 0;
BA_ "GenSigSendType" SG_ 820 ExtrLtgStsHiBeam 0;
BA_ "GenSigSendType" SG_ 820 ExtrLtgStsHomeSafe 0;
BA_ "GenSigSendType" SG_ 820 ExtrLtgStsLoBeam 0;
BA_ "GenSigSendType" SG_ 820 ExtrLtgStsLtgShow 0;
BA_ "GenSigSendType" SG_ 820 ExtrLtgStsPosLiFrnt 0;
BA_ "GenSigSendType" SG_ 820 ExtrLtgStsPosLiRe 0;
BA_ "GenSigSendType" SG_ 820 ExtrLtgStsReFog 0;
BA_ "GenSigSendType" SG_ 820 ExtrLtgStsReverseLi 0;
BA_ "GenSigSendType" SG_ 820 ExtrLtgStsStopLi 0;
BA_ "GenSigSendType" SG_ 820 ExtrLtgStsTurnIndrLe 0;
BA_ "GenSigSendType" SG_ 820 ExtrLtgStsTurnIndrRi 0;
BA_ "GenSigSendType" SG_ 820 ExtrLtgStsWelcome 0;
BA_ "GenSigSendType" SG_ 913 FaderLvl 0;
BA_ "GenSigStartValue" SG_ 913 FaderLvl 10;
BA_ "GenSigSendType" SG_ 896 FaderLvlSts 0;
BA_ "GenSigSendType" SG_ 913 Feedback1Select 0;
BA_ "GenSigSendType" SG_ 80 Feedback1SelectSts 0;
BA_ "GenSigSendType" SG_ 913 Feedback2Select 0;
BA_ "GenSigSendType" SG_ 80 Feedback2SelectSts 0;
BA_ "GenSigSendType" SG_ 304 Fgrnd1ForAudOutpChAudOutpCh1 0;
BA_ "GenSigSendType" SG_ 304 Fgrnd1ForAudOutpChAudOutpCh10 0;
BA_ "GenSigSendType" SG_ 304 Fgrnd1ForAudOutpChAudOutpCh11 0;
BA_ "GenSigSendType" SG_ 304 Fgrnd1ForAudOutpChAudOutpCh12 0;
BA_ "GenSigSendType" SG_ 304 Fgrnd1ForAudOutpChAudOutpCh2 0;
BA_ "GenSigSendType" SG_ 304 Fgrnd1ForAudOutpChAudOutpCh3 0;
BA_ "GenSigSendType" SG_ 304 Fgrnd1ForAudOutpChAudOutpCh4 0;
BA_ "GenSigSendType" SG_ 304 Fgrnd1ForAudOutpChAudOutpCh5 0;
BA_ "GenSigSendType" SG_ 304 Fgrnd1ForAudOutpChAudOutpCh6 0;
BA_ "GenSigSendType" SG_ 304 Fgrnd1ForAudOutpChAudOutpCh7 0;
BA_ "GenSigSendType" SG_ 304 Fgrnd1ForAudOutpChAudOutpCh8 0;
BA_ "GenSigSendType" SG_ 304 Fgrnd1ForAudOutpChAudOutpCh9 0;
BA_ "GenSigSendType" SG_ 896 Fgrnd1stForActvtSts 0;
BA_ "GenSigSendType" SG_ 897 Fgrnd1stForAudOutpChStsAudOutpCh1 0;
BA_ "GenSigSendType" SG_ 897 Fgrnd1stForAudOutpChStsAudOutpCh10 0;
BA_ "GenSigSendType" SG_ 897 Fgrnd1stForAudOutpChStsAudOutpCh11 0;
BA_ "GenSigSendType" SG_ 897 Fgrnd1stForAudOutpChStsAudOutpCh12 0;
BA_ "GenSigSendType" SG_ 897 Fgrnd1stForAudOutpChStsAudOutpCh2 0;
BA_ "GenSigSendType" SG_ 897 Fgrnd1stForAudOutpChStsAudOutpCh3 0;
BA_ "GenSigSendType" SG_ 897 Fgrnd1stForAudOutpChStsAudOutpCh4 0;
BA_ "GenSigSendType" SG_ 897 Fgrnd1stForAudOutpChStsAudOutpCh5 0;
BA_ "GenSigSendType" SG_ 897 Fgrnd1stForAudOutpChStsAudOutpCh6 0;
BA_ "GenSigSendType" SG_ 897 Fgrnd1stForAudOutpChStsAudOutpCh7 0;
BA_ "GenSigSendType" SG_ 897 Fgrnd1stForAudOutpChStsAudOutpCh8 0;
BA_ "GenSigSendType" SG_ 897 Fgrnd1stForAudOutpChStsAudOutpCh9 0;
BA_ "GenSigSendType" SG_ 897 Fgrnd1stForVolLvlSts 0;
BA_ "GenSigSendType" SG_ 272 Fgrnd2ForAudOutpChAudOutpCh1 0;
BA_ "GenSigSendType" SG_ 272 Fgrnd2ForAudOutpChAudOutpCh10 0;
BA_ "GenSigSendType" SG_ 272 Fgrnd2ForAudOutpChAudOutpCh11 0;
BA_ "GenSigSendType" SG_ 272 Fgrnd2ForAudOutpChAudOutpCh12 0;
BA_ "GenSigSendType" SG_ 272 Fgrnd2ForAudOutpChAudOutpCh2 0;
BA_ "GenSigSendType" SG_ 272 Fgrnd2ForAudOutpChAudOutpCh3 0;
BA_ "GenSigSendType" SG_ 272 Fgrnd2ForAudOutpChAudOutpCh4 0;
BA_ "GenSigSendType" SG_ 272 Fgrnd2ForAudOutpChAudOutpCh5 0;
BA_ "GenSigSendType" SG_ 272 Fgrnd2ForAudOutpChAudOutpCh6 0;
BA_ "GenSigSendType" SG_ 272 Fgrnd2ForAudOutpChAudOutpCh7 0;
BA_ "GenSigSendType" SG_ 272 Fgrnd2ForAudOutpChAudOutpCh8 0;
BA_ "GenSigSendType" SG_ 272 Fgrnd2ForAudOutpChAudOutpCh9 0;
BA_ "GenSigSendType" SG_ 896 Fgrnd2ndForActvtSts 0;
BA_ "GenSigSendType" SG_ 897 Fgrnd2ndForAudOutpChStsAudOutpCh1 0;
BA_ "GenSigSendType" SG_ 897 Fgrnd2ndForAudOutpChStsAudOutpCh10 0;
BA_ "GenSigSendType" SG_ 897 Fgrnd2ndForAudOutpChStsAudOutpCh11 0;
BA_ "GenSigSendType" SG_ 897 Fgrnd2ndForAudOutpChStsAudOutpCh12 0;
BA_ "GenSigSendType" SG_ 897 Fgrnd2ndForAudOutpChStsAudOutpCh2 0;
BA_ "GenSigSendType" SG_ 897 Fgrnd2ndForAudOutpChStsAudOutpCh3 0;
BA_ "GenSigSendType" SG_ 897 Fgrnd2ndForAudOutpChStsAudOutpCh4 0;
BA_ "GenSigSendType" SG_ 897 Fgrnd2ndForAudOutpChStsAudOutpCh5 0;
BA_ "GenSigSendType" SG_ 897 Fgrnd2ndForAudOutpChStsAudOutpCh6 0;
BA_ "GenSigSendType" SG_ 897 Fgrnd2ndForAudOutpChStsAudOutpCh7 0;
BA_ "GenSigSendType" SG_ 897 Fgrnd2ndForAudOutpChStsAudOutpCh8 0;
BA_ "GenSigSendType" SG_ 897 Fgrnd2ndForAudOutpChStsAudOutpCh9 0;
BA_ "GenSigSendType" SG_ 897 Fgrnd2ndForVolLvlSts 0;
BA_ "GenSigSendType" SG_ 325 GearBoxTypToAmplfr 1;
BA_ "GenSigSendType" SG_ 912 GearBoxTypToAmplfrSts 1;
BA_ "GenSigSendType" SG_ 11 GearLvrIndcn 0;
BA_ "GenSigStartValue" SG_ 11 GearLvrIndcn 7;
BA_ "GenSigSendType" SG_ 326 HdrestMod 0;
BA_ "GenSigSendType" SG_ 37 HoodSts 0;
BA_ "GenSigSendType" SG_ 346 IndcnUnitClkFmt 0;
BA_ "GenSigSendType" SG_ 346 IndcnUnitDateFmt 0;
BA_ "GenSigSendType" SG_ 346 IndcnUnitDstLong 0;
BA_ "GenSigSendType" SG_ 346 IndcnUnitDstSho 0;
BA_ "GenSigSendType" SG_ 346 IndcnUnitFuCnsUnit 0;
BA_ "GenSigSendType" SG_ 346 IndcnUnitPUnit 0;
BA_ "GenSigSendType" SG_ 346 IndcnUnitSpdUnit 0;
BA_ "GenSigSendType" SG_ 346 IndcnUnitTUnit 0;
BA_ "GenSigSendType" SG_ 346 IndcnUnitVolUnit 0;
BA_ "GenSigSendType" SG_ 640 InsdLeOfSnsrPrkgAssiRe1 0;
BA_ "GenSigSendType" SG_ 640 InsdRiOfSnsrPrkgAssiRe1 0;
BA_ "GenSigSendType" SG_ 528 InsdSnsrDstOfReLeBlk1 0;
BA_ "GenSigStartValue" SG_ 528 InsdSnsrDstOfReLeBlk1 511;
BA_ "GenSigSendType" SG_ 528 InsdSnsrDstOfReLeBlk2 0;
BA_ "GenSigStartValue" SG_ 528 InsdSnsrDstOfReLeBlk2 511;
BA_ "GenSigSendType" SG_ 528 InsdSnsrDstOfReRiBlk1 0;
BA_ "GenSigStartValue" SG_ 528 InsdSnsrDstOfReRiBlk1 511;
BA_ "GenSigSendType" SG_ 528 InsdSnsrDstOfReRiBlk2 0;
BA_ "GenSigStartValue" SG_ 528 InsdSnsrDstOfReRiBlk2 511;
BA_ "GenSigSendType" SG_ 325 IntrRoofMtrlToAmplfr 1;
BA_ "GenSigSendType" SG_ 917 IntrRoofMtrlToAmplfrSts 1;
BA_ "GenSigSendType" SG_ 341 IsgIDc 0;
BA_ "GenSigStartValue" SG_ 341 IsgIDc 8188;
BA_ "GenSigSendType" SG_ 11 IsgSpdActSgn 0;
BA_ "GenSigDataID" SG_ 7 IsgTqActChks "0x46";
BA_ "GenSigFuncType" SG_ 7 IsgTqActChks 15;
BA_ "GenSigSendType" SG_ 7 IsgTqActChks 0;
BA_ "GenSigFuncType" SG_ 7 IsgTqActCntr 16;
BA_ "GenSigSendType" SG_ 7 IsgTqActCntr 0;
BA_ "GenSigSendType" SG_ 7 IsgTqActIsgTqAct 0;
BA_ "GenSigStartValue" SG_ 7 IsgTqActIsgTqAct 8188;
BA_ "GenSigSendType" SG_ 7 IsgTqActQualityFactor 0;
BA_ "GenSigStartValue" SG_ 7 IsgTqActQualityFactor 1;
BA_ "GenSigSendType" SG_ 341 IsgTqReq 0;
BA_ "GenSigStartValue" SG_ 341 IsgTqReq 8188;
BA_ "GenSigSendType" SG_ 341 IsgUDc 0;
BA_ "GenSigSendType" SG_ 917 LndBtnSts 1;
BA_ "GenSigStartValue" SG_ 917 LndBtnSts 1;
BA_ "GenSigSendType" SG_ 326 LockgCenStsLockSt 0;
BA_ "GenSigSendType" SG_ 326 LockgCenStsTrigSrc 0;
BA_ "GenSigSendType" SG_ 326 LockgCenStsUpdEve 0;
BA_ "GenSigSendType" SG_ 913 LvlOfBass 0;
BA_ "GenSigStartValue" SG_ 913 LvlOfBass 10;
BA_ "GenSigSendType" SG_ 896 LvlOfBassSts 0;
BA_ "GenSigSendType" SG_ 913 LvlOfMid 0;
BA_ "GenSigStartValue" SG_ 913 LvlOfMid 10;
BA_ "GenSigSendType" SG_ 896 LvlOfMidSts 0;
BA_ "GenSigSendType" SG_ 913 LvlOfTreble 0;
BA_ "GenSigStartValue" SG_ 913 LvlOfTreble 10;
BA_ "GenSigSendType" SG_ 896 LvlOfTrebleSts 0;
BA_ "GenSigSendType" SG_ 352 LvlOfpoint1 0;
BA_ "GenSigSendType" SG_ 320 LvlOfpoint2 0;
BA_ "GenSigSendType" SG_ 326 LvlOfpoint3 0;
BA_ "GenSigSendType" SG_ 352 LvlOfpoint4 0;
BA_ "GenSigSendType" SG_ 320 LvlOfpoint5 0;
BA_ "GenSigSendType" SG_ 849 LvlOfpoint6 0;
BA_ "GenSigSendType" SG_ 353 MediaSouce 0;
BA_ "GenSigSendType" SG_ 32 MmedAudCurrLim 0;
BA_ "GenSigSendType" SG_ 344 MmedAudPwrMod 0;
BA_ "GenSigSendType" SG_ 384 MonrSysSts1 0;
BA_ "GenSigSendType" SG_ 399 NaviMute 1;
BA_ "GenSigSendType" SG_ 33 NaviMuteSts 1;
BA_ "GenSigSendType" SG_ 304 NotifForEmgyCall 0;
BA_ "GenSigSendType" SG_ 640 ObjOnIfOfSnsr1 0;
BA_ "GenSigSendType" SG_ 406 ObstacleMinimumDistanceRe1MinDst 0;
BA_ "GenSigStartValue" SG_ 406 ObstacleMinimumDistanceRe1MinDst 511;
BA_ "GenSigSendType" SG_ 406 ObstacleMinimumDistanceRe1MinDstPosn 0;
BA_ "GenSigSendType" SG_ 406 ObstacleMinimumDistanceRe1StopDispReq 0;
BA_ "GenSigSendType" SG_ 944 OutChState1 0;
BA_ "GenSigSendType" SG_ 944 OutChState2 0;
BA_ "GenSigSendType" SG_ 949 OutChState3 0;
BA_ "GenSigSendType" SG_ 949 OutChState4 0;
BA_ "GenSigSendType" SG_ 640 OutdLeOfSnsrPrkgAssiRe1 0;
BA_ "GenSigSendType" SG_ 640 OutdRiOfSnsrPrkgAssiRe1 0;
BA_ "GenSigSendType" SG_ 528 OutdSnsrDstOfReLeBlk1 0;
BA_ "GenSigStartValue" SG_ 528 OutdSnsrDstOfReLeBlk1 511;
BA_ "GenSigSendType" SG_ 519 OutdSnsrDstOfReLeBlk2 0;
BA_ "GenSigStartValue" SG_ 519 OutdSnsrDstOfReLeBlk2 511;
BA_ "GenSigSendType" SG_ 519 OutdSnsrDstOfReRiBlk1 0;
BA_ "GenSigStartValue" SG_ 519 OutdSnsrDstOfReRiBlk1 511;
BA_ "GenSigSendType" SG_ 519 OutdSnsrDstOfReRiBlk2 0;
BA_ "GenSigStartValue" SG_ 519 OutdSnsrDstOfReRiBlk2 511;
BA_ "GenSigSendType" SG_ 519 PDCMDIDCarMode 0;
BA_ "GenSigSendType" SG_ 593 PDCMDIDEcuCorePartNrByte0 0;
BA_ "GenSigSendType" SG_ 593 PDCMDIDEcuCorePartNrByte1 0;
BA_ "GenSigSendType" SG_ 593 PDCMDIDEcuCorePartNrByte2 0;
BA_ "GenSigSendType" SG_ 593 PDCMDIDEcuCorePartNrByte3 0;
BA_ "GenSigSendType" SG_ 593 PDCMDIDEcuCorePartNrByte4 0;
BA_ "GenSigSendType" SG_ 593 PDCMDIDEcuCorePartNrByte5 0;
BA_ "GenSigSendType" SG_ 593 PDCMDIDEcuCorePartNrByte6 0;
BA_ "GenSigSendType" SG_ 593 PDCMDIDEcuCorePartNrByte7 0;
BA_ "GenSigSendType" SG_ 596 PDCMDIDEcuCorePartNrGLByte0 0;
BA_ "GenSigSendType" SG_ 596 PDCMDIDEcuCorePartNrGLByte1 0;
BA_ "GenSigSendType" SG_ 596 PDCMDIDEcuCorePartNrGLByte2 0;
BA_ "GenSigSendType" SG_ 596 PDCMDIDEcuCorePartNrGLByte3 0;
BA_ "GenSigSendType" SG_ 596 PDCMDIDEcuCorePartNrGLByte4 0;
BA_ "GenSigSendType" SG_ 596 PDCMDIDEcuCorePartNrGLByte5 0;
BA_ "GenSigSendType" SG_ 596 PDCMDIDEcuCorePartNrGLByte6 0;
BA_ "GenSigSendType" SG_ 596 PDCMDIDEcuCorePartNrGLByte7 0;
BA_ "GenSigSendType" SG_ 594 PDCMDIDEcuDeliveryPartNrByte0 0;
BA_ "GenSigSendType" SG_ 594 PDCMDIDEcuDeliveryPartNrByte1 0;
BA_ "GenSigSendType" SG_ 594 PDCMDIDEcuDeliveryPartNrByte2 0;
BA_ "GenSigSendType" SG_ 594 PDCMDIDEcuDeliveryPartNrByte3 0;
BA_ "GenSigSendType" SG_ 594 PDCMDIDEcuDeliveryPartNrByte4 0;
BA_ "GenSigSendType" SG_ 594 PDCMDIDEcuDeliveryPartNrByte5 0;
BA_ "GenSigSendType" SG_ 594 PDCMDIDEcuDeliveryPartNrByte6 0;
BA_ "GenSigSendType" SG_ 594 PDCMDIDEcuDeliveryPartNrByte7 0;
BA_ "GenSigSendType" SG_ 595 PDCMDIDEcuDeliveryPartNrGLByte0 0;
BA_ "GenSigSendType" SG_ 595 PDCMDIDEcuDeliveryPartNrGLByte1 0;
BA_ "GenSigSendType" SG_ 595 PDCMDIDEcuDeliveryPartNrGLByte2 0;
BA_ "GenSigSendType" SG_ 595 PDCMDIDEcuDeliveryPartNrGLByte3 0;
BA_ "GenSigSendType" SG_ 595 PDCMDIDEcuDeliveryPartNrGLByte4 0;
BA_ "GenSigSendType" SG_ 595 PDCMDIDEcuDeliveryPartNrGLByte5 0;
BA_ "GenSigSendType" SG_ 595 PDCMDIDEcuDeliveryPartNrGLByte6 0;
BA_ "GenSigSendType" SG_ 595 PDCMDIDEcuDeliveryPartNrGLByte7 0;
BA_ "GenSigSendType" SG_ 599 PDCMDIDEcuPwrVcc 0;
BA_ "GenSigSendType" SG_ 599 PDCMDIDEcuSerlNr 0;
BA_ "GenSigSendType" SG_ 597 PDCMDIDEcuSoftwarePartNrByte0 0;
BA_ "GenSigSendType" SG_ 597 PDCMDIDEcuSoftwarePartNrByte1 0;
BA_ "GenSigSendType" SG_ 597 PDCMDIDEcuSoftwarePartNrByte2 0;
BA_ "GenSigSendType" SG_ 597 PDCMDIDEcuSoftwarePartNrByte3 0;
BA_ "GenSigSendType" SG_ 597 PDCMDIDEcuSoftwarePartNrByte4 0;
BA_ "GenSigSendType" SG_ 597 PDCMDIDEcuSoftwarePartNrByte5 0;
BA_ "GenSigSendType" SG_ 597 PDCMDIDEcuSoftwarePartNrByte6 0;
BA_ "GenSigSendType" SG_ 597 PDCMDIDEcuSoftwarePartNrByte7 0;
BA_ "GenSigSendType" SG_ 599 PDCMDIDEcuSoftwarePartNrGL1 0;
BA_ "GenSigSendType" SG_ 598 PDCMDIDEcuSoftwarePartNrGL2Byte0 0;
BA_ "GenSigSendType" SG_ 598 PDCMDIDEcuSoftwarePartNrGL2Byte1 0;
BA_ "GenSigSendType" SG_ 598 PDCMDIDEcuSoftwarePartNrGL2Byte2 0;
BA_ "GenSigSendType" SG_ 598 PDCMDIDEcuSoftwarePartNrGL2Byte3 0;
BA_ "GenSigSendType" SG_ 598 PDCMDIDEcuSoftwarePartNrGL2Byte4 0;
BA_ "GenSigSendType" SG_ 598 PDCMDIDEcuSoftwarePartNrGL2Byte5 0;
BA_ "GenSigSendType" SG_ 598 PDCMDIDEcuSoftwarePartNrGL2Byte6 0;
BA_ "GenSigSendType" SG_ 598 PDCMDIDEcuSoftwarePartNrGL2Byte7 0;
BA_ "GenSigSendType" SG_ 599 PDCMDIDSnsrVcc 0;
BA_ "GenSigSendType" SG_ 325 PDCMDTCsClr 1;
BA_ "GenSigSendType" SG_ 592 PDCMDiag1 0;
BA_ "GenSigSendType" SG_ 1187 PDCMPartNo10CmplEndSgn1 0;
BA_ "GenSigSendType" SG_ 1187 PDCMPartNo10CmplEndSgn2 0;
BA_ "GenSigSendType" SG_ 1187 PDCMPartNo10CmplEndSgn3 0;
BA_ "GenSigSendType" SG_ 1187 PDCMPartNo10CmplNr1 0;
BA_ "GenSigSendType" SG_ 1187 PDCMPartNo10CmplNr2 0;
BA_ "GenSigSendType" SG_ 1187 PDCMPartNo10CmplNr3 0;
BA_ "GenSigSendType" SG_ 1187 PDCMPartNo10CmplNr4 0;
BA_ "GenSigSendType" SG_ 1187 PDCMPartNo10CmplNr5 0;
BA_ "GenSigSendType" SG_ 1188 PDCMPartNoCmplEndSgn1 0;
BA_ "GenSigSendType" SG_ 1188 PDCMPartNoCmplEndSgn2 0;
BA_ "GenSigSendType" SG_ 1188 PDCMPartNoCmplEndSgn3 0;
BA_ "GenSigSendType" SG_ 1188 PDCMPartNoCmplNr1 0;
BA_ "GenSigSendType" SG_ 1188 PDCMPartNoCmplNr2 0;
BA_ "GenSigSendType" SG_ 1188 PDCMPartNoCmplNr3 0;
BA_ "GenSigSendType" SG_ 1188 PDCMPartNoCmplNr4 0;
BA_ "GenSigSendType" SG_ 1189 PDCMSerNoNr1 0;
BA_ "GenSigSendType" SG_ 1189 PDCMSerNoNr2 0;
BA_ "GenSigSendType" SG_ 1189 PDCMSerNoNr3 0;
BA_ "GenSigSendType" SG_ 1189 PDCMSerNoNr4 0;
BA_ "GenSigSendType" SG_ 353 PSDConnectBTHeadSetSts 0;
BA_ "GenSigSendType" SG_ 353 PassHdrestSwt 0;
BA_ "GenSigStartValue" SG_ 353 PassHdrestSwt 2;
BA_ "GenSigSendType" SG_ 672 PassSeatSnsrSts2 0;
BA_ "GenSigSendType" SG_ 672 PassSeatSts2 0;
BA_ "GenSigStartValue" SG_ 672 PassSeatSts2 1;
BA_ "GenSigSendType" SG_ 378 PdcLoMuteBtnReq 1;
BA_ "GenSigSendType" SG_ 640 PdcMuteBtnSts1 0;
BA_ "GenSigSendType" SG_ 517 PrkgAssiReSts 0;
BA_ "GenSigSendType" SG_ 378 PrkgDstCtrlLoSysSwt 0;
BA_ "GenSigSendType" SG_ 640 PrkgDstCtrlSts1 0;
BA_ "GenSigSendType" SG_ 519 PrkgDstCtrlWarn1 0;
BA_ "GenSigSendType" SG_ 362 ProfPenSts1 0;
BA_ "GenSigSendType" SG_ 378 PrpsnTypToAmplfr 1;
BA_ "GenSigStartValue" SG_ 378 PrpsnTypToAmplfr 1;
BA_ "GenSigSendType" SG_ 33 PrpsnTypToAmplfrSts 1;
BA_ "GenSigStartValue" SG_ 33 PrpsnTypToAmplfrSts 1;
BA_ "GenSigSendType" SG_ 353 PtDrvrSetg 0;
BA_ "GenSigSendType" SG_ 7 PtGearAct 0;
BA_ "GenSigDataID" SG_ 357 PtTqSetSafeChks "0x374";
BA_ "GenSigFuncType" SG_ 357 PtTqSetSafeChks 15;
BA_ "GenSigSendType" SG_ 357 PtTqSetSafeChks 0;
BA_ "GenSigFuncType" SG_ 357 PtTqSetSafeCntr 16;
BA_ "GenSigSendType" SG_ 357 PtTqSetSafeCntr 0;
BA_ "GenSigSendType" SG_ 357 PtTqSetSafeGrdtNeg 0;
BA_ "GenSigSendType" SG_ 357 PtTqSetSafeGrdtPos 0;
BA_ "GenSigSendType" SG_ 357 PtTqSetSafeReq 0;
BA_ "GenSigSendType" SG_ 353 RSDLConnectBTHeadSetSts 0;
BA_ "GenSigSendType" SG_ 353 RSDRConnectBTHeadSetSts 0;
BA_ "GenSigSendType" SG_ 890 RadioSrcSts 0;
BA_ "GenSigSendType" SG_ 848 RecOfImpctCrashFrnt 0;
BA_ "GenSigSendType" SG_ 848 RecOfImpctCrashOffroadA 0;
BA_ "GenSigSendType" SG_ 848 RecOfImpctCrashOffroadD 0;
BA_ "GenSigSendType" SG_ 848 RecOfImpctCrashOffroadRT 0;
BA_ "GenSigSendType" SG_ 848 RecOfImpctCrashOffroadRTsevere 0;
BA_ "GenSigSendType" SG_ 848 RecOfImpctCrashPed 0;
BA_ "GenSigSendType" SG_ 848 RecOfImpctCrashRe 0;
BA_ "GenSigSendType" SG_ 848 RecOfImpctCrashRollovr 0;
BA_ "GenSigSendType" SG_ 848 RecOfImpctCrashSideLe 0;
BA_ "GenSigSendType" SG_ 848 RecOfImpctCrashSideRi 0;
BA_ "GenSigSendType" SG_ 848 RecOfImpctCrashState 0;
BA_ "GenSigSendType" SG_ 848 RecOfImpctImpctDvx 0;
BA_ "GenSigSendType" SG_ 848 RecOfImpctImpctDvy 0;
BA_ "GenSigSendType" SG_ 848 RecOfImpctImpctRollAg 0;
BA_ "GenSigSendType" SG_ 848 RecOfImpctVehOri 0;
BA_ "GenSigStartValue" SG_ 848 RecOfImpctVehOri 4;
BA_ "GenSigSendType" SG_ 362 RoadInclnQly 0;
BA_ "GenSigStartValue" SG_ 362 RoadInclnQly 1;
BA_ "GenSigSendType" SG_ 362 RoadInclnRoadIncln 0;
BA_ "GenSigSendType" SG_ 913 RoomMode 0;
BA_ "GenSigSendType" SG_ 896 RoomModeSts 0;
BA_ "GenSigSendType" SG_ 353 SRDLConnectBTHeadSetSts 0;
BA_ "GenSigSendType" SG_ 353 SRDRConnectBTHeadSetSts 0;
BA_ "GenSigSendType" SG_ 914 SeatMtrlToAmplfr 1;
BA_ "GenSigSendType" SG_ 912 SeatMtrlToAmplfrSts 1;
BA_ "GenSigSendType" SG_ 914 SeatNrToAmplfr 1;
BA_ "GenSigSendType" SG_ 912 SeatNrToAmplfrSts 1;
BA_ "GenSigSendType" SG_ 672 SeatOccptAtRowSecDrSide2 0;
BA_ "GenSigStartValue" SG_ 672 SeatOccptAtRowSecDrSide2 1;
BA_ "GenSigSendType" SG_ 672 SeatOccptAtRowSecDrSideSnsSts2 0;
BA_ "GenSigSendType" SG_ 672 SeatOccptAtRowSecMid2 0;
BA_ "GenSigStartValue" SG_ 672 SeatOccptAtRowSecMid2 1;
BA_ "GenSigSendType" SG_ 672 SeatOccptAtRowSecMidSnsSts2 0;
BA_ "GenSigSendType" SG_ 672 SeatOccptAtRowSecPasSide2 0;
BA_ "GenSigStartValue" SG_ 672 SeatOccptAtRowSecPasSide2 1;
BA_ "GenSigSendType" SG_ 672 SeatOccptAtRowSecPasSideSnsSts2 0;
BA_ "GenSigSendType" SG_ 272 SeatOccptAtRowThrdMid 0;
BA_ "GenSigSendType" SG_ 913 SeatSoundPosn 0;
BA_ "GenSigSendType" SG_ 896 SeatSoundPosnSts 0;
BA_ "GenSigSendType" SG_ 640 SnsrFltOfPrkgDstCtrl1 0;
BA_ "GenSigSendType" SG_ 320 Spacapsule 0;
BA_ "GenSigSendType" SG_ 336 SpkrandAmplifrVariantType 1;
BA_ "GenSigSendType" SG_ 912 SpkrandAmplifrVariantTypeSts 1;
BA_ "GenSigSendType" SG_ 914 SteerWhlPosnToAmplfrExt 1;
BA_ "GenSigSendType" SG_ 33 SteerWhlPosnToAmplfrSts 1;
BA_ "GenSigSendType" SG_ 85 SteerWhlSnsrAg 0;
BA_ "GenSigSendType" SG_ 85 SteerWhlSnsrAgSpd 0;
BA_ "GenSigDataID" SG_ 85 SteerWhlSnsrChks "0x33";
BA_ "GenSigFuncType" SG_ 85 SteerWhlSnsrChks 15;
BA_ "GenSigSendType" SG_ 85 SteerWhlSnsrChks 0;
BA_ "GenSigFuncType" SG_ 85 SteerWhlSnsrCntr 16;
BA_ "GenSigSendType" SG_ 85 SteerWhlSnsrCntr 0;
BA_ "GenSigSendType" SG_ 85 SteerWhlSnsrQf 0;
BA_ "GenSigStartValue" SG_ 85 SteerWhlSnsrQf 1;
BA_ "GenSigSendType" SG_ 11 SunRoofPosnSts 0;
BA_ "GenSigSendType" SG_ 378 SupPfmncModReq 0;
BA_ "GenSigSendType" SG_ 399 TeleMute 1;
BA_ "GenSigSendType" SG_ 33 TeleMuteSts 1;
BA_ "GenSigSendType" SG_ 890 ThreeDimSurAdjmtOnOff1 0;
BA_ "GenSigSendType" SG_ 890 ThreeDimSurAdjmtsurroundlvlAdjmt 0;
BA_ "GenSigStartValue" SG_ 890 ThreeDimSurAdjmtsurroundlvlAdjmt 10;
BA_ "GenSigSendType" SG_ 352 TiAndDateIndcnDataValid 0;
BA_ "GenSigSendType" SG_ 352 TiAndDateIndcnDay 0;
BA_ "GenSigStartValue" SG_ 352 TiAndDateIndcnDay 1;
BA_ "GenSigSendType" SG_ 352 TiAndDateIndcnHr1 0;
BA_ "GenSigSendType" SG_ 352 TiAndDateIndcnMins1 0;
BA_ "GenSigSendType" SG_ 352 TiAndDateIndcnMth1 0;
BA_ "GenSigStartValue" SG_ 352 TiAndDateIndcnMth1 1;
BA_ "GenSigSendType" SG_ 352 TiAndDateIndcnSec1 0;
BA_ "GenSigSendType" SG_ 352 TiAndDateIndcnYr1 0;
BA_ "GenSigSendType" SG_ 314 TrOpenerSts 0;
BA_ "GenSigSendType" SG_ 41 TrSts 0;
BA_ "GenSigSendType" SG_ 914 TrdRowSeatMtrlToAmplfr 1;
BA_ "GenSigSendType" SG_ 912 TrdRowSeatMtrlToAmplfrSts 1;
BA_ "GenSigSendType" SG_ 890 TwoDimSurAdjmtOnOff1 0;
BA_ "GenSigSendType" SG_ 890 TwoDimSurAdjmtsurroundlvlAdjmt 0;
BA_ "GenSigStartValue" SG_ 890 TwoDimSurAdjmtsurroundlvlAdjmt 1;
BA_ "GenSigSendType" SG_ 890 VarEqualizerAdjmt 0;
BA_ "GenSigSendType" SG_ 362 VehBattUSysU 0;
BA_ "GenSigSendType" SG_ 362 VehBattUSysUQf 0;
BA_ "GenSigStartValue" SG_ 362 VehBattUSysUQf 1;
BA_ "GenSigSendType" SG_ 529 VehCfgPrmBlkIDBytePosn1 1;
BA_ "GenSigSendType" SG_ 529 VehCfgPrmCCPBytePosn2 1;
BA_ "GenSigSendType" SG_ 529 VehCfgPrmCCPBytePosn3 1;
BA_ "GenSigSendType" SG_ 529 VehCfgPrmCCPBytePosn4 1;
BA_ "GenSigSendType" SG_ 529 VehCfgPrmCCPBytePosn5 1;
BA_ "GenSigSendType" SG_ 529 VehCfgPrmCCPBytePosn6 1;
BA_ "GenSigSendType" SG_ 529 VehCfgPrmCCPBytePosn7 1;
BA_ "GenSigSendType" SG_ 529 VehCfgPrmCCPBytePosn8 1;
BA_ "GenSigSendType" SG_ 560 VehCfgPrmExtBlkIDBytePosn1 1;
BA_ "GenSigSendType" SG_ 560 VehCfgPrmExtCCPBytePosn2 1;
BA_ "GenSigSendType" SG_ 560 VehCfgPrmExtCCPBytePosn3 1;
BA_ "GenSigSendType" SG_ 560 VehCfgPrmExtCCPBytePosn4 1;
BA_ "GenSigSendType" SG_ 560 VehCfgPrmExtCCPBytePosn5 1;
BA_ "GenSigSendType" SG_ 560 VehCfgPrmExtCCPBytePosn6 1;
BA_ "GenSigSendType" SG_ 560 VehCfgPrmExtCCPBytePosn7 1;
BA_ "GenSigSendType" SG_ 560 VehCfgPrmExtCCPBytePosn8 1;
BA_ "GenSigSendType" SG_ 849 VehModMngtGlbSafe1CarModSts1 0;
BA_ "GenSigSendType" SG_ 849 VehModMngtGlbSafe1CarModSubtypWdCarModSubtyp 0;
BA_ "GenSigDataID" SG_ 849 VehModMngtGlbSafe1Chks "0x74";
BA_ "GenSigFuncType" SG_ 849 VehModMngtGlbSafe1Chks 15;
BA_ "GenSigSendType" SG_ 849 VehModMngtGlbSafe1Chks 0;
BA_ "GenSigFuncType" SG_ 849 VehModMngtGlbSafe1Cntr 16;
BA_ "GenSigSendType" SG_ 849 VehModMngtGlbSafe1Cntr 0;
BA_ "GenSigSendType" SG_ 849 VehModMngtGlbSafe1EgyLvlElecMai 0;
BA_ "GenSigSendType" SG_ 849 VehModMngtGlbSafe1EgyLvlElecSubtyp 0;
BA_ "GenSigSendType" SG_ 849 VehModMngtGlbSafe1FltEgyCnsWdSts 0;
BA_ "GenSigSendType" SG_ 849 VehModMngtGlbSafe1PwrLvlElecMai 0;
BA_ "GenSigSendType" SG_ 849 VehModMngtGlbSafe1PwrLvlElecSubtyp 0;
BA_ "GenSigSendType" SG_ 849 VehModMngtGlbSafe1UsgModSts 0;
BA_ "GenSigStartValue" SG_ 849 VehModMngtGlbSafe1UsgModSts 1;
BA_ "GenSigDataID" SG_ 362 VehMtnStChks "0x36";
BA_ "GenSigFuncType" SG_ 362 VehMtnStChks 15;
BA_ "GenSigSendType" SG_ 362 VehMtnStChks 0;
BA_ "GenSigFuncType" SG_ 362 VehMtnStCntr 16;
BA_ "GenSigSendType" SG_ 362 VehMtnStCntr 0;
BA_ "GenSigSendType" SG_ 362 VehMtnStVehMtnSt 0;
BA_ "GenSigSendType" SG_ 32 VehSpdLgtA 0;
BA_ "GenSigDataID" SG_ 32 VehSpdLgtChks "0x37";
BA_ "GenSigFuncType" SG_ 32 VehSpdLgtChks 15;
BA_ "GenSigSendType" SG_ 32 VehSpdLgtChks 0;
BA_ "GenSigFuncType" SG_ 32 VehSpdLgtCntr 16;
BA_ "GenSigSendType" SG_ 32 VehSpdLgtCntr 0;
BA_ "GenSigSendType" SG_ 32 VehSpdLgtQf 0;
BA_ "GenSigStartValue" SG_ 32 VehSpdLgtQf 1;
BA_ "GenSigSendType" SG_ 336 VehSpdLvl 0;
BA_ "GenSigStartValue" SG_ 336 VehSpdLvl 2;
BA_ "GenSigSendType" SG_ 896 VehSpdLvlSts 0;
BA_ "GenSigSendType" SG_ 316 VehTypToAmplfrExt 1;
BA_ "GenSigSendType" SG_ 917 VehTypToAmplfrExtSts 1;
BA_ "GenSigSendType" SG_ 613 VinBlockNr 1;
BA_ "GenSigSendType" SG_ 613 VinVINSignalPos1 1;
BA_ "GenSigSendType" SG_ 613 VinVINSignalPos2 1;
BA_ "GenSigSendType" SG_ 613 VinVINSignalPos3 1;
BA_ "GenSigSendType" SG_ 613 VinVINSignalPos4 1;
BA_ "GenSigSendType" SG_ 613 VinVINSignalPos5 1;
BA_ "GenSigSendType" SG_ 613 VinVINSignalPos6 1;
BA_ "GenSigSendType" SG_ 613 VinVINSignalPos7 1;
BA_ "GenSigSendType" SG_ 353 VirtVenueMod 0;
BA_ "GenSigSendType" SG_ 353 VirtVenueOnOff1 0;
BA_ "GenSigSendType" SG_ 272 VolLvlA7 0;
BA_ "GenSigSendType" SG_ 293 VolLvlA7Sts 0;
BA_ "GenSigSendType" SG_ 272 VolLvlA8 0;
BA_ "GenSigSendType" SG_ 293 VolLvlA8Sts 0;
BA_ "GenSigSendType" SG_ 914 VolLvlA9 0;
BA_ "GenSigSendType" SG_ 913 VolLvlBgrnd 0;
BA_ "GenSigSendType" SG_ 399 VolLvlFgrnd0 1;
BA_ "GenSigSendType" SG_ 949 VolLvlFgrnd0Sts 0;
BA_ "GenSigSendType" SG_ 336 VolLvlFgrnd1 0;
BA_ "GenSigSendType" SG_ 1041 VolLvlFgrnd2Ch1 0;
BA_ "GenSigSendType" SG_ 304 VolLvlFgrnd2Ch10 0;
BA_ "GenSigSendType" SG_ 80 VolLvlFgrnd2Ch10Sts 0;
BA_ "GenSigSendType" SG_ 304 VolLvlFgrnd2Ch11 0;
BA_ "GenSigSendType" SG_ 80 VolLvlFgrnd2Ch11Sts 0;
BA_ "GenSigSendType" SG_ 304 VolLvlFgrnd2Ch12 0;
BA_ "GenSigSendType" SG_ 80 VolLvlFgrnd2Ch12Sts 0;
BA_ "GenSigSendType" SG_ 1040 VolLvlFgrnd2Ch1Sts 0;
BA_ "GenSigSendType" SG_ 1041 VolLvlFgrnd2Ch2 0;
BA_ "GenSigSendType" SG_ 1040 VolLvlFgrnd2Ch2Sts 0;
BA_ "GenSigSendType" SG_ 1041 VolLvlFgrnd2Ch3 0;
BA_ "GenSigSendType" SG_ 1040 VolLvlFgrnd2Ch3Sts 0;
BA_ "GenSigSendType" SG_ 1041 VolLvlFgrnd2Ch4 0;
BA_ "GenSigSendType" SG_ 1040 VolLvlFgrnd2Ch4Sts 0;
BA_ "GenSigSendType" SG_ 1041 VolLvlFgrnd2Ch5 0;
BA_ "GenSigSendType" SG_ 1040 VolLvlFgrnd2Ch5Sts 0;
BA_ "GenSigSendType" SG_ 1041 VolLvlFgrnd2Ch6 0;
BA_ "GenSigSendType" SG_ 1040 VolLvlFgrnd2Ch6Sts 0;
BA_ "GenSigSendType" SG_ 1041 VolLvlFgrnd2Ch7 0;
BA_ "GenSigSendType" SG_ 1040 VolLvlFgrnd2Ch7Sts 0;
BA_ "GenSigSendType" SG_ 304 VolLvlFgrnd2Ch8 0;
BA_ "GenSigSendType" SG_ 80 VolLvlFgrnd2Ch8Sts 0;
BA_ "GenSigSendType" SG_ 304 VolLvlFgrnd2Ch9 0;
BA_ "GenSigSendType" SG_ 80 VolLvlFgrnd2Ch9Sts 0;
BA_ "GenSigSendType" SG_ 1281 WakeUpReasonsforDHU 0;
BA_ "GenSigSendType" SG_ 399 WarnIntrptLoglDHU 1;
BA_ "GenSigSendType" SG_ 912 WarnIntrptLoglDHUSts 1;
BA_ "GenSigStartValue" SG_ 314 WhlMotSysTqReq 2047;
BA_ "GenSigDataID" SG_ 384 WhlRotToothCntrChks "0x19C8";
BA_ "GenSigFuncType" SG_ 384 WhlRotToothCntrChks 15;
BA_ "GenSigSendType" SG_ 384 WhlRotToothCntrChks 0;
BA_ "GenSigFuncType" SG_ 384 WhlRotToothCntrCntr 16;
BA_ "GenSigSendType" SG_ 384 WhlRotToothCntrCntr 0;
BA_ "GenSigSendType" SG_ 384 WhlRotToothCntrFrntLe 0;
BA_ "GenSigSendType" SG_ 384 WhlRotToothCntrFrntRi 0;
BA_ "GenSigSendType" SG_ 384 WhlRotToothCntrReLe 0;
BA_ "GenSigSendType" SG_ 384 WhlRotToothCntrReRi 0;
BA_ "GenSigDataID" SG_ 257 WhlSpdCircumlFrntChks "0x6F";
BA_ "GenSigFuncType" SG_ 257 WhlSpdCircumlFrntChks 15;
BA_ "GenSigSendType" SG_ 257 WhlSpdCircumlFrntChks 0;
BA_ "GenSigFuncType" SG_ 257 WhlSpdCircumlFrntCntr 16;
BA_ "GenSigSendType" SG_ 257 WhlSpdCircumlFrntCntr 0;
BA_ "GenSigSendType" SG_ 257 WhlSpdCircumlFrntLe 0;
BA_ "GenSigSendType" SG_ 257 WhlSpdCircumlFrntLeQf 0;
BA_ "GenSigStartValue" SG_ 257 WhlSpdCircumlFrntLeQf 1;
BA_ "GenSigSendType" SG_ 257 WhlSpdCircumlFrntRiQf 0;
BA_ "GenSigStartValue" SG_ 257 WhlSpdCircumlFrntRiQf 1;
BA_ "GenSigSendType" SG_ 257 WhlSpdCircumlFrntWhlSpdCircumlFrntRi 0;
BA_ "GenSigDataID" SG_ 41 WhlSpdCircumlReChks "0x7C";
BA_ "GenSigFuncType" SG_ 41 WhlSpdCircumlReChks 15;
BA_ "GenSigSendType" SG_ 41 WhlSpdCircumlReChks 0;
BA_ "GenSigFuncType" SG_ 41 WhlSpdCircumlReCntr 16;
BA_ "GenSigSendType" SG_ 41 WhlSpdCircumlReCntr 0;
BA_ "GenSigSendType" SG_ 41 WhlSpdCircumlReLe 0;
BA_ "GenSigSendType" SG_ 41 WhlSpdCircumlReLeQf 0;
BA_ "GenSigStartValue" SG_ 41 WhlSpdCircumlReLeQf 1;
BA_ "GenSigSendType" SG_ 41 WhlSpdCircumlReRi 0;
BA_ "GenSigSendType" SG_ 41 WhlSpdCircumlReRiQf 0;
BA_ "GenSigStartValue" SG_ 41 WhlSpdCircumlReRiQf 1;
BA_ "GenSigSendType" SG_ 7 WinPosnStsAtDrvr 0;
BA_ "GenSigSendType" SG_ 7 WinPosnStsAtPass 0;
BA_ "GenSigSendType" SG_ 7 WinPosnStsAtReLe 0;
BA_ "GenSigSendType" SG_ 7 WinPosnStsAtReRi 0;

VAL_ 896 AcoustModSts 0 "NoYesCrit1_NotVld1" 1 "NoYesCrit1_No" 2 "NoYesCrit1_Yes" 3 "NoYesCrit1_NotVld2";
VAL_ 896 AudioMuteSts 0 "Unmute" 1 "mute";
VAL_ 896 Fgrnd1stForActvtSts 0 "Inact_Inactive" 1 "Inact_Active";
VAL_ 896 Fgrnd2ndForActvtSts 0 "Inact_Inactive" 1 "Inact_Active";
VAL_ 896 RoomModeSts 0 "RoomMode_Stereo_All" 1 "RoomMode_Stereo_Driver" 2 "RoomMode_Stereo_Rear" 3 "RoomMode_Centerpoint_All" 4 "RoomMode_Centerpoint_Driver_Future" 5 "RoomMode_Centerpoint_Rear_Future" 6 "RoomMode_custom" 7 "RoomMode_Reserved1" 8 "RoomMode_Reserved2" 9 "RoomMode_Reserved3" 10 "RoomMode_Reserved4" 11 "RoomMode_Reserved5" 12 "RoomMode_Reserved6" 13 "RoomMode_Reserved7" 14 "RoomMode_Reserved8" 15 "RoomMode_Reserved9";
VAL_ 897 BgrndForAudOutChStsAudOutpCh1 0 "Boolean_FALSE" 1 "Boolean_TRUE";
VAL_ 897 BgrndForAudOutChStsAudOutpCh10 0 "Boolean_FALSE" 1 "Boolean_TRUE";
VAL_ 897 BgrndForAudOutChStsAudOutpCh11 0 "Boolean_FALSE" 1 "Boolean_TRUE";
VAL_ 897 BgrndForAudOutChStsAudOutpCh12 0 "Boolean_FALSE" 1 "Boolean_TRUE";
VAL_ 897 BgrndForAudOutChStsAudOutpCh2 0 "Boolean_FALSE" 1 "Boolean_TRUE";
VAL_ 897 BgrndForAudOutChStsAudOutpCh3 0 "Boolean_FALSE" 1 "Boolean_TRUE";
VAL_ 897 BgrndForAudOutChStsAudOutpCh4 0 "Boolean_FALSE" 1 "Boolean_TRUE";
VAL_ 897 BgrndForAudOutChStsAudOutpCh5 0 "Boolean_FALSE" 1 "Boolean_TRUE";
VAL_ 897 BgrndForAudOutChStsAudOutpCh6 0 "Boolean_FALSE" 1 "Boolean_TRUE";
VAL_ 897 BgrndForAudOutChStsAudOutpCh7 0 "Boolean_FALSE" 1 "Boolean_TRUE";
VAL_ 897 BgrndForAudOutChStsAudOutpCh8 0 "Boolean_FALSE" 1 "Boolean_TRUE";
VAL_ 897 BgrndForAudOutChStsAudOutpCh9 0 "Boolean_FALSE" 1 "Boolean_TRUE";
VAL_ 897 Fgrnd1stForAudOutpChStsAudOutpCh1 0 "Boolean_FALSE" 1 "Boolean_TRUE";
VAL_ 897 Fgrnd1stForAudOutpChStsAudOutpCh10 0 "Boolean_FALSE" 1 "Boolean_TRUE";
VAL_ 897 Fgrnd1stForAudOutpChStsAudOutpCh11 0 "Boolean_FALSE" 1 "Boolean_TRUE";
VAL_ 897 Fgrnd1stForAudOutpChStsAudOutpCh12 0 "Boolean_FALSE" 1 "Boolean_TRUE";
VAL_ 897 Fgrnd1stForAudOutpChStsAudOutpCh2 0 "Boolean_FALSE" 1 "Boolean_TRUE";
VAL_ 897 Fgrnd1stForAudOutpChStsAudOutpCh3 0 "Boolean_FALSE" 1 "Boolean_TRUE";
VAL_ 897 Fgrnd1stForAudOutpChStsAudOutpCh4 0 "Boolean_FALSE" 1 "Boolean_TRUE";
VAL_ 897 Fgrnd1stForAudOutpChStsAudOutpCh5 0 "Boolean_FALSE" 1 "Boolean_TRUE";
VAL_ 897 Fgrnd1stForAudOutpChStsAudOutpCh6 0 "Boolean_FALSE" 1 "Boolean_TRUE";
VAL_ 897 Fgrnd1stForAudOutpChStsAudOutpCh7 0 "Boolean_FALSE" 1 "Boolean_TRUE";
VAL_ 897 Fgrnd1stForAudOutpChStsAudOutpCh8 0 "Boolean_FALSE" 1 "Boolean_TRUE";
VAL_ 897 Fgrnd1stForAudOutpChStsAudOutpCh9 0 "Boolean_FALSE" 1 "Boolean_TRUE";
VAL_ 897 Fgrnd2ndForAudOutpChStsAudOutpCh1 0 "Boolean_FALSE" 1 "Boolean_TRUE";
VAL_ 897 Fgrnd2ndForAudOutpChStsAudOutpCh10 0 "Boolean_FALSE" 1 "Boolean_TRUE";
VAL_ 897 Fgrnd2ndForAudOutpChStsAudOutpCh11 0 "Boolean_FALSE" 1 "Boolean_TRUE";
VAL_ 897 Fgrnd2ndForAudOutpChStsAudOutpCh12 0 "Boolean_FALSE" 1 "Boolean_TRUE";
VAL_ 897 Fgrnd2ndForAudOutpChStsAudOutpCh2 0 "Boolean_FALSE" 1 "Boolean_TRUE";
VAL_ 897 Fgrnd2ndForAudOutpChStsAudOutpCh3 0 "Boolean_FALSE" 1 "Boolean_TRUE";
VAL_ 897 Fgrnd2ndForAudOutpChStsAudOutpCh4 0 "Boolean_FALSE" 1 "Boolean_TRUE";
VAL_ 897 Fgrnd2ndForAudOutpChStsAudOutpCh5 0 "Boolean_FALSE" 1 "Boolean_TRUE";
VAL_ 897 Fgrnd2ndForAudOutpChStsAudOutpCh6 0 "Boolean_FALSE" 1 "Boolean_TRUE";
VAL_ 897 Fgrnd2ndForAudOutpChStsAudOutpCh7 0 "Boolean_FALSE" 1 "Boolean_TRUE";
VAL_ 897 Fgrnd2ndForAudOutpChStsAudOutpCh8 0 "Boolean_FALSE" 1 "Boolean_TRUE";
VAL_ 897 Fgrnd2ndForAudOutpChStsAudOutpCh9 0 "Boolean_FALSE" 1 "Boolean_TRUE";
VAL_ 944 AmplifrOpSts 0 "SysSts4_Standby" 1 "SysSts4_Normal" 2 "SysSts4_Recovery";
VAL_ 912 ArtificialSoundPreviewSts 0 "ActvnAvl2_NoCmd" 1 "ActvnAvl2_Actvn" 2 "ActvnAvl2_Deactvn";
VAL_ 912 Chiming1MuteSts 0 "Unmute" 1 "mute";
VAL_ 912 Chiming2MuteSts 0 "Unmute" 1 "mute";
VAL_ 912 Chiming3MuteSts 0 "Unmute" 1 "mute";
VAL_ 912 Chiming4MuteSts 0 "Unmute" 1 "mute";
VAL_ 80 AcoustEfectPrvtCinePsnSts 0 "NoYesCrit1_NotVld1" 1 "NoYesCrit1_No" 2 "NoYesCrit1_Yes" 3 "NoYesCrit1_NotVld2";
VAL_ 80 BgrndForActvtSts 0 "Inact_Inactive" 1 "Inact_Active";
VAL_ 80 CptAdvExtSwtSts 0 "OffOnErrInvalid_Off" 1 "OffOnErrInvalid_On" 2 "OffOnErrInvalid_Err" 3 "OffOnErrInvalid_Invalid";
VAL_ 80 Feedback1SelectSts 0 "Channel_Invalid" 1 "Channel_CH1" 2 "Channel_CH2" 3 "Channel_CH3" 4 "Channel_CH4" 5 "Channel_CH5" 6 "Channel_CH6" 7 "Channel_CH7" 8 "Channel_CH8" 9 "Channel_CH9" 10 "Channel_CH10" 11 "Channel_CH11" 12 "Channel_CH12";
VAL_ 80 Feedback2SelectSts 0 "Channel_Invalid" 1 "Channel_CH1" 2 "Channel_CH2" 3 "Channel_CH3" 4 "Channel_CH4" 5 "Channel_CH5" 6 "Channel_CH6" 7 "Channel_CH7" 8 "Channel_CH8" 9 "Channel_CH9" 10 "Channel_CH10" 11 "Channel_CH11" 12 "Channel_CH12";
VAL_ 33 AllmuteSts 0 "Unmute" 1 "mute";
VAL_ 33 ArtificialSoundOpenReqSts 0 "OnOff1_Off" 1 "OnOff1_On";
VAL_ 33 ArtificialSoundSelectReqSts 0 "SteerMod_Ukwn" 1 "SteerMod_Mod1" 2 "SteerMod_Mod2" 3 "SteerMod_Mod3" 4 "SteerMod_Mod4" 5 "SteerMod_Resd5" 6 "SteerMod_Resd6" 7 "SteerMod_Resd7";
VAL_ 33 NaviMuteSts 0 "Unmute" 1 "mute";
VAL_ 33 TeleMuteSts 0 "Unmute" 1 "mute";
VAL_ 917 Audio2MuteSts 0 "Unmute" 1 "mute";
VAL_ 917 LndBtnSts 0 "OnOff1_Off" 1 "OnOff1_On";
VAL_ 820 ExtrLtgStsAFS 0 "DevSts4_Off" 1 "DevSts4_On" 2 "DevSts4_Err" 3 "DevSts4_Resd";
VAL_ 820 ExtrLtgStsAHBC 0 "DevSts4_Off" 1 "DevSts4_On" 2 "DevSts4_Err" 3 "DevSts4_Resd";
VAL_ 820 ExtrLtgStsAHL 0 "DevSts4_Off" 1 "DevSts4_On" 2 "DevSts4_Err" 3 "DevSts4_Resd";
VAL_ 820 ExtrLtgStsAllWL 0 "DevSts4_Off" 1 "DevSts4_On" 2 "DevSts4_Err" 3 "DevSts4_Resd";
VAL_ 820 ExtrLtgStsApproach 0 "DevSts4_Off" 1 "DevSts4_On" 2 "DevSts4_Err" 3 "DevSts4_Resd";
VAL_ 820 ExtrLtgStsCornrgLi 0 "DevSts4_Off" 1 "DevSts4_On" 2 "DevSts4_Err" 3 "DevSts4_Resd";
VAL_ 820 ExtrLtgStsDBL 0 "DevSts4_Off" 1 "DevSts4_On" 2 "DevSts4_Err" 3 "DevSts4_Resd";
VAL_ 820 ExtrLtgStsDRL 0 "DevSts4_Off" 1 "DevSts4_On" 2 "DevSts4_Err" 3 "DevSts4_Resd";
VAL_ 820 ExtrLtgStsFlash 0 "DevSts4_Off" 1 "DevSts4_On" 2 "DevSts4_Err" 3 "DevSts4_Resd";
VAL_ 820 ExtrLtgStsFrntFog 0 "DevSts4_Off" 1 "DevSts4_On" 2 "DevSts4_Err" 3 "DevSts4_Resd";
VAL_ 820 ExtrLtgStsGoodbye 0 "DevSts4_Off" 1 "DevSts4_On" 2 "DevSts4_Err" 3 "DevSts4_Resd";
VAL_ 820 ExtrLtgStsHiBeam 0 "DevSts4_Off" 1 "DevSts4_On" 2 "DevSts4_Err" 3 "DevSts4_Resd";
VAL_ 820 ExtrLtgStsHomeSafe 0 "DevSts4_Off" 1 "DevSts4_On" 2 "DevSts4_Err" 3 "DevSts4_Resd";
VAL_ 820 ExtrLtgStsHWL 0 "DevSts4_Off" 1 "DevSts4_On" 2 "DevSts4_Err" 3 "DevSts4_Resd";
VAL_ 820 ExtrLtgStsLoBeam 0 "DevSts4_Off" 1 "DevSts4_On" 2 "DevSts4_Err" 3 "DevSts4_Resd";
VAL_ 820 ExtrLtgStsLtgShow 0 "DevSts4_Off" 1 "DevSts4_On" 2 "DevSts4_Err" 3 "DevSts4_Resd";
VAL_ 820 ExtrLtgStsPosLiFrnt 0 "DevSts4_Off" 1 "DevSts4_On" 2 "DevSts4_Err" 3 "DevSts4_Resd";
VAL_ 820 ExtrLtgStsPosLiRe 0 "DevSts4_Off" 1 "DevSts4_On" 2 "DevSts4_Err" 3 "DevSts4_Resd";
VAL_ 820 ExtrLtgStsReFog 0 "DevSts4_Off" 1 "DevSts4_On" 2 "DevSts4_Err" 3 "DevSts4_Resd";
VAL_ 820 ExtrLtgStsReverseLi 0 "DevSts4_Off" 1 "DevSts4_On" 2 "DevSts4_Err" 3 "DevSts4_Resd";
VAL_ 820 ExtrLtgStsStopLi 0 "DevSts4_Off" 1 "DevSts4_On" 2 "DevSts4_Err" 3 "DevSts4_Resd";
VAL_ 820 ExtrLtgStsTurnIndrLe 0 "DevSts4_Off" 1 "DevSts4_On" 2 "DevSts4_Err" 3 "DevSts4_Resd";
VAL_ 820 ExtrLtgStsTurnIndrRi 0 "DevSts4_Off" 1 "DevSts4_On" 2 "DevSts4_Err" 3 "DevSts4_Resd";
VAL_ 820 ExtrLtgStsWelcome 0 "DevSts4_Off" 1 "DevSts4_On" 2 "DevSts4_Err" 3 "DevSts4_Resd";
VAL_ 398 BrkPedlrRatQf 0 "GenQf1_UndefindDataAccur" 1 "GenQf1_TmpUndefdData" 2 "GenQf1_DataAccurNotWithinSpcn" 3 "GenQf1_AccurData";
VAL_ 368 CptAdvExtSwt 0 "OnOff1_Off" 1 "OnOff1_On";
VAL_ 379 AmplifrTurnOn 0 "Boolean_FALSE" 1 "Boolean_TRUE";
VAL_ 379 ANCcfgToAmplfr 0 "ActvNoiseCtrl_Without" 1 "ActvNoiseCtrl_EOE_EOR" 2 "ActvNoiseCtrl_EOE" 3 "ActvNoiseCtrl_EOR" 4 "ActvNoiseCtrl_Road";
VAL_ 379 ArtificialSoundOpenReq 0 "OnOff1_Off" 1 "OnOff1_On";
VAL_ 379 ArtificialSoundSelectReq 0 "SteerMod_Ukwn" 1 "SteerMod_Mod1" 2 "SteerMod_Mod2" 3 "SteerMod_Mod3" 4 "SteerMod_Mod4" 5 "SteerMod_Resd5" 6 "SteerMod_Resd6" 7 "SteerMod_Resd7";
VAL_ 399 Allmute 0 "Unmute" 1 "mute";
VAL_ 399 Chiming1Mute 0 "Unmute" 1 "mute";
VAL_ 399 Chiming2Mute 0 "Unmute" 1 "mute";
VAL_ 399 Chiming3Mute 0 "Unmute" 1 "mute";
VAL_ 399 Chiming4Mute 0 "Unmute" 1 "mute";
VAL_ 399 NaviMute 0 "Unmute" 1 "mute";
VAL_ 399 TeleMute 0 "Unmute" 1 "mute";
VAL_ 384 MonrSysSts1 0 "SysSts3_Invalid" 1 "SysSts3_Sleep" 2 "SysSts3_Standby" 3 "SysSts3_Active" 4 "SysSts3_Failure" 5 "SysSts3_SelfInspection" 6 "SysSts3_Reserved1" 7 "SysSts3_Reserved2";
VAL_ 378 PdcLoMuteBtnReq 0 "OnOffNoReq_NoReq" 1 "OnOffNoReq_On" 2 "OnOffNoReq_Off";
VAL_ 378 PrkgDstCtrlLoSysSwt 0 "OnOff1_Off" 1 "OnOff1_On";
VAL_ 378 SupPfmncModReq 0 "OnOff1_Off" 1 "OnOff1_On";
VAL_ 517 PrkgAssiReSts 0 "SysSts3_Invalid" 1 "SysSts3_Sleep" 2 "SysSts3_Standby" 3 "SysSts3_Active" 4 "SysSts3_Failure" 5 "SysSts3_SelfInspection" 6 "SysSts3_Reserved1" 7 "SysSts3_Reserved2";
VAL_ 320 Spacapsule 0 "OnOff1_Off" 1 "OnOff1_On";
VAL_ 326 LockgCenStsLockSt 0 "LockSt3_LockUndefd" 1 "LockSt3_LockUnlckd" 2 "LockSt3_LockTrUnlckd" 3 "LockSt3_LockLockd";
VAL_ 326 LockgCenStsTrigSrc 0 "LockTrigSrc2_NoTrigSrc" 1 "LockTrigSrc2_KeyRem" 2 "LockTrigSrc2_Keyls" 3 "LockTrigSrc2_IntrSwt" 4 "LockTrigSrc2_SpdAut" 5 "LockTrigSrc2_TmrAut" 6 "LockTrigSrc2_Slam" 7 "LockTrigSrc2_Telm" 8 "LockTrigSrc2_Crash" 9 "LockTrigSrc2_Apprch" 10 "LockTrigSrc2_OutsOth" 11 "LockTrigSrc2_InsOth";
VAL_ 326 LockgCenStsUpdEve 0 "Boolean_FALSE" 1 "Boolean_TRUE";
VAL_ 352 TiAndDateIndcnDataValid 0 "NoYes1_No" 1 "NoYes1_Yes";
VAL_ 890 AdpvBassEnhmtAdjmtOnOff1 0 "OnOff1_Off" 1 "OnOff1_On";
VAL_ 890 AdpvBassEnhmtAdjmtsurroundlvlAdjmt 0 "Lvl40_Level1_Low" 1 "Lvl40_Level2_Mid" 2 "Lvl40_Level3_High" 3 "Lvl40_Reserved";
VAL_ 890 RadioSrcSts 0 "OnOff1_Off" 1 "OnOff1_On";
VAL_ 890 ThreeDimSurAdjmtOnOff1 0 "OnOff1_Off" 1 "OnOff1_On";
VAL_ 890 ThreeDimSurAdjmtsurroundlvlAdjmt 0 "Level5_level0" 1 "Level5_level1" 2 "Level5_level2" 3 "Level5_level3" 4 "Level5_level4" 5 "Level5_level5" 6 "Level5_level6" 7 "Level5_level7" 8 "Level5_level8" 9 "Level5_level9" 10 "Level5_level10" 11 "Level5_level11" 12 "Level5_level12" 13 "Level5_level13" 14 "Level5_level14" 15 "Level5_level15" 16 "Level5_level16" 17 "Level5_level17" 18 "Level5_level18" 19 "Level5_level19" 20 "Level5_level20" 21 "Level5_level21" 22 "Level5_level22" 23 "Level5_level23" 24 "Level5_level24" 25 "Level5_level25" 26 "Level5_level26" 27 "Level5_level27" 28 "Level5_level28" 29 "Level5_level29" 30 "Level5_level30" 31 "Level5_level31";
VAL_ 890 TwoDimSurAdjmtOnOff1 0 "OnOff1_Off" 1 "OnOff1_On";
VAL_ 890 TwoDimSurAdjmtsurroundlvlAdjmt 0 "Lvl40_Level1_Low" 1 "Lvl40_Level2_Mid" 2 "Lvl40_Level3_High" 3 "Lvl40_Reserved";
VAL_ 890 VarEqualizerAdjmt 0 "Adjmt4_ReferenceFR" 1 "Adjmt4_ReferenceRR" 2 "Adjmt4_ReferenceAll" 3 "Adjmt4_CinemaTheatre" 4 "Adjmt4_EasyListening" 5 "Adjmt4_music";
VAL_ 346 IndcnUnitClkFmt 0 "ClkFmt_Hr24" 1 "ClkFmt_Hr12" 2 "ClkFmt_UkwnClkFmt";
VAL_ 346 IndcnUnitDateFmt 0 "DateFmt_DateFmt1" 1 "DateFmt_DateFmt2" 2 "DateFmt_DateFmt3" 3 "DateFmt_UkwnFmt";
VAL_ 346 IndcnUnitDstLong 0 "DstLong_km" 1 "DstLong_miles" 2 "DstLong_UkwnUnit";
VAL_ 346 IndcnUnitDstSho 0 "DstSho_Mtr" 1 "DstSho_Ft" 2 "DstSho_Yards" 3 "DstSho_UkwnUnit";
VAL_ 346 IndcnUnitFuCnsUnit 0 "FuCnsIndcdUnit_LperHectoKiloM" 1 "FuCnsIndcdUnit_KiloMPerL" 2 "FuCnsIndcdUnit_MilePerGallonEngland" 3 "FuCnsIndcdUnit_MilePerGallonUsa" 4 "FuCnsIndcdUnit_UkwnUnit";
VAL_ 346 IndcnUnitPUnit 0 "PUnit_Pa" 1 "PUnit_Psi" 2 "PUnit_Bar" 3 "PUnit_Atm" 4 "PUnit_UkwnUnit";
VAL_ 346 IndcnUnitSpdUnit 0 "VehSpdIndcdUnit_Kmph" 1 "VehSpdIndcdUnit_Mph" 2 "VehSpdIndcdUnit_UkwnUnit";
VAL_ 346 IndcnUnitTUnit 0 "AmbTIndcdUnit_Celsius" 1 "AmbTIndcdUnit_Fahrenheit" 2 "AmbTIndcdUnit_UkwnUnit";
VAL_ 346 IndcnUnitVolUnit 0 "VolUnit_litre" 1 "VolUnit_gallon1" 2 "VolUnit_gallon2" 3 "VolUnit_UkwnUnit";
VAL_ 353 MediaSouce 0 "MediaSouce_Idle" 1 "MediaSouce_CSD" 2 "MediaSouce_PSD" 3 "MediaSouce_Reserved";
VAL_ 353 PassHdrestSwt 0 "OnOffNoReq_NoReq" 1 "OnOffNoReq_On" 2 "OnOffNoReq_Off";
VAL_ 353 PSDConnectBTHeadSetSts 0 "ConnectionSts_Disconnect" 1 "ConnectionSts_Connect";
VAL_ 353 PtDrvrSetg 0 "DrvModReqType1_Undefd" 1 "DrvModReqType1_ECO" 2 "DrvModReqType1_Comfort_Normal" 3 "DrvModReqType1_Dynamic_Sport" 4 "DrvModReqType1_Individual" 5 "DrvModReqType1_Offroad_CrossTerrain" 6 "DrvModReqType1_Adaptive" 7 "DrvModReqType1_Race" 8 "DrvModReqType1_Pure_EV" 9 "DrvModReqType1_Hybrid" 10 "DrvModReqType1_Power" 11 "DrvModReqType1_Snow" 12 "DrvModReqType1_Sand" 13 "DrvModReqType1_Mud" 14 "DrvModReqType1_Rock" 15 "DrvModReqType1_Err";
VAL_ 353 RSDLConnectBTHeadSetSts 0 "ConnectionSts_Disconnect" 1 "ConnectionSts_Connect";
VAL_ 353 RSDRConnectBTHeadSetSts 0 "ConnectionSts_Disconnect" 1 "ConnectionSts_Connect";
VAL_ 353 SRDLConnectBTHeadSetSts 0 "ConnectionSts_Disconnect" 1 "ConnectionSts_Connect";
VAL_ 353 SRDRConnectBTHeadSetSts 0 "ConnectionSts_Disconnect" 1 "ConnectionSts_Connect";
VAL_ 353 VirtVenueMod 0 "Mod11_Smallroom" 1 "Mod11_Middleroom" 2 "Mod11_Largeroom" 3 "Mod11_Arena" 4 "Mod11_reserve1" 5 "Mod11_reserve2" 6 "Mod11_reserve3" 7 "Mod11_reserve4";
VAL_ 353 VirtVenueOnOff1 0 "OnOff1_Off" 1 "OnOff1_On";
VAL_ 272 ActvtFgrnd2 0 "Inact_Inactive" 1 "Inact_Active";
VAL_ 272 Audiomode 0 "Audiomode_Stereo" 1 "Audiomode_Surround" 2 "Audiomode_VirtualVenue" 3 "Audiomode_AtmosorWANOS";
VAL_ 272 Fgrnd2ForAudOutpChAudOutpCh1 0 "Boolean_FALSE" 1 "Boolean_TRUE";
VAL_ 272 Fgrnd2ForAudOutpChAudOutpCh10 0 "Boolean_FALSE" 1 "Boolean_TRUE";
VAL_ 272 Fgrnd2ForAudOutpChAudOutpCh11 0 "Boolean_FALSE" 1 "Boolean_TRUE";
VAL_ 272 Fgrnd2ForAudOutpChAudOutpCh12 0 "Boolean_FALSE" 1 "Boolean_TRUE";
VAL_ 272 Fgrnd2ForAudOutpChAudOutpCh2 0 "Boolean_FALSE" 1 "Boolean_TRUE";
VAL_ 272 Fgrnd2ForAudOutpChAudOutpCh3 0 "Boolean_FALSE" 1 "Boolean_TRUE";
VAL_ 272 Fgrnd2ForAudOutpChAudOutpCh4 0 "Boolean_FALSE" 1 "Boolean_TRUE";
VAL_ 272 Fgrnd2ForAudOutpChAudOutpCh5 0 "Boolean_FALSE" 1 "Boolean_TRUE";
VAL_ 272 Fgrnd2ForAudOutpChAudOutpCh6 0 "Boolean_FALSE" 1 "Boolean_TRUE";
VAL_ 272 Fgrnd2ForAudOutpChAudOutpCh7 0 "Boolean_FALSE" 1 "Boolean_TRUE";
VAL_ 272 Fgrnd2ForAudOutpChAudOutpCh8 0 "Boolean_FALSE" 1 "Boolean_TRUE";
VAL_ 272 Fgrnd2ForAudOutpChAudOutpCh9 0 "Boolean_FALSE" 1 "Boolean_TRUE";
VAL_ 272 SeatOccptAtRowThrdMid 0 "PassSeatSts1_Empty" 1 "PassSeatSts1_Fmale" 2 "PassSeatSts1_OccptLrg" 3 "PassSeatSts1_Ukwn";
VAL_ 913 AcoustMod 0 "NoYesCrit1_NotVld1" 1 "NoYesCrit1_No" 2 "NoYesCrit1_Yes" 3 "NoYesCrit1_NotVld2";
VAL_ 913 ActvtBgrnd 0 "Inact_Inactive" 1 "Inact_Active";
VAL_ 913 DrvrSeatSnsrSts 0 "OkNokDi_Ok" 1 "OkNokDi_NotOk" 2 "OkNokDi_Disabled" 3 "OkNokDi_Reserved";
VAL_ 913 DrvrSeatSts 0 "OccptPresSt1_Undefd1" 1 "OccptPresSt1_OccptNotPrsnt" 2 "OccptPresSt1_OccptPrsnt" 3 "OccptPresSt1_Undefd2";
VAL_ 913 Feedback1Select 0 "Channel_Invalid" 1 "Channel_CH1" 2 "Channel_CH2" 3 "Channel_CH3" 4 "Channel_CH4" 5 "Channel_CH5" 6 "Channel_CH6" 7 "Channel_CH7" 8 "Channel_CH8" 9 "Channel_CH9" 10 "Channel_CH10" 11 "Channel_CH11" 12 "Channel_CH12";
VAL_ 913 Feedback2Select 0 "Channel_Invalid" 1 "Channel_CH1" 2 "Channel_CH2" 3 "Channel_CH3" 4 "Channel_CH4" 5 "Channel_CH5" 6 "Channel_CH6" 7 "Channel_CH7" 8 "Channel_CH8" 9 "Channel_CH9" 10 "Channel_CH10" 11 "Channel_CH11" 12 "Channel_CH12";
VAL_ 913 RoomMode 0 "RoomMode_Stereo_All" 1 "RoomMode_Stereo_Driver" 2 "RoomMode_Stereo_Rear" 3 "RoomMode_Centerpoint_All" 4 "RoomMode_Centerpoint_Driver_Future" 5 "RoomMode_Centerpoint_Rear_Future" 6 "RoomMode_custom" 7 "RoomMode_Reserved1" 8 "RoomMode_Reserved2" 9 "RoomMode_Reserved3" 10 "RoomMode_Reserved4" 11 "RoomMode_Reserved5" 12 "RoomMode_Reserved6" 13 "RoomMode_Reserved7" 14 "RoomMode_Reserved8" 15 "RoomMode_Reserved9";
VAL_ 336 ActvtFgrnd1 0 "Inact_Inactive" 1 "Inact_Active";
VAL_ 336 AudioMute 0 "Unmute" 1 "mute";
VAL_ 336 BgrndForAudOutpChAudOutpCh1 0 "Boolean_FALSE" 1 "Boolean_TRUE";
VAL_ 336 BgrndForAudOutpChAudOutpCh10 0 "Boolean_FALSE" 1 "Boolean_TRUE";
VAL_ 336 BgrndForAudOutpChAudOutpCh11 0 "Boolean_FALSE" 1 "Boolean_TRUE";
VAL_ 336 BgrndForAudOutpChAudOutpCh12 0 "Boolean_FALSE" 1 "Boolean_TRUE";
VAL_ 336 BgrndForAudOutpChAudOutpCh2 0 "Boolean_FALSE" 1 "Boolean_TRUE";
VAL_ 336 BgrndForAudOutpChAudOutpCh3 0 "Boolean_FALSE" 1 "Boolean_TRUE";
VAL_ 336 BgrndForAudOutpChAudOutpCh4 0 "Boolean_FALSE" 1 "Boolean_TRUE";
VAL_ 336 BgrndForAudOutpChAudOutpCh5 0 "Boolean_FALSE" 1 "Boolean_TRUE";
VAL_ 336 BgrndForAudOutpChAudOutpCh6 0 "Boolean_FALSE" 1 "Boolean_TRUE";
VAL_ 336 BgrndForAudOutpChAudOutpCh7 0 "Boolean_FALSE" 1 "Boolean_TRUE";
VAL_ 336 BgrndForAudOutpChAudOutpCh8 0 "Boolean_FALSE" 1 "Boolean_TRUE";
VAL_ 336 BgrndForAudOutpChAudOutpCh9 0 "Boolean_FALSE" 1 "Boolean_TRUE";
VAL_ 336 VehSpdLvl 0 "VehSpdLvl_Off" 1 "VehSpdLvl_Low" 2 "VehSpdLvl_Middle" 3 "VehSpdLvl_High";
VAL_ 304 Fgrnd1ForAudOutpChAudOutpCh1 0 "Boolean_FALSE" 1 "Boolean_TRUE";
VAL_ 304 Fgrnd1ForAudOutpChAudOutpCh10 0 "Boolean_FALSE" 1 "Boolean_TRUE";
VAL_ 304 Fgrnd1ForAudOutpChAudOutpCh11 0 "Boolean_FALSE" 1 "Boolean_TRUE";
VAL_ 304 Fgrnd1ForAudOutpChAudOutpCh12 0 "Boolean_FALSE" 1 "Boolean_TRUE";
VAL_ 304 Fgrnd1ForAudOutpChAudOutpCh2 0 "Boolean_FALSE" 1 "Boolean_TRUE";
VAL_ 304 Fgrnd1ForAudOutpChAudOutpCh3 0 "Boolean_FALSE" 1 "Boolean_TRUE";
VAL_ 304 Fgrnd1ForAudOutpChAudOutpCh4 0 "Boolean_FALSE" 1 "Boolean_TRUE";
VAL_ 304 Fgrnd1ForAudOutpChAudOutpCh5 0 "Boolean_FALSE" 1 "Boolean_TRUE";
VAL_ 304 Fgrnd1ForAudOutpChAudOutpCh6 0 "Boolean_FALSE" 1 "Boolean_TRUE";
VAL_ 304 Fgrnd1ForAudOutpChAudOutpCh7 0 "Boolean_FALSE" 1 "Boolean_TRUE";
VAL_ 304 Fgrnd1ForAudOutpChAudOutpCh8 0 "Boolean_FALSE" 1 "Boolean_TRUE";
VAL_ 304 Fgrnd1ForAudOutpChAudOutpCh9 0 "Boolean_FALSE" 1 "Boolean_TRUE";
VAL_ 304 NotifForEmgyCall 0 "Boolean_FALSE" 1 "Boolean_TRUE";
VAL_ 914 ActvAudKtvMod 0 "OnOff1_Off" 1 "OnOff1_On";
VAL_ 344 DoorPassHndlSts 0 "DoorHndlSts_Ukwn" 1 "DoorHndlSts_FullRtrctd" 2 "DoorHndlSts_MovgOut" 3 "DoorHndlSts_StopDurgDply" 4 "DoorHndlSts_FullDplyd" 5 "DoorHndlSts_MovgIn" 6 "DoorHndlSts_StopDurgRtrct" 7 "DoorHndlSts_Flt";
VAL_ 344 DrvModReq 0 "DrvModReqType1_Undefd" 1 "DrvModReqType1_ECO" 2 "DrvModReqType1_Comfort_Normal" 3 "DrvModReqType1_Dynamic_Sport" 4 "DrvModReqType1_Individual" 5 "DrvModReqType1_Offroad_CrossTerrain" 6 "DrvModReqType1_Adaptive" 7 "DrvModReqType1_Race" 8 "DrvModReqType1_Pure_EV" 9 "DrvModReqType1_Hybrid" 10 "DrvModReqType1_Power" 11 "DrvModReqType1_Snow" 12 "DrvModReqType1_Sand" 13 "DrvModReqType1_Mud" 14 "DrvModReqType1_Rock" 15 "DrvModReqType1_Err";
VAL_ 344 MmedAudPwrMod 0 "MmedAudPwrMod_Off" 1 "MmedAudPwrMod_Partial" 2 "MmedAudPwrMod_Full";
VAL_ 849 EngSt1WdStsEngSt1WdSts 0 "EngSt1_Ini" 1 "EngSt1_Awake" 2 "EngSt1_Rdy" 3 "EngSt1_PreStrtg" 4 "EngSt1_StrtgInProgs" 5 "EngSt1_RunngRunng" 6 "EngSt1_RunngStb" 7 "EngSt1_RunngStrtgInProgs" 8 "EngSt1_RunngRemStrtd" 9 "EngSt1_AftRun";
VAL_ 849 VehModMngtGlbSafe1CarModSts1 0 "CarModSts1_CarModNorm" 1 "CarModSts1_CarModTrnsp" 2 "CarModSts1_CarModFcy" 3 "CarModSts1_CarModCrash" 5 "CarModSts1_CarModDyno";
VAL_ 849 VehModMngtGlbSafe1FltEgyCnsWdSts 0 "FltEgyCns1_NoFlt" 1 "FltEgyCns1_Flt";
VAL_ 849 VehModMngtGlbSafe1UsgModSts 0 "UsgModSts1_UsgModAbdnd" 1 "UsgModSts1_UsgModInActv" 2 "UsgModSts1_UsgModCnvinc" 11 "UsgModSts1_UsgModActv" 13 "UsgModSts1_UsgModDrvg";
VAL_ 32 AmbTIndcdWithUnitAmbTIndcdUnit 0 "AmbTIndcdUnit_Celsius" 1 "AmbTIndcdUnit_Fahrenheit" 2 "AmbTIndcdUnit_UkwnUnit";
VAL_ 32 AmbTIndcdWithUnitQF 0 "GenQf1_UndefindDataAccur" 1 "GenQf1_TmpUndefdData" 2 "GenQf1_DataAccurNotWithinSpcn" 3 "GenQf1_AccurData";
VAL_ 32 MmedAudCurrLim 0 "MmedAudCurrLim_Off" 1 "MmedAudCurrLim_Level1" 2 "MmedAudCurrLim_Level2" 3 "MmedAudCurrLim_Level3";
VAL_ 32 VehSpdLgtQf 0 "GenQf1_UndefindDataAccur" 1 "GenQf1_TmpUndefdData" 2 "GenQf1_DataAccurNotWithinSpcn" 3 "GenQf1_AccurData";
VAL_ 7 IsgTqActQualityFactor 0 "QualityFactor_QfUndefd" 1 "QualityFactor_QfInProgs" 2 "QualityFactor_QfNotSpc" 3 "QualityFactor_QfSnsrDataOk";
VAL_ 7 PtGearAct 0 "PtGearAct1_Neut" 1 "PtGearAct1_Gear1" 2 "PtGearAct1_Gear2" 3 "PtGearAct1_Gear3" 4 "PtGearAct1_Gear4" 5 "PtGearAct1_Gear5" 6 "PtGearAct1_Gear6" 7 "PtGearAct1_Gear7" 8 "PtGearAct1_Gear8" 9 "PtGearAct1_Gear9" 10 "PtGearAct1_Gear10" 11 "PtGearAct1_Gear11" 12 "PtGearAct1_Gear12" 13 "PtGearAct1_Drv" 14 "PtGearAct1_Ukwn" 15 "PtGearAct1_Rvs";
VAL_ 7 WinPosnStsAtDrvr 0 "WinAndRoofAndCurtPosnTyp_PosnUkwn" 1 "WinAndRoofAndCurtPosnTyp_ClsFull" 2 "WinAndRoofAndCurtPosnTyp_PercOpen4" 3 "WinAndRoofAndCurtPosnTyp_PercOpen8" 4 "WinAndRoofAndCurtPosnTyp_PercOpen12" 5 "WinAndRoofAndCurtPosnTyp_PercOpen16" 6 "WinAndRoofAndCurtPosnTyp_PercOpen20" 7 "WinAndRoofAndCurtPosnTyp_PercOpen24" 8 "WinAndRoofAndCurtPosnTyp_PercOpen28" 9 "WinAndRoofAndCurtPosnTyp_PercOpen32" 10 "WinAndRoofAndCurtPosnTyp_PercOpen36" 11 "WinAndRoofAndCurtPosnTyp_PercOpen40" 12 "WinAndRoofAndCurtPosnTyp_PercOpen44" 13 "WinAndRoofAndCurtPosnTyp_PercOpen48" 14 "WinAndRoofAndCurtPosnTyp_PercOpen52" 15 "WinAndRoofAndCurtPosnTyp_PercOpen56" 16 "WinAndRoofAndCurtPosnTyp_PercOpen60" 17 "WinAndRoofAndCurtPosnTyp_PercOpen64" 18 "WinAndRoofAndCurtPosnTyp_PercOpen68" 19 "WinAndRoofAndCurtPosnTyp_PercOpen72" 20 "WinAndRoofAndCurtPosnTyp_PercOpen76" 21 "WinAndRoofAndCurtPosnTyp_PercOpen80" 22 "WinAndRoofAndCurtPosnTyp_PercOpen84" 23 "WinAndRoofAndCurtPosnTyp_PercOpen88" 24 "WinAndRoofAndCurtPosnTyp_PercOpen92" 25 "WinAndRoofAndCurtPosnTyp_PercOpen96" 26 "WinAndRoofAndCurtPosnTyp_OpenFull" 27 "WinAndRoofAndCurtPosnTyp_Resd1" 28 "WinAndRoofAndCurtPosnTyp_Resd2" 29 "WinAndRoofAndCurtPosnTyp_Resd3" 30 "WinAndRoofAndCurtPosnTyp_Resd4" 31 "WinAndRoofAndCurtPosnTyp_Movg";
VAL_ 7 WinPosnStsAtPass 0 "WinAndRoofAndCurtPosnTyp_PosnUkwn" 1 "WinAndRoofAndCurtPosnTyp_ClsFull" 2 "WinAndRoofAndCurtPosnTyp_PercOpen4" 3 "WinAndRoofAndCurtPosnTyp_PercOpen8" 4 "WinAndRoofAndCurtPosnTyp_PercOpen12" 5 "WinAndRoofAndCurtPosnTyp_PercOpen16" 6 "WinAndRoofAndCurtPosnTyp_PercOpen20" 7 "WinAndRoofAndCurtPosnTyp_PercOpen24" 8 "WinAndRoofAndCurtPosnTyp_PercOpen28" 9 "WinAndRoofAndCurtPosnTyp_PercOpen32" 10 "WinAndRoofAndCurtPosnTyp_PercOpen36" 11 "WinAndRoofAndCurtPosnTyp_PercOpen40" 12 "WinAndRoofAndCurtPosnTyp_PercOpen44" 13 "WinAndRoofAndCurtPosnTyp_PercOpen48" 14 "WinAndRoofAndCurtPosnTyp_PercOpen52" 15 "WinAndRoofAndCurtPosnTyp_PercOpen56" 16 "WinAndRoofAndCurtPosnTyp_PercOpen60" 17 "WinAndRoofAndCurtPosnTyp_PercOpen64" 18 "WinAndRoofAndCurtPosnTyp_PercOpen68" 19 "WinAndRoofAndCurtPosnTyp_PercOpen72" 20 "WinAndRoofAndCurtPosnTyp_PercOpen76" 21 "WinAndRoofAndCurtPosnTyp_PercOpen80" 22 "WinAndRoofAndCurtPosnTyp_PercOpen84" 23 "WinAndRoofAndCurtPosnTyp_PercOpen88" 24 "WinAndRoofAndCurtPosnTyp_PercOpen92" 25 "WinAndRoofAndCurtPosnTyp_PercOpen96" 26 "WinAndRoofAndCurtPosnTyp_OpenFull" 27 "WinAndRoofAndCurtPosnTyp_Resd1" 28 "WinAndRoofAndCurtPosnTyp_Resd2" 29 "WinAndRoofAndCurtPosnTyp_Resd3" 30 "WinAndRoofAndCurtPosnTyp_Resd4" 31 "WinAndRoofAndCurtPosnTyp_Movg";
VAL_ 7 WinPosnStsAtReLe 0 "WinAndRoofAndCurtPosnTyp_PosnUkwn" 1 "WinAndRoofAndCurtPosnTyp_ClsFull" 2 "WinAndRoofAndCurtPosnTyp_PercOpen4" 3 "WinAndRoofAndCurtPosnTyp_PercOpen8" 4 "WinAndRoofAndCurtPosnTyp_PercOpen12" 5 "WinAndRoofAndCurtPosnTyp_PercOpen16" 6 "WinAndRoofAndCurtPosnTyp_PercOpen20" 7 "WinAndRoofAndCurtPosnTyp_PercOpen24" 8 "WinAndRoofAndCurtPosnTyp_PercOpen28" 9 "WinAndRoofAndCurtPosnTyp_PercOpen32" 10 "WinAndRoofAndCurtPosnTyp_PercOpen36" 11 "WinAndRoofAndCurtPosnTyp_PercOpen40" 12 "WinAndRoofAndCurtPosnTyp_PercOpen44" 13 "WinAndRoofAndCurtPosnTyp_PercOpen48" 14 "WinAndRoofAndCurtPosnTyp_PercOpen52" 15 "WinAndRoofAndCurtPosnTyp_PercOpen56" 16 "WinAndRoofAndCurtPosnTyp_PercOpen60" 17 "WinAndRoofAndCurtPosnTyp_PercOpen64" 18 "WinAndRoofAndCurtPosnTyp_PercOpen68" 19 "WinAndRoofAndCurtPosnTyp_PercOpen72" 20 "WinAndRoofAndCurtPosnTyp_PercOpen76" 21 "WinAndRoofAndCurtPosnTyp_PercOpen80" 22 "WinAndRoofAndCurtPosnTyp_PercOpen84" 23 "WinAndRoofAndCurtPosnTyp_PercOpen88" 24 "WinAndRoofAndCurtPosnTyp_PercOpen92" 25 "WinAndRoofAndCurtPosnTyp_PercOpen96" 26 "WinAndRoofAndCurtPosnTyp_OpenFull" 27 "WinAndRoofAndCurtPosnTyp_Resd1" 28 "WinAndRoofAndCurtPosnTyp_Resd2" 29 "WinAndRoofAndCurtPosnTyp_Resd3" 30 "WinAndRoofAndCurtPosnTyp_Resd4" 31 "WinAndRoofAndCurtPosnTyp_Movg";
VAL_ 7 WinPosnStsAtReRi 0 "WinAndRoofAndCurtPosnTyp_PosnUkwn" 1 "WinAndRoofAndCurtPosnTyp_ClsFull" 2 "WinAndRoofAndCurtPosnTyp_PercOpen4" 3 "WinAndRoofAndCurtPosnTyp_PercOpen8" 4 "WinAndRoofAndCurtPosnTyp_PercOpen12" 5 "WinAndRoofAndCurtPosnTyp_PercOpen16" 6 "WinAndRoofAndCurtPosnTyp_PercOpen20" 7 "WinAndRoofAndCurtPosnTyp_PercOpen24" 8 "WinAndRoofAndCurtPosnTyp_PercOpen28" 9 "WinAndRoofAndCurtPosnTyp_PercOpen32" 10 "WinAndRoofAndCurtPosnTyp_PercOpen36" 11 "WinAndRoofAndCurtPosnTyp_PercOpen40" 12 "WinAndRoofAndCurtPosnTyp_PercOpen44" 13 "WinAndRoofAndCurtPosnTyp_PercOpen48" 14 "WinAndRoofAndCurtPosnTyp_PercOpen52" 15 "WinAndRoofAndCurtPosnTyp_PercOpen56" 16 "WinAndRoofAndCurtPosnTyp_PercOpen60" 17 "WinAndRoofAndCurtPosnTyp_PercOpen64" 18 "WinAndRoofAndCurtPosnTyp_PercOpen68" 19 "WinAndRoofAndCurtPosnTyp_PercOpen72" 20 "WinAndRoofAndCurtPosnTyp_PercOpen76" 21 "WinAndRoofAndCurtPosnTyp_PercOpen80" 22 "WinAndRoofAndCurtPosnTyp_PercOpen84" 23 "WinAndRoofAndCurtPosnTyp_PercOpen88" 24 "WinAndRoofAndCurtPosnTyp_PercOpen92" 25 "WinAndRoofAndCurtPosnTyp_PercOpen96" 26 "WinAndRoofAndCurtPosnTyp_OpenFull" 27 "WinAndRoofAndCurtPosnTyp_Resd1" 28 "WinAndRoofAndCurtPosnTyp_Resd2" 29 "WinAndRoofAndCurtPosnTyp_Resd3" 30 "WinAndRoofAndCurtPosnTyp_Resd4" 31 "WinAndRoofAndCurtPosnTyp_Movg";
VAL_ 11 GearLvrIndcn 0 "GearLvrIndcn2_ParkIndcn" 1 "GearLvrIndcn2_RvsIndcn" 2 "GearLvrIndcn2_NeutIndcn" 3 "GearLvrIndcn2_DrvIndcn" 4 "GearLvrIndcn2_ManModeIndcn" 5 "GearLvrIndcn2_Resd1" 6 "GearLvrIndcn2_Resd2" 7 "GearLvrIndcn2_Undefd";
VAL_ 11 SunRoofPosnSts 0 "WinAndRoofAndCurtPosnTyp_PosnUkwn" 1 "WinAndRoofAndCurtPosnTyp_ClsFull" 2 "WinAndRoofAndCurtPosnTyp_PercOpen4" 3 "WinAndRoofAndCurtPosnTyp_PercOpen8" 4 "WinAndRoofAndCurtPosnTyp_PercOpen12" 5 "WinAndRoofAndCurtPosnTyp_PercOpen16" 6 "WinAndRoofAndCurtPosnTyp_PercOpen20" 7 "WinAndRoofAndCurtPosnTyp_PercOpen24" 8 "WinAndRoofAndCurtPosnTyp_PercOpen28" 9 "WinAndRoofAndCurtPosnTyp_PercOpen32" 10 "WinAndRoofAndCurtPosnTyp_PercOpen36" 11 "WinAndRoofAndCurtPosnTyp_PercOpen40" 12 "WinAndRoofAndCurtPosnTyp_PercOpen44" 13 "WinAndRoofAndCurtPosnTyp_PercOpen48" 14 "WinAndRoofAndCurtPosnTyp_PercOpen52" 15 "WinAndRoofAndCurtPosnTyp_PercOpen56" 16 "WinAndRoofAndCurtPosnTyp_PercOpen60" 17 "WinAndRoofAndCurtPosnTyp_PercOpen64" 18 "WinAndRoofAndCurtPosnTyp_PercOpen68" 19 "WinAndRoofAndCurtPosnTyp_PercOpen72" 20 "WinAndRoofAndCurtPosnTyp_PercOpen76" 21 "WinAndRoofAndCurtPosnTyp_PercOpen80" 22 "WinAndRoofAndCurtPosnTyp_PercOpen84" 23 "WinAndRoofAndCurtPosnTyp_PercOpen88" 24 "WinAndRoofAndCurtPosnTyp_PercOpen92" 25 "WinAndRoofAndCurtPosnTyp_PercOpen96" 26 "WinAndRoofAndCurtPosnTyp_OpenFull" 27 "WinAndRoofAndCurtPosnTyp_Resd1" 28 "WinAndRoofAndCurtPosnTyp_Resd2" 29 "WinAndRoofAndCurtPosnTyp_Resd3" 30 "WinAndRoofAndCurtPosnTyp_Resd4" 31 "WinAndRoofAndCurtPosnTyp_Movg";
VAL_ 37 AccrPedlPsdAccrPedlPsd 0 "NoYes1_No" 1 "NoYes1_Yes";
VAL_ 37 AccrPedlPsdSts 0 "NoYes1_No" 1 "NoYes1_Yes";
VAL_ 37 HoodSts 0 "DoorSts2_Ukwn" 1 "DoorSts2_Opend" 2 "DoorSts2_Clsd";
VAL_ 41 DoorDrvrSts 0 "DoorSts2_Ukwn" 1 "DoorSts2_Opend" 2 "DoorSts2_Clsd";
VAL_ 41 DoorLeReSts 0 "DoorSts2_Ukwn" 1 "DoorSts2_Opend" 2 "DoorSts2_Clsd";
VAL_ 41 DoorPassSts 0 "DoorSts2_Ukwn" 1 "DoorSts2_Opend" 2 "DoorSts2_Clsd";
VAL_ 41 DoorRiReSts 0 "DoorSts2_Ukwn" 1 "DoorSts2_Opend" 2 "DoorSts2_Clsd";
VAL_ 41 OverBoostSts 0 "NotActvActv1_NotActv" 1 "NotActvActv1_Actv";
VAL_ 41 TrSts 0 "DoorSts2_Ukwn" 1 "DoorSts2_Opend" 2 "DoorSts2_Clsd";
VAL_ 41 WhlSpdCircumlReLeQf 0 "GenQf1_UndefindDataAccur" 1 "GenQf1_TmpUndefdData" 2 "GenQf1_DataAccurNotWithinSpcn" 3 "GenQf1_AccurData";
VAL_ 41 WhlSpdCircumlReRiQf 0 "GenQf1_UndefindDataAccur" 1 "GenQf1_TmpUndefdData" 2 "GenQf1_DataAccurNotWithinSpcn" 3 "GenQf1_AccurData";
VAL_ 341 AmbTRawQly 0 "GenQf1_UndefindDataAccur" 1 "GenQf1_TmpUndefdData" 2 "GenQf1_DataAccurNotWithinSpcn" 3 "GenQf1_AccurData";
VAL_ 314 CmptmtTFrntFanForCmptmtTRunng 0 "Flg1_Rst" 1 "Flg1_Set";
VAL_ 314 CmptmtTFrntQf 0 "CmptmtTFrntQf_SnsrDataUndefd" 1 "CmptmtTFrntQf_FanNotRunning" 2 "CmptmtTFrntQf_SnsrDataNotOk" 3 "CmptmtTFrntQf_SnsrDataOk";
VAL_ 314 DoorDrvrHndlSts 0 "DoorHndlSts_Ukwn" 1 "DoorHndlSts_FullRtrctd" 2 "DoorHndlSts_MovgOut" 3 "DoorHndlSts_StopDurgDply" 4 "DoorHndlSts_FullDplyd" 5 "DoorHndlSts_MovgIn" 6 "DoorHndlSts_StopDurgRtrct" 7 "DoorHndlSts_Flt";
VAL_ 314 DoorLeReHndlSts 0 "DoorHndlSts_Ukwn" 1 "DoorHndlSts_FullRtrctd" 2 "DoorHndlSts_MovgOut" 3 "DoorHndlSts_StopDurgDply" 4 "DoorHndlSts_FullDplyd" 5 "DoorHndlSts_MovgIn" 6 "DoorHndlSts_StopDurgRtrct" 7 "DoorHndlSts_Flt";
VAL_ 314 DoorRiReHndlSts 0 "DoorHndlSts_Ukwn" 1 "DoorHndlSts_FullRtrctd" 2 "DoorHndlSts_MovgOut" 3 "DoorHndlSts_StopDurgDply" 4 "DoorHndlSts_FullDplyd" 5 "DoorHndlSts_MovgIn" 6 "DoorHndlSts_StopDurgRtrct" 7 "DoorHndlSts_Flt";
VAL_ 314 TrOpenerSts 0 "TrOpenerSts1_Ukwn" 1 "TrOpenerSts1_FullClsd" 2 "TrOpenerSts1_MovgUp" 3 "TrOpenerSts1_MovgUpBrkg" 4 "TrOpenerSts1_StopDurgOpen" 5 "TrOpenerSts1_FullOpend" 6 "TrOpenerSts1_MovgDwn" 7 "TrOpenerSts1_MovgDwnBrkg" 8 "TrOpenerSts1_StopDurgCls" 9 "TrOpenerSts1_HalfClsd" 10 "TrOpenerSts1_StopMinPntForCls";
VAL_ 85 SteerWhlSnsrQf 0 "GenQf1_UndefindDataAccur" 1 "GenQf1_TmpUndefdData" 2 "GenQf1_DataAccurNotWithinSpcn" 3 "GenQf1_AccurData";
VAL_ 257 BrkPedlPsdBrkPedlNotPsdSafe 0 "NoYes1_No" 1 "NoYes1_Yes";
VAL_ 257 BrkPedlPsdBrkPedlPsd 0 "NoYes1_No" 1 "NoYes1_Yes";
VAL_ 257 BrkPedlPsdQf 0 "GenQf1_UndefindDataAccur" 1 "GenQf1_TmpUndefdData" 2 "GenQf1_DataAccurNotWithinSpcn" 3 "GenQf1_AccurData";
VAL_ 257 WhlSpdCircumlFrntLeQf 0 "GenQf1_UndefindDataAccur" 1 "GenQf1_TmpUndefdData" 2 "GenQf1_DataAccurNotWithinSpcn" 3 "GenQf1_AccurData";
VAL_ 257 WhlSpdCircumlFrntRiQf 0 "GenQf1_UndefindDataAccur" 1 "GenQf1_TmpUndefdData" 2 "GenQf1_DataAccurNotWithinSpcn" 3 "GenQf1_AccurData";
VAL_ 362 ProfPenSts1 0 "IdPen_ProfUkwn" 1 "IdPen_Prof1" 2 "IdPen_Prof2" 3 "IdPen_Prof3" 4 "IdPen_Prof4" 5 "IdPen_Prof5" 6 "IdPen_Prof6" 7 "IdPen_Prof7" 8 "IdPen_Prof8" 9 "IdPen_Prof9" 10 "IdPen_Prof10" 11 "IdPen_Prof11" 12 "IdPen_Prof12" 13 "IdPen_Prof13" 14 "IdPen_Resd14" 15 "IdPen_ProfAll";
VAL_ 362 RoadInclnQly 0 "Qly2_Flt" 1 "Qly2_NoInfo" 2 "Qly2_Vld";
VAL_ 362 VehBattUSysUQf 0 "GenQf1_UndefindDataAccur" 1 "GenQf1_TmpUndefdData" 2 "GenQf1_DataAccurNotWithinSpcn" 3 "GenQf1_AccurData";
VAL_ 362 VehMtnStVehMtnSt 0 "VehMtnSt2_Ukwn" 1 "VehMtnSt2_StandStillVal1" 2 "VehMtnSt2_StandStillVal2" 3 "VehMtnSt2_StandStillVal3" 4 "VehMtnSt2_RollgFwdVal1" 5 "VehMtnSt2_RollgFwdVal2" 6 "VehMtnSt2_RollgBackwVal1" 7 "VehMtnSt2_RollgBackwVal2";
VAL_ 848 AcoustEfectPrvtCinePsn 0 "NoYesCrit1_NotVld1" 1 "NoYesCrit1_No" 2 "NoYesCrit1_Yes" 3 "NoYesCrit1_NotVld2";
VAL_ 848 Audio2Mute 0 "Unmute" 1 "mute";
VAL_ 848 CrashStsSafeSts 0 "CrashSts2_NoCrash" 1 "CrashSts2_Crash";
VAL_ 848 RecOfImpctCrashFrnt 0 "Boolean_FALSE" 1 "Boolean_TRUE";
VAL_ 848 RecOfImpctCrashOffroadA 0 "Boolean_FALSE" 1 "Boolean_TRUE";
VAL_ 848 RecOfImpctCrashOffroadD 0 "Boolean_FALSE" 1 "Boolean_TRUE";
VAL_ 848 RecOfImpctCrashOffroadRT 0 "Boolean_FALSE" 1 "Boolean_TRUE";
VAL_ 848 RecOfImpctCrashOffroadRTsevere 0 "Boolean_FALSE" 1 "Boolean_TRUE";
VAL_ 848 RecOfImpctCrashPed 0 "Boolean_FALSE" 1 "Boolean_TRUE";
VAL_ 848 RecOfImpctCrashRe 0 "Boolean_FALSE" 1 "Boolean_TRUE";
VAL_ 848 RecOfImpctCrashRollovr 0 "Boolean_FALSE" 1 "Boolean_TRUE";
VAL_ 848 RecOfImpctCrashSideLe 0 "Boolean_FALSE" 1 "Boolean_TRUE";
VAL_ 848 RecOfImpctCrashSideRi 0 "Boolean_FALSE" 1 "Boolean_TRUE";
VAL_ 848 RecOfImpctCrashState 0 "CrashSt_NoCrash" 1 "CrashSt_CrashImminent" 2 "CrashSt_CrashInProgress" 3 "CrashSt_CrashEnding";
VAL_ 848 RecOfImpctVehOri 0 "Orntn_OnWheels" 1 "Orntn_LeftSide" 2 "Orntn_RightSide" 3 "Orntn_OnRoof" 4 "Orntn_Indeterminate" 5 "Orntn_Resd1" 6 "Orntn_Resd2" 7 "Orntn_Resd3";
VAL_ 325 PDCMDTCsClr 0 "Boolean_FALSE" 1 "Boolean_TRUE";
VAL_ 672 PassSeatSnsrSts2 0 "OkNokDi_Ok" 1 "OkNokDi_NotOk" 2 "OkNokDi_Disabled" 3 "OkNokDi_Reserved";
VAL_ 672 PassSeatSts2 0 "OccptPresSt1_Undefd1" 1 "OccptPresSt1_OccptNotPrsnt" 2 "OccptPresSt1_OccptPrsnt" 3 "OccptPresSt1_Undefd2";
VAL_ 672 SeatOccptAtRowSecDrSide2 0 "OccptPresSt1_Undefd1" 1 "OccptPresSt1_OccptNotPrsnt" 2 "OccptPresSt1_OccptPrsnt" 3 "OccptPresSt1_Undefd2";
VAL_ 672 SeatOccptAtRowSecDrSideSnsSts2 0 "OkNokDi_Ok" 1 "OkNokDi_NotOk" 2 "OkNokDi_Disabled" 3 "OkNokDi_Reserved";
VAL_ 672 SeatOccptAtRowSecMid2 0 "OccptPresSt1_Undefd1" 1 "OccptPresSt1_OccptNotPrsnt" 2 "OccptPresSt1_OccptPrsnt" 3 "OccptPresSt1_Undefd2";
VAL_ 672 SeatOccptAtRowSecMidSnsSts2 0 "OkNokDi_Ok" 1 "OkNokDi_NotOk" 2 "OkNokDi_Disabled" 3 "OkNokDi_Reserved";
VAL_ 672 SeatOccptAtRowSecPasSide2 0 "OccptPresSt1_Undefd1" 1 "OccptPresSt1_OccptNotPrsnt" 2 "OccptPresSt1_OccptPrsnt" 3 "OccptPresSt1_Undefd2";
VAL_ 672 SeatOccptAtRowSecPasSideSnsSts2 0 "OkNokDi_Ok" 1 "OkNokDi_NotOk" 2 "OkNokDi_Disabled" 3 "OkNokDi_Reserved";
VAL_ 1281 WakeUpReasonsforDHU 0 "WakeupReasons_667949" 1 "WakeupReasons_667950" 2 "WakeupReasons_169654" 3 "WakeupReasons_667951" 4 "WakeupReasons_168965" 5 "WakeupReasons_197643" 6 "WakeupReasons_264933" 7 "WakeupReasons_45654" 8 "WakeupReasons_22058" 9 "WakeupReasons_49446" 10 "WakeupReasons_22060" 11 "WakeupReasons_269740" 12 "WakeupReasons_269735" 13 "WakeupReasons_269739" 14 "WakeupReasons_658500" 15 "WakeupReasons_21901" 16 "WakeupReasons_45793" 17 "WakeupReasons_45794" 18 "WakeupReasons_22005" 19 "WakeupReasons_22013" 20 "WakeupReasons_22100" 21 "WakeupReasons_45659" 22 "WakeupReasons_45657" 23 "WakeupReasons_140084" 24 "WakeupReasons_21973" 25 "WakeupReasons_91253" 26 "WakeupReasons_88123" 27 "WakeupReasons_88125" 28 "WakeupReasons_321583" 29 "WakeupReasons_74188" 30 "WakeupReasons_667945" 31 "WakeupReasons_169655" 32 "WakeupReasons_667948" 33 "WakeupReasons_168966" 34 "WakeupReasons_170865" 35 "WakeupReasons_197642" 36 "WakeupReasons_264876" 37 "WakeupReasons_191050" 38 "WakeupReasons_182033" 39 "WakeupReasons_200937" 40 "WakeupReasons_170807" 41 "WakeupReasons_319139" 42 "WakeupReasons_100298" 43 "WakeupReasons_100275" 44 "WakeupReasons_100300" 45 "WakeupReasons_100278" 46 "WakeupReasons_100281" 47 "WakeupReasons_265333" 48 "WakeupReasons_108776" 49 "WakeupReasons_176921" 50 "WakeupReasons_197826" 51 "WakeupReasons_185670" 52 "WakeupReasons_161066" 53 "WakeupReasons_200156" 54 "WakeupReasons_225696" 55 "WakeupReasons_21997" 56 "WakeupReasons_45656" 57 "WakeupReasons_266860" 58 "WakeupReasons_169894" 59 "WakeupReasons_320282" 60 "WakeupReasons_319422" 61 "WakeupReasons_320277" 62 "WakeupReasons_355601" 63 "WakeupReasons_360904" 64 "WakeupReasons_361505" 65 "WakeupReasons_361509" 66 "WakeupReasons_645094" 67 "WakeupReasons_68676" 68 "WakeupReasons_360008" 69 "WakeupReasons_109382" 70 "WakeupReasons_119273" 71 "WakeupReasons_224065" 72 "WakeupReasons_68644" 73 "WakeupReasons_109364" 74 "WakeupReasons_68481" 75 "WakeupReasons_224061" 76 "WakeupReasons_360006" 77 "WakeupReasons_138997" 78 "WakeupReasons_634696" 79 "WakeupReasons_645810" 80 "WakeupReasons_297868" 81 "WakeupReasons_315364" 82 "WakeupReasons_109367" 83 "WakeupReasons_320126" 84 "WakeupReasons_109387" 85 "WakeupReasons_634710" 86 "WakeupReasons_338820" 87 "WakeupReasons_67182" 88 "WakeupReasons_152237" 89 "WakeupReasons_145707" 90 "WakeupReasons_199172" 91 "WakeupReasons_144897" 92 "WakeupReasons_186489" 93 "WakeupReasons_144970" 94 "WakeupReasons_152786" 95 "WakeupReasons_264932" 96 "WakeupReasons_264934" 97 "WakeupReasons_356190" 98 "WakeupReasons_145688" 99 "WakeupReasons_95444" 100 "WakeupReasons_169945" 101 "WakeupReasons_140678" 102 "WakeupReasons_222553" 103 "WakeupReasons_224831" 104 "WakeupReasons_201815" 105 "WakeupReasons_45864" 106 "WakeupReasons_659549" 107 "WakeupReasons_45866" 108 "WakeupReasons_45867" 109 "WakeupReasons_169884" 110 "WakeupReasons_264962" 111 "WakeupReasons_201348" 112 "WakeupReasons_320287" 113 "WakeupReasons_156412" 114 "WakeupReasons_133749" 115 "WakeupReasons_355409" 116 "WakeupReasons_636692" 117 "WakeupReasons_533044" 118 "WakeupReasons_106774" 119 "WakeupReasons_145311" 120 "WakeupReasons_145319" 121 "WakeupReasons_152774" 122 "WakeupReasons_145330" 123 "WakeupReasons_145388" 124 "WakeupReasons_145399" 125 "WakeupReasons_145362" 126 "WakeupReasons_145385" 127 "WakeupReasons_145373" 128 "WakeupReasons_145288" 129 "WakeupReasons_145419" 130 "WakeupReasons_145454" 131 "WakeupReasons_145462" 132 "WakeupReasons_269156" 133 "WakeupReasons_300427" 134 "WakeupReasons_220322" 135 "WakeupReasons_224617" 136 "WakeupReasons_224634" 137 "WakeupReasons_300682" 138 "WakeupReasons_264958" 139 "WakeupReasons_160597" 140 "WakeupReasons_160602" 141 "WakeupReasons_108841" 142 "WakeupReasons_265569" 143 "WakeupReasons_526429" 144 "WakeupReasons_514545" 145 "WakeupReasons_265232" 146 "WakeupReasons_644550" 147 "WakeupReasons_317616" 148 "WakeupReasons_354791" 149 "WakeupReasons_320631" 150 "WakeupReasons_337565" 151 "WakeupReasons_532007" 152 "WakeupReasons_514503" 153 "WakeupReasons_299117" 154 "WakeupReasons_340667" 155 "WakeupReasons_321845" 156 "WakeupReasons_179103" 157 "WakeupReasons_108810" 158 "WakeupReasons_322857" 159 "WakeupReasons_658603" 160 "WakeupReasons_197648" 161 "WakeupReasons_160596" 162 "WakeupReasons_361272" 163 "WakeupReasons_361279" 164 "WakeupReasons_265305" 165 "WakeupReasons_265328" 166 "WakeupReasons_265330" 167 "WakeupReasons_298808" 168 "WakeupReasons_515804" 169 "WakeupReasons_514502" 170 "WakeupReasons_645753" 171 "WakeupReasons_646109" 172 "WakeupReasons_299547" 173 "WakeupReasons_318342" 174 "WakeupReasons_360543" 175 "WakeupReasons_356549" 176 "WakeupReasons_198484" 177 "WakeupReasons_300681" 178 "WakeupReasons_359211" 179 "WakeupReasons_534077" 180 "WakeupReasons_525705" 181 "WakeupReasons_360299" 182 "WakeupReasons_526445" 183 "WakeupReasons_534145" 184 "WakeupReasons_192030" 185 "WakeupReasons_652361" 186 "WakeupReasons_355214" 187 "WakeupReasons_321317" 188 "WakeupReasons_359187" 189 "WakeupReasons_321057" 190 "WakeupReasons_321319" 191 "WakeupReasons_321323" 192 "WakeupReasons_321077" 193 "WakeupReasons_320895" 194 "WakeupReasons_655340" 195 "WakeupReasons_636556" 196 "WakeupReasons_108834" 197 "WakeupReasons_265937" 198 "WakeupReasons_533050" 199 "WakeupReasons_526426" 200 "WakeupReasons_264712" 201 "WakeupReasons_319401" 202 "WakeupReasons_643973" 203 "WakeupReasons_223715" 204 "WakeupReasons_199159" 205 "WakeupReasons_318382" 206 "WakeupReasons_226967" 207 "WakeupReasons_531743" 208 "WakeupReasons_360542" 209 "WakeupReasons_264726" 210 "WakeupReasons_535214" 211 "WakeupReasons_335068" 212 "WakeupReasons_316796" 213 "WakeupReasons_526438" 214 "WakeupReasons_198433" 215 "WakeupReasons_225961" 216 "WakeupReasons_197665" 217 "WakeupReasons_224550" 218 "WakeupReasons_667962" 219 "WakeupReasons_667953" 220 "WakeupReasons_110885" 221 "WakeupReasons_224552" 222 "WakeupReasons_224553" 223 "WakeupReasons_652546" 224 "WakeupReasons_331194" 225 "WakeupReasons_667820" 226 "WakeupReasons_659350" 227 "WakeupReasons_101706" 228 "WakeupReasons_101725" 229 "WakeupReasons_101728" 230 "WakeupReasons_101727" 231 "WakeupReasons_166267" 232 "WakeupReasons_156440" 233 "WakeupReasons_95949" 234 "WakeupReasons_112799" 235 "WakeupReasons_146470" 236 "WakeupReasons_176748" 237 "WakeupReasons_223920" 238 "WakeupReasons_668531" 239 "WakeupReasons_670087" 240 "WakeupReasons_668529" 241 "WakeupReasons_45858" 242 "WakeupReasons_315981" 243 "WakeupReasons_533370" 244 "WakeupReasons_533371" 245 "WakeupReasons_533372" 246 "WakeupReasons_241902" 247 "WakeupReasons_359559" 248 "WakeupReasons_516327" 249 "WakeupReasons_533872" 250 "WakeupReasons_45856" 251 "WakeupReasons_45853" 252 "WakeupReasons_45854" 253 "WakeupReasons_45852" 254 "WakeupReasons_45851" 255 "WakeupReasons_45850" 256 "WakeupReasons_45849" 257 "WakeupReasons_636801" 258 "WakeupReasons_109466" 259 "WakeupReasons_109467" 260 "WakeupReasons_670345" 261 "WakeupReasons_NMPDUReceived" 262 "WakeupReasons_358832" 263 "WakeupReasons_200683" 264 "WakeupReasons_198452" 265 "WakeupReasons_185457" 266 "WakeupReasons_185490" 267 "WakeupReasons_4471" 268 "WakeupReasons_269034" 269 "WakeupReasons_215560" 270 "WakeupReasons_312881" 271 "WakeupReasons_269140" 272 "WakeupReasons_197653" 273 "WakeupReasons_337991" 274 "WakeupReasons_658188" 275 "WakeupReasons_674953" 276 "WakeupReasons_675064" 277 "WakeupReasons_674958" 278 "WakeupReasons_675494" 279 "WakeupReasons_675837" 280 "WakeupReasons_667879" 281 "WakeupReasons_667947" 282 "WakeupReasons_676265" 283 "WakeupReasons_669465" 284 "WakeupReasons_670928" 285 "WakeupReasons_669447" 286 "WakeupReasons_667922" 287 "WakeupReasons_670753" 288 "WakeupReasons_668395" 289 "WakeupReasons_668393" 290 "WakeupReasons_667850" 291 "WakeupReasons_667848" 292 "WakeupReasons_311279" 293 "WakeupReasons_182918" 294 "WakeupReasons_667988" 295 "WakeupReasons_532555" 296 "WakeupReasons_532556" 297 "WakeupReasons_113348" 298 "WakeupReasons_193474" 299 "WakeupReasons_667871" 300 "WakeupReasons_670966" 301 "WakeupReasons_667985" 302 "WakeupReasons_670354" 303 "WakeupReasons_46017" 304 "WakeupReasons_675742" 305 "WakeupReasons_106669" 306 "WakeupReasons_80609" 307 "WakeupReasons_199714" 308 "WakeupReasons_200090" 309 "WakeupReasons_139075" 310 "WakeupReasons_268983" 311 "WakeupReasons_265131" 312 "WakeupReasons_263473" 313 "WakeupReasons_45887" 314 "WakeupReasons_69678" 315 "WakeupReasons_69679" 316 "WakeupReasons_45897" 317 "WakeupReasons_45898" 318 "WakeupReasons_80608" 319 "WakeupReasons_45869" 320 "WakeupReasons_45870" 321 "WakeupReasons_45872" 322 "WakeupReasons_45875" 323 "WakeupReasons_45871" 324 "WakeupReasons_45876" 325 "WakeupReasons_667980" 326 "WakeupReasons_45877" 327 "WakeupReasons_667973" 328 "WakeupReasons_670962" 329 "WakeupReasons_45888" 330 "WakeupReasons_45890" 331 "WakeupReasons_667869" 332 "WakeupReasons_45846" 333 "WakeupReasons_45847" 334 "WakeupReasons_45848" 335 "WakeupReasons_262872" 336 "WakeupReasons_127924" 337 "WakeupReasons_127926" 338 "WakeupReasons_674223" 339 "WakeupReasons_667982" 340 "WakeupReasons_657121" 341 "WakeupReasons_265745" 342 "WakeupReasons_657120" 343 "WakeupReasons_675564" 344 "WakeupReasons_197644" 345 "WakeupReasons_264943" 346 "WakeupReasons_264697" 347 "WakeupReasons_69216" 348 "WakeupReasons_128671" 349 "WakeupReasons_356598" 350 "WakeupReasons_675745" 351 "WakeupReasons_667983" 352 "WakeupReasons_667987" 353 "WakeupReasons_75103" 354 "WakeupReasons_305818" 355 "WakeupReasons_670942" 356 "WakeupReasons_532932" 357 "WakeupReasons_532933" 358 "WakeupReasons_83199" 359 "WakeupReasons_45900" 360 "WakeupReasons_88458" 361 "WakeupReasons_329457" 362 "WakeupReasons_45902" 363 "WakeupReasons_224211" 364 "WakeupReasons_667981" 365 "WakeupReasons_667874" 366 "WakeupReasons_46020" 367 "WakeupReasons_667842" 368 "WakeupReasons_145161" 369 "WakeupReasons_233755" 370 "WakeupReasons_297056" 371 "WakeupReasons_264691" 372 "WakeupReasons_262871" 373 "WakeupReasons_264964" 374 "WakeupReasons_667872" 375 "WakeupReasons_45655" 376 "WakeupReasons_177214" 377 "WakeupReasons_671005" 378 "WakeupReasons_680712" 379 "WakeupReasons_669822" 380 "WakeupReasons_668523" 381 "WakeupReasons_680974" 382 "WakeupReasons_680975" 383 "WakeupReasons_681028" 384 "WakeupReasons_670462" 385 "WakeupReasons_681134" 386 "WakeupReasons_681031" 387 "WakeupReasons_681711" 388 "WakeupReasons_682034" 389 "WakeupReasons_674839" 390 "WakeupReasons_681915" 391 "WakeupReasons_682032" 392 "WakeupReasons_682037" 393 "WakeupReasons_682688" 394 "WakeupReasons_681789" 395 "WakeupReasons_682023" 396 "WakeupReasons_681023" 397 "WakeupReasons_676285" 398 "WakeupReasons_682077" 399 "WakeupReasons_682076" 400 "WakeupReasons_682078" 401 "WakeupReasons_682153" 402 "WakeupReasons_682155" 403 "WakeupReasons_682152" 404 "WakeupReasons_682154" 405 "WakeupReasons_682074";
VAL_ 640 InsdLeOfSnsrPrkgAssiRe1 0 "SnsrPrkgAssiFrntSnsrDstInsd_NoDistance" 1 "SnsrPrkgAssiFrntSnsrDstInsd_Range1" 2 "SnsrPrkgAssiFrntSnsrDstInsd_Range2" 3 "SnsrPrkgAssiFrntSnsrDstInsd_Range3" 4 "SnsrPrkgAssiFrntSnsrDstInsd_Range4" 5 "SnsrPrkgAssiFrntSnsrDstInsd_Range5" 6 "SnsrPrkgAssiFrntSnsrDstInsd_Range6" 7 "SnsrPrkgAssiFrntSnsrDstInsd_Range7";
VAL_ 640 InsdRiOfSnsrPrkgAssiRe1 0 "SnsrPrkgAssiFrntSnsrDstInsd_NoDistance" 1 "SnsrPrkgAssiFrntSnsrDstInsd_Range1" 2 "SnsrPrkgAssiFrntSnsrDstInsd_Range2" 3 "SnsrPrkgAssiFrntSnsrDstInsd_Range3" 4 "SnsrPrkgAssiFrntSnsrDstInsd_Range4" 5 "SnsrPrkgAssiFrntSnsrDstInsd_Range5" 6 "SnsrPrkgAssiFrntSnsrDstInsd_Range6" 7 "SnsrPrkgAssiFrntSnsrDstInsd_Range7";
VAL_ 640 ObjOnIfOfSnsr1 0 "ObjOnIfOfSnsr_Normal" 1 "ObjOnIfOfSnsr_FrontUSSCoverd" 2 "ObjOnIfOfSnsr_RearUSSCoverd" 3 "ObjOnIfOfSnsr_FrontAndRearUSSCoverd";
VAL_ 640 OutdLeOfSnsrPrkgAssiRe1 0 "SnsrPrkgAssiFrntSnsrDstInsd_NoDistance" 1 "SnsrPrkgAssiFrntSnsrDstInsd_Range1" 2 "SnsrPrkgAssiFrntSnsrDstInsd_Range2" 3 "SnsrPrkgAssiFrntSnsrDstInsd_Range3" 4 "SnsrPrkgAssiFrntSnsrDstInsd_Range4" 5 "SnsrPrkgAssiFrntSnsrDstInsd_Range5" 6 "SnsrPrkgAssiFrntSnsrDstInsd_Range6" 7 "SnsrPrkgAssiFrntSnsrDstInsd_Range7";
VAL_ 640 OutdRiOfSnsrPrkgAssiRe1 0 "SnsrPrkgAssiFrntSnsrDstInsd_NoDistance" 1 "SnsrPrkgAssiFrntSnsrDstInsd_Range1" 2 "SnsrPrkgAssiFrntSnsrDstInsd_Range2" 3 "SnsrPrkgAssiFrntSnsrDstInsd_Range3" 4 "SnsrPrkgAssiFrntSnsrDstInsd_Range4" 5 "SnsrPrkgAssiFrntSnsrDstInsd_Range5" 6 "SnsrPrkgAssiFrntSnsrDstInsd_Range6" 7 "SnsrPrkgAssiFrntSnsrDstInsd_Range7";
VAL_ 640 PdcMuteBtnSts1 0 "OnOff1_Off" 1 "OnOff1_On";
VAL_ 640 PrkgDstCtrlSts1 0 "PrkgDstCtrlSysSts_Off" 1 "PrkgDstCtrlSysSts_Standby" 2 "PrkgDstCtrlSysSts_FrontRearActive" 3 "PrkgDstCtrlSysSts_FrontActive" 4 "PrkgDstCtrlSysSts_RearActive" 5 "PrkgDstCtrlSysSts_SystemFailure" 6 "PrkgDstCtrlSysSts_Inhibited" 7 "PrkgDstCtrlSysSts_Initialize" 8 "PrkgDstCtrlSysSts_Covered" 9 "PrkgDstCtrlSysSts_FrontActiveTrailerMode" 10 "PrkgDstCtrlSysSts_Reserved1" 11 "PrkgDstCtrlSysSts_Reserved2" 12 "PrkgDstCtrlSysSts_Reserved3" 13 "PrkgDstCtrlSysSts_Reserved4" 14 "PrkgDstCtrlSysSts_Reserved5" 15 "PrkgDstCtrlSysSts_Reserved6";
VAL_ 640 SnsrFltOfPrkgDstCtrl1 0 "SnsrFltOfPrkgDstCtrl_Normal" 1 "SnsrFltOfPrkgDstCtrl_FrontUSSFault" 2 "SnsrFltOfPrkgDstCtrl_RearUSSFault" 3 "SnsrFltOfPrkgDstCtrl_FrontAndRearUSSFault";
VAL_ 519 AudWarnOfSnsrParkAssiFrnt1 0 "BuzzerReq_BuzzerOFF" 1 "BuzzerReq_BuzzerON" 2 "BuzzerReq_BuzzerONat4Hz" 3 "BuzzerReq_BuzzerONat2Hz" 4 "BuzzerReq_LeftON" 5 "BuzzerReq_LeftONat4Hz" 6 "BuzzerReq_LeftONat2Hz" 7 "BuzzerReq_RightON" 8 "BuzzerReq_RightONat4Hz" 9 "BuzzerReq_RightONat2Hz";
VAL_ 519 AudWarnOfSnsrParkAssiRe1 0 "BuzzerReq_BuzzerOFF" 1 "BuzzerReq_BuzzerON" 2 "BuzzerReq_BuzzerONat4Hz" 3 "BuzzerReq_BuzzerONat2Hz" 4 "BuzzerReq_LeftON" 5 "BuzzerReq_LeftONat4Hz" 6 "BuzzerReq_LeftONat2Hz" 7 "BuzzerReq_RightON" 8 "BuzzerReq_RightONat4Hz" 9 "BuzzerReq_RightONat2Hz";
VAL_ 519 PrkgDstCtrlWarn1 0 "WarningInd_NoWarning" 1 "WarningInd_Warning";
VAL_ 406 ObstacleMinimumDistanceRe1MinDstPosn 0 "Position_No" 1 "Position_InsideLeft" 2 "Position_InsideRight" 3 "Position_OutLeft" 4 "Position_OutRight" 5 "Position_SideLeft" 6 "Position_SideRight" 7 "Position_Reserved";
VAL_ 406 ObstacleMinimumDistanceRe1StopDispReq 0 "ReqSts1_NotReqd" 1 "ReqSts1_Reqd";
SIG_GROUP_ 37 AccrPedlPsd 1 : AccrPedlPsdAccrPedlPsd AccrPedlPsdChks AccrPedlPsdCntr AccrPedlPsdSts;
SIG_GROUP_ 11 AccrPedlRat 1 : AccrPedlRatAccrPedlRat AccrPedlRatChks AccrPedlRatCntr;
SIG_GROUP_ 890 AdpvBassEnhmtAdjmt 1 : AdpvBassEnhmtAdjmtOnOff1 AdpvBassEnhmtAdjmtsurroundlvlAdjmt;
SIG_GROUP_ 32 AmbTIndcdWithUnit 1 : AmbTIndcdWithUnitAmbTIndcd AmbTIndcdWithUnitAmbTIndcdUnit AmbTIndcdWithUnitQF;
SIG_GROUP_ 341 AmbTRaw 1 : AmbTRawAmbTVal AmbTRawQly;
SIG_GROUP_ 897 BgrndForAudOutChSts 1 : BgrndForAudOutChStsAudOutpCh1 BgrndForAudOutChStsAudOutpCh10 BgrndForAudOutChStsAudOutpCh11 BgrndForAudOutChStsAudOutpCh12 BgrndForAudOutChStsAudOutpCh2 BgrndForAudOutChStsAudOutpCh3 BgrndForAudOutChStsAudOutpCh4 BgrndForAudOutChStsAudOutpCh5 BgrndForAudOutChStsAudOutpCh6 BgrndForAudOutChStsAudOutpCh7 BgrndForAudOutChStsAudOutpCh8 BgrndForAudOutChStsAudOutpCh9;
SIG_GROUP_ 336 BgrndForAudOutpCh 1 : BgrndForAudOutpChAudOutpCh1 BgrndForAudOutpChAudOutpCh10 BgrndForAudOutpChAudOutpCh11 BgrndForAudOutpChAudOutpCh12 BgrndForAudOutpChAudOutpCh2 BgrndForAudOutpChAudOutpCh3 BgrndForAudOutpChAudOutpCh4 BgrndForAudOutpChAudOutpCh5 BgrndForAudOutpChAudOutpCh6 BgrndForAudOutpChAudOutpCh7 BgrndForAudOutpChAudOutpCh8 BgrndForAudOutpChAudOutpCh9;
SIG_GROUP_ 257 BrkPedlPsd 1 : BrkPedlPsdBrkPedlNotPsdSafe BrkPedlPsdBrkPedlPsd BrkPedlPsdChks BrkPedlPsdCntr BrkPedlPsdQf;
SIG_GROUP_ 398 BrkPedlrRat 1 : BrkPedlrRatPerc BrkPedlrRatQf;
SIG_GROUP_ 314 CmptmtTFrnt 1 : CmptmtTFrntCmptmtTFrnt CmptmtTFrntFanForCmptmtTRunng CmptmtTFrntQf;
SIG_GROUP_ 848 CrashStsSafe 1 : CrashStsSafeChks CrashStsSafeCntr CrashStsSafeSts;
SIG_GROUP_ 37 EngNSafe 1 : EngNSafeEngN EngNSafeEngNChks EngNSafeEngNCntr EngNSafeEngNGrdt;
SIG_GROUP_ 849 EngSt1WdSts 1 : EngSt1WdStsChks EngSt1WdStsCntr EngSt1WdStsEngSt1WdSts;
SIG_GROUP_ 820 ExtrLtgSts 1 : ExtrLtgStsAFS ExtrLtgStsAHBC ExtrLtgStsAHL ExtrLtgStsAllWL ExtrLtgStsApproach ExtrLtgStsChks ExtrLtgStsCntr ExtrLtgStsCornrgLi ExtrLtgStsDBL ExtrLtgStsDRL ExtrLtgStsFlash ExtrLtgStsFrntFog ExtrLtgStsGoodbye ExtrLtgStsHiBeam ExtrLtgStsHomeSafe ExtrLtgStsHWL ExtrLtgStsLoBeam ExtrLtgStsLtgShow ExtrLtgStsPosLiFrnt ExtrLtgStsPosLiRe ExtrLtgStsReFog ExtrLtgStsReverseLi ExtrLtgStsStopLi ExtrLtgStsTurnIndrLe ExtrLtgStsTurnIndrRi ExtrLtgStsWelcome;
SIG_GROUP_ 304 Fgrnd1ForAudOutpCh 1 : Fgrnd1ForAudOutpChAudOutpCh1 Fgrnd1ForAudOutpChAudOutpCh10 Fgrnd1ForAudOutpChAudOutpCh11 Fgrnd1ForAudOutpChAudOutpCh12 Fgrnd1ForAudOutpChAudOutpCh2 Fgrnd1ForAudOutpChAudOutpCh3 Fgrnd1ForAudOutpChAudOutpCh4 Fgrnd1ForAudOutpChAudOutpCh5 Fgrnd1ForAudOutpChAudOutpCh6 Fgrnd1ForAudOutpChAudOutpCh7 Fgrnd1ForAudOutpChAudOutpCh8 Fgrnd1ForAudOutpChAudOutpCh9;
SIG_GROUP_ 897 Fgrnd1stForAudOutpChSts 1 : Fgrnd1stForAudOutpChStsAudOutpCh1 Fgrnd1stForAudOutpChStsAudOutpCh10 Fgrnd1stForAudOutpChStsAudOutpCh11 Fgrnd1stForAudOutpChStsAudOutpCh12 Fgrnd1stForAudOutpChStsAudOutpCh2 Fgrnd1stForAudOutpChStsAudOutpCh3 Fgrnd1stForAudOutpChStsAudOutpCh4 Fgrnd1stForAudOutpChStsAudOutpCh5 Fgrnd1stForAudOutpChStsAudOutpCh6 Fgrnd1stForAudOutpChStsAudOutpCh7 Fgrnd1stForAudOutpChStsAudOutpCh8 Fgrnd1stForAudOutpChStsAudOutpCh9;
SIG_GROUP_ 272 Fgrnd2ForAudOutpCh 1 : Fgrnd2ForAudOutpChAudOutpCh1 Fgrnd2ForAudOutpChAudOutpCh10 Fgrnd2ForAudOutpChAudOutpCh11 Fgrnd2ForAudOutpChAudOutpCh12 Fgrnd2ForAudOutpChAudOutpCh2 Fgrnd2ForAudOutpChAudOutpCh3 Fgrnd2ForAudOutpChAudOutpCh4 Fgrnd2ForAudOutpChAudOutpCh5 Fgrnd2ForAudOutpChAudOutpCh6 Fgrnd2ForAudOutpChAudOutpCh7 Fgrnd2ForAudOutpChAudOutpCh8 Fgrnd2ForAudOutpChAudOutpCh9;
SIG_GROUP_ 897 Fgrnd2ndForAudOutpChSts 1 : Fgrnd2ndForAudOutpChStsAudOutpCh1 Fgrnd2ndForAudOutpChStsAudOutpCh10 Fgrnd2ndForAudOutpChStsAudOutpCh11 Fgrnd2ndForAudOutpChStsAudOutpCh12 Fgrnd2ndForAudOutpChStsAudOutpCh2 Fgrnd2ndForAudOutpChStsAudOutpCh3 Fgrnd2ndForAudOutpChStsAudOutpCh4 Fgrnd2ndForAudOutpChStsAudOutpCh5 Fgrnd2ndForAudOutpChStsAudOutpCh6 Fgrnd2ndForAudOutpChStsAudOutpCh7 Fgrnd2ndForAudOutpChStsAudOutpCh8 Fgrnd2ndForAudOutpChStsAudOutpCh9;
SIG_GROUP_ 346 IndcnUnit 1 : IndcnUnitClkFmt IndcnUnitDateFmt IndcnUnitDstLong IndcnUnitDstSho IndcnUnitFuCnsUnit IndcnUnitPUnit IndcnUnitSpdUnit IndcnUnitTUnit IndcnUnitVolUnit;
SIG_GROUP_ 7 IsgTqAct 1 : IsgTqActChks IsgTqActCntr IsgTqActIsgTqAct IsgTqActQualityFactor;
SIG_GROUP_ 326 LockgCenSts 1 : LockgCenStsLockSt LockgCenStsTrigSrc LockgCenStsUpdEve;
SIG_GROUP_ 406 ObstacleMinimumDistanceRe1 1 : ObstacleMinimumDistanceRe1MinDst ObstacleMinimumDistanceRe1MinDstPosn ObstacleMinimumDistanceRe1StopDispReq;
SIG_GROUP_ 593 PDCMDIDEcuCorePartNr 1 : PDCMDIDEcuCorePartNrByte0 PDCMDIDEcuCorePartNrByte1 PDCMDIDEcuCorePartNrByte2 PDCMDIDEcuCorePartNrByte3 PDCMDIDEcuCorePartNrByte4 PDCMDIDEcuCorePartNrByte5 PDCMDIDEcuCorePartNrByte6 PDCMDIDEcuCorePartNrByte7;
SIG_GROUP_ 596 PDCMDIDEcuCorePartNrGL 1 : PDCMDIDEcuCorePartNrGLByte0 PDCMDIDEcuCorePartNrGLByte1 PDCMDIDEcuCorePartNrGLByte2 PDCMDIDEcuCorePartNrGLByte3 PDCMDIDEcuCorePartNrGLByte4 PDCMDIDEcuCorePartNrGLByte5 PDCMDIDEcuCorePartNrGLByte6 PDCMDIDEcuCorePartNrGLByte7;
SIG_GROUP_ 594 PDCMDIDEcuDeliveryPartNr 1 : PDCMDIDEcuDeliveryPartNrByte0 PDCMDIDEcuDeliveryPartNrByte1 PDCMDIDEcuDeliveryPartNrByte2 PDCMDIDEcuDeliveryPartNrByte3 PDCMDIDEcuDeliveryPartNrByte4 PDCMDIDEcuDeliveryPartNrByte5 PDCMDIDEcuDeliveryPartNrByte6 PDCMDIDEcuDeliveryPartNrByte7;
SIG_GROUP_ 595 PDCMDIDEcuDeliveryPartNrGL 1 : PDCMDIDEcuDeliveryPartNrGLByte0 PDCMDIDEcuDeliveryPartNrGLByte1 PDCMDIDEcuDeliveryPartNrGLByte2 PDCMDIDEcuDeliveryPartNrGLByte3 PDCMDIDEcuDeliveryPartNrGLByte4 PDCMDIDEcuDeliveryPartNrGLByte5 PDCMDIDEcuDeliveryPartNrGLByte6 PDCMDIDEcuDeliveryPartNrGLByte7;
SIG_GROUP_ 597 PDCMDIDEcuSoftwarePartNr 1 : PDCMDIDEcuSoftwarePartNrByte0 PDCMDIDEcuSoftwarePartNrByte1 PDCMDIDEcuSoftwarePartNrByte2 PDCMDIDEcuSoftwarePartNrByte3 PDCMDIDEcuSoftwarePartNrByte4 PDCMDIDEcuSoftwarePartNrByte5 PDCMDIDEcuSoftwarePartNrByte6 PDCMDIDEcuSoftwarePartNrByte7;
SIG_GROUP_ 598 PDCMDIDEcuSoftwarePartNrGL2 1 : PDCMDIDEcuSoftwarePartNrGL2Byte0 PDCMDIDEcuSoftwarePartNrGL2Byte1 PDCMDIDEcuSoftwarePartNrGL2Byte2 PDCMDIDEcuSoftwarePartNrGL2Byte3 PDCMDIDEcuSoftwarePartNrGL2Byte4 PDCMDIDEcuSoftwarePartNrGL2Byte5 PDCMDIDEcuSoftwarePartNrGL2Byte6 PDCMDIDEcuSoftwarePartNrGL2Byte7;
SIG_GROUP_ 1187 PDCMPartNo10Cmpl 1 : PDCMPartNo10CmplEndSgn1 PDCMPartNo10CmplEndSgn2 PDCMPartNo10CmplEndSgn3 PDCMPartNo10CmplNr1 PDCMPartNo10CmplNr2 PDCMPartNo10CmplNr3 PDCMPartNo10CmplNr4 PDCMPartNo10CmplNr5;
SIG_GROUP_ 1188 PDCMPartNoCmpl 1 : PDCMPartNoCmplEndSgn1 PDCMPartNoCmplEndSgn2 PDCMPartNoCmplEndSgn3 PDCMPartNoCmplNr1 PDCMPartNoCmplNr2 PDCMPartNoCmplNr3 PDCMPartNoCmplNr4;
SIG_GROUP_ 1189 PDCMSerNo 1 : PDCMSerNoNr1 PDCMSerNoNr2 PDCMSerNoNr3 PDCMSerNoNr4;
SIG_GROUP_ 357 PtTqSetSafe 1 : PtTqSetSafeChks PtTqSetSafeCntr PtTqSetSafeGrdtNeg PtTqSetSafeGrdtPos PtTqSetSafeReq;
SIG_GROUP_ 848 RecOfImpct 1 : RecOfImpctCrashFrnt RecOfImpctCrashOffroadA RecOfImpctCrashOffroadD RecOfImpctCrashOffroadRT RecOfImpctCrashOffroadRTsevere RecOfImpctCrashPed RecOfImpctCrashRe RecOfImpctCrashRollovr RecOfImpctCrashSideLe RecOfImpctCrashSideRi RecOfImpctCrashState RecOfImpctImpctDvx RecOfImpctImpctDvy RecOfImpctImpctRollAg RecOfImpctVehOri;
SIG_GROUP_ 362 RoadIncln 1 : RoadInclnQly RoadInclnRoadIncln;
SIG_GROUP_ 85 SteerWhlSnsr 1 : SteerWhlSnsrAg SteerWhlSnsrAgSpd SteerWhlSnsrChks SteerWhlSnsrCntr SteerWhlSnsrQf;
SIG_GROUP_ 890 ThreeDimSurAdjmt 1 : ThreeDimSurAdjmtOnOff1 ThreeDimSurAdjmtsurroundlvlAdjmt;
SIG_GROUP_ 352 TiAndDateIndcn 1 : TiAndDateIndcnDataValid TiAndDateIndcnDay TiAndDateIndcnHr1 TiAndDateIndcnMins1 TiAndDateIndcnMth1 TiAndDateIndcnSec1 TiAndDateIndcnYr1;
SIG_GROUP_ 890 TwoDimSurAdjmt 1 : TwoDimSurAdjmtOnOff1 TwoDimSurAdjmtsurroundlvlAdjmt;
SIG_GROUP_ 362 VehBattU 1 : VehBattUSysU VehBattUSysUQf;
SIG_GROUP_ 529 VehCfgPrm 1 : VehCfgPrmBlkIDBytePosn1 VehCfgPrmCCPBytePosn2 VehCfgPrmCCPBytePosn3 VehCfgPrmCCPBytePosn4 VehCfgPrmCCPBytePosn5 VehCfgPrmCCPBytePosn6 VehCfgPrmCCPBytePosn7 VehCfgPrmCCPBytePosn8;
SIG_GROUP_ 560 VehCfgPrmExt 1 : VehCfgPrmExtBlkIDBytePosn1 VehCfgPrmExtCCPBytePosn2 VehCfgPrmExtCCPBytePosn3 VehCfgPrmExtCCPBytePosn4 VehCfgPrmExtCCPBytePosn5 VehCfgPrmExtCCPBytePosn6 VehCfgPrmExtCCPBytePosn7 VehCfgPrmExtCCPBytePosn8;
SIG_GROUP_ 849 VehModMngtGlbSafe1 1 : VehModMngtGlbSafe1CarModSts1 VehModMngtGlbSafe1CarModSubtypWdCarModSubtyp VehModMngtGlbSafe1Chks VehModMngtGlbSafe1Cntr VehModMngtGlbSafe1EgyLvlElecMai VehModMngtGlbSafe1EgyLvlElecSubtyp VehModMngtGlbSafe1FltEgyCnsWdSts VehModMngtGlbSafe1PwrLvlElecMai VehModMngtGlbSafe1PwrLvlElecSubtyp VehModMngtGlbSafe1UsgModSts;
SIG_GROUP_ 362 VehMtnSt 1 : VehMtnStChks VehMtnStCntr VehMtnStVehMtnSt;
SIG_GROUP_ 32 VehSpdLgt 1 : VehSpdLgtA VehSpdLgtChks VehSpdLgtCntr VehSpdLgtQf;
SIG_GROUP_ 613 Vin 1 : VinBlockNr VinVINSignalPos1 VinVINSignalPos2 VinVINSignalPos3 VinVINSignalPos4 VinVINSignalPos5 VinVINSignalPos6 VinVINSignalPos7;
SIG_GROUP_ 353 VirtVenue 1 : VirtVenueMod VirtVenueOnOff1;
SIG_GROUP_ 384 WhlRotToothCntr 1 : WhlRotToothCntrChks WhlRotToothCntrCntr WhlRotToothCntrFrntLe WhlRotToothCntrFrntRi WhlRotToothCntrReLe WhlRotToothCntrReRi;
SIG_GROUP_ 257 WhlSpdCircumlFrnt 1 : WhlSpdCircumlFrntChks WhlSpdCircumlFrntCntr WhlSpdCircumlFrntLe WhlSpdCircumlFrntLeQf WhlSpdCircumlFrntRiQf WhlSpdCircumlFrntWhlSpdCircumlFrntRi;
SIG_GROUP_ 41 WhlSpdCircumlRe 1 : WhlSpdCircumlReChks WhlSpdCircumlReCntr WhlSpdCircumlReLe WhlSpdCircumlReLeQf WhlSpdCircumlReRi WhlSpdCircumlReRiQf;
